VERSION ""

NS_ :

BS_:

BU_: Turbocharger OnBoardDataLogger OffBoardDiagnosticTool2 OffBoardDiagnosticTool1 FileServer ParkingBrakeController SeatControl2 FanDriveController SteeringColumnUnit CommunicationUnitRadio CommunicationUnitSatellite CommunicationUnitCellular PropulsionBatteryCharger ChassisController2 ChassisController1 EngineValveControl AuxiliaryHeater2 AuxiliaryHeater1 ClutchUnit RampControl InformationSystem1 SuspensionSystemController2 OilSensor VehicleDynamicStability ExhaustEmissionController TransmissionDisplay2 TransmissionDisplay1 ClimateControl2 WaterPumpController RearAxleSteeringController LightingOperatorControl SeatController1 IgnitionController2 IgnitionController1 TirePressureController CabController2 CabController1 PneumaticSystemController SuspensionSystemController1 HydraulicPumpController EnduranceBrakingSystem RetarderExhaustEngine2 OnBoardDiagnosticUnit HeadwayController RetarderExhaustEngine1 CabDisplay1 ManagementComputer VirtualTerminal OffVehicleGateway PowerTakeOffFront HitchControl AuxiliaryValveControl BodyController TractorTrailerBridge1 StarterSystem ElectricalSystem VehicleSecurity VehicleNavigation AerodynamicControl ElectricalChargingSystem ClimateControl1 TripRecorder InstrumentCluster SuspensionDriveAxle2 SuspensionDriveAxle1 SuspensionSteerAxle SteeringController FuelSystem CruiseControl RetarderDriveline RetarderEngine BrakesDriveAxle2 BrakesDriveAxle1 BrakesSystemController BrakesSteerAxle AxleDrive2 AxleDrive1 AxleSteering PowerTakeOff ShiftConsoleSecondary ShiftConsolePrimary Transmission2 Transmission1 Engine2 Engine1

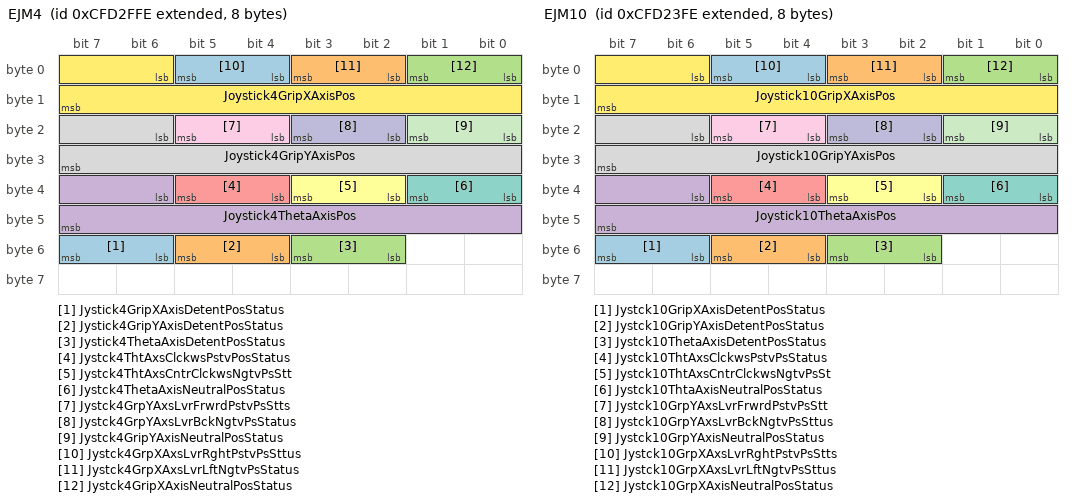
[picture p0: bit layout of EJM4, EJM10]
BO_ 2365403134 EJM4: 8 Vector__XXX
 SG_ Jystick4GripXAxisDetentPosStatus : 54|2@1+ (1,0) [0|3] "" Vector__XXX
 SG_ Jystick4GripYAxisDetentPosStatus : 52|2@1+ (1,0) [0|3] "" Vector__XXX
 SG_ Jystick4ThetaAxisDetentPosStatus : 50|2@1+ (1,0) [0|3] "" Vector__XXX
 SG_ Joystick4ThetaAxisPos : 38|10@1+ (1,0) [0|102] "%" Vector__XXX
 SG_ Jystck4ThtAxsClckwsPstvPosStatus : 36|2@1+ (1,0) [0|3] "" Vector__XXX
 SG_ Jystck4ThtAxsCntrClckwsNgtvPsStt : 34|2@1+ (1,0) [0|3] "" Vector__XXX
 SG_ Jystck4ThetaAxisNeutralPosStatus : 32|2@1+ (1,0) [0|3] "" Vector__XXX
 SG_ Joystick4GripYAxisPos : 22|10@1+ (1,0) [0|102] "%" Vector__XXX
 SG_ Jystck4GrpYAxsLvrFrwrdPstvPsStts : 20|2@1+ (1,0) [0|3] "" Vector__XXX
 SG_ Jystck4GrpYAxsLvrBckNgtvPsStatus : 18|2@1+ (1,0) [0|3] "" Vector__XXX
 SG_ Jystck4GripYAxisNeutralPosStatus : 16|2@1+ (1,0) [0|3] "" Vector__XXX
 SG_ Joystick4GripXAxisPos : 6|10@1+ (1,0) [0|102] "%" Vector__XXX
 SG_ Jystck4GrpXAxsLvrRghtPstvPsSttus : 4|2@1+ (1,0) [0|3] "" Vector__XXX
 SG_ Jystck4GrpXAxsLvrLftNgtvPsStatus : 2|2@1+ (1,0) [0|3] "" Vector__XXX
 SG_ Jystck4GripXAxisNeutralPosStatus : 0|2@1+ (1,0) [0|3] "" Vector__XXX

BO_ 2365400062 EJM10: 8 Vector__XXX
 SG_ Jystck10GripXAxisDetentPosStatus : 54|2@1+ (1,0) [0|3] "" Vector__XXX
 SG_ Jystck10GripYAxisDetentPosStatus : 52|2@1+ (1,0) [0|3] "" Vector__XXX
 SG_ Jystck10ThetaAxisDetentPosStatus : 50|2@1+ (1,0) [0|3] "" Vector__XXX
 SG_ Joystick10ThetaAxisPos : 38|10@1+ (1,0) [0|102] "%" Vector__XXX
 SG_ Jystck10ThtAxsClckwsPstvPsStatus : 36|2@1+ (1,0) [0|3] "" Vector__XXX
 SG_ Jystck10ThtAxsCntrClckwsNgtvPsSt : 34|2@1+ (1,0) [0|3] "" Vector__XXX
 SG_ Jystck10ThtaAxisNeutralPosStatus : 32|2@1+ (1,0) [0|3] "" Vector__XXX
 SG_ Joystick10GripYAxisPos : 22|10@1+ (1,0) [0|102] "%" Vector__XXX
 SG_ Jystck10GrpYAxsLvrFrwrdPstvPsStt : 20|2@1+ (1,0) [0|3] "" Vector__XXX
 SG_ Jystck10GrpYAxsLvrBckNgtvPsSttus : 18|2@1+ (1,0) [0|3] "" Vector__XXX
 SG_ Jystck10GrpYAxisNeutralPosStatus : 16|2@1+ (1,0) [0|3] "" Vector__XXX
 SG_ Joystick10GripXAxisPos : 6|10@1+ (1,0) [0|102] "%" Vector__XXX
 SG_ Jystck10GrpXAxsLvrRghtPstvPsStts : 4|2@1+ (1,0) [0|3] "" Vector__XXX
 SG_ Jystck10GrpXAxsLvrLftNgtvPsSttus : 2|2@1+ (1,0) [0|3] "" Vector__XXX
 SG_ Jystck10GrpXAxisNeutralPosStatus : 0|2@1+ (1,0) [0|3] "" Vector__XXX

BO_ 2566713598 EFS2: 8 Vector__XXX
 SG_ EngFuelFilterIntakeAbsPress : 0|8@1+ (2,0) [0|500] "kPa" Vector__XXX

BO_ 2499604478 EFL_P11: 8 Vector__XXX
 SG_ EngExhstGsRcrcltn1OutletAbsPress : 16|16@1+ (0.1,0) [0|6425.5] "kPa" Vector__XXX
 SG_ EngExhstGsRcrcltn1IntakeAbsPress : 0|16@1+ (0.1,0) [0|6425.5] "kPa" Vector__XXX

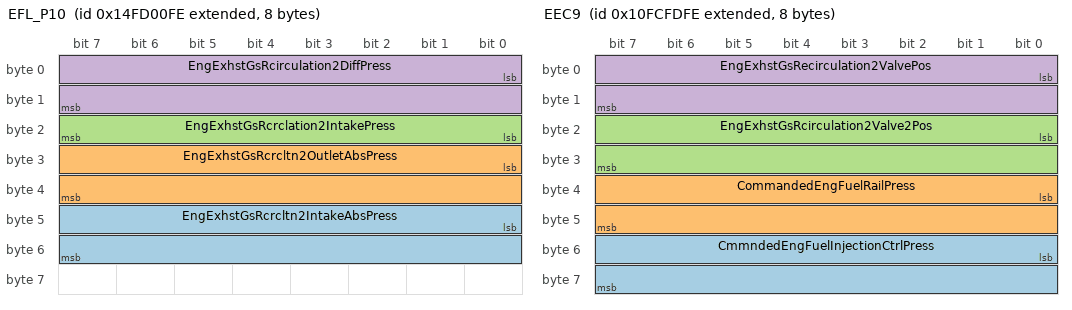
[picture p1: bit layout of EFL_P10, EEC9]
BO_ 2499608830 EFL_P10: 8 Vector__XXX
 SG_ EngExhstGsRcrcltn2IntakeAbsPress : 40|16@1+ (0.1,0) [0|6425.5] "kPa" Vector__XXX
 SG_ EngExhstGsRcrcltn2OutletAbsPress : 24|16@1+ (0.1,0) [0|6425.5] "kPa" Vector__XXX
 SG_ EngExhstGsRcrclation2IntakePress : 16|8@1+ (2,0) [0|500] "kPa" Vector__XXX
 SG_ EngExhstGsRcirculation2DiffPress : 0|16@1+ (0.0078124659559567,-250) [-250|251.99] "kPa" Vector__XXX

BO_ 2432499198 EEC9: 8 Vector__XXX
 SG_ CmmndedEngFuelInjectionCtrlPress : 48|16@1+ (0.0039063107929344,0) [0|251] "MPa" Vector__XXX
 SG_ CommandedEngFuelRailPress : 32|16@1+ (0.0039063107929344,0) [0|251] "MPa" Vector__XXX
 SG_ EngExhstGsRcirculation2Valve2Pos : 16|16@1+ (0.0025,0) [0|160.6375] "%" Vector__XXX
 SG_ EngExhstGsRecirculation2ValvePos : 0|16@1+ (0.0025,0) [0|160.6375] "%" Vector__XXX

BO_ 2633825022 EEC11: 8 Vector__XXX
 SG_ EngExhstGsRcrculation2Valve2Ctrl : 16|16@1+ (0.0025,0) [0|160.6375] "%" Vector__XXX
 SG_ EngExhstGsRcirculation2ValveCtrl : 0|16@1+ (0.0025,0) [0|160.6375] "%" Vector__XXX

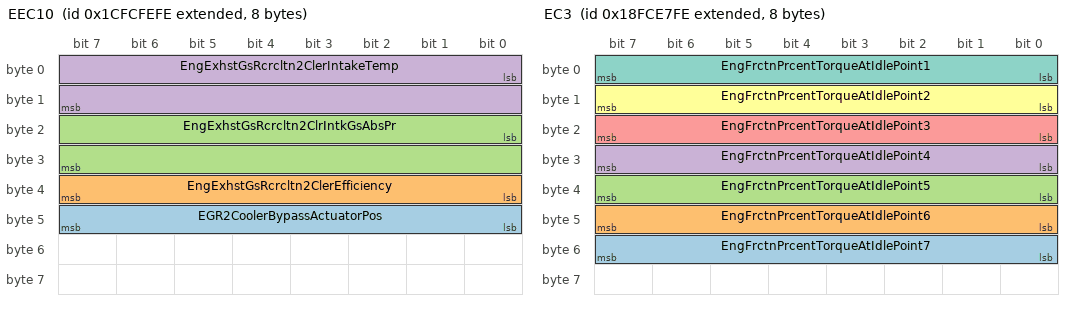
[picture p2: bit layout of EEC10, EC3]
BO_ 2633826046 EEC10: 8 Vector__XXX
 SG_ EGR2CoolerBypassActuatorPos : 40|8@1+ (0.4,0) [0|100] "%" Vector__XXX
 SG_ EngExhstGsRcrcltn2ClerEfficiency : 32|8@1+ (0.4,0) [0|100] "%" Vector__XXX
 SG_ EngExhstGsRcrcltn2ClrIntkGsAbsPr : 16|16@1+ (0.5,0) [0|32127.5] "kPa" Vector__XXX
 SG_ EngExhstGsRcrcltn2ClerIntakeTemp : 0|16@1+ (0.03125,-273) [-273|1734.96875] "deg C" Vector__XXX

BO_ 2566711294 EC3: 8 Vector__XXX
 SG_ EngFrctnPrcentTorqueAtIdlePoint7 : 48|8@1+ (1,-125) [-125|125] "%" Vector__XXX
 SG_ EngFrctnPrcentTorqueAtIdlePoint6 : 40|8@1+ (1,-125) [-125|125] "%" Vector__XXX
 SG_ EngFrctnPrcentTorqueAtIdlePoint5 : 32|8@1+ (1,-125) [-125|125] "%" Vector__XXX
 SG_ EngFrctnPrcentTorqueAtIdlePoint4 : 24|8@1+ (1,-125) [-125|125] "%" Vector__XXX
 SG_ EngFrctnPrcentTorqueAtIdlePoint3 : 16|8@1+ (1,-125) [-125|125] "%" Vector__XXX
 SG_ EngFrctnPrcentTorqueAtIdlePoint2 : 8|8@1+ (1,-125) [-125|125] "%" Vector__XXX
 SG_ EngFrctnPrcentTorqueAtIdlePoint1 : 0|8@1+ (1,-125) [-125|125] "%" Vector__XXX

BO_ 2566749438 DPFC1: 8 Vector__XXX
 SG_ DslPrtcltFltrActvRgnrtnFrcdSttus : 53|3@1+ (1,0) [0|7] "" Vector__XXX
 SG_ ExhaustSystemHighTempLampCmd : 50|3@1+ (1,0) [0|7] "" Vector__XXX
 SG_ DslPrtcltFltrAtmtcActvRgnrtnIntt : 48|2@1+ (1,0) [0|3] "" Vector__XXX
 SG_ DslPrtcltFltrActvRgnrtnInhbtdDTV : 46|2@1+ (1,0) [0|3] "" Vector__XXX
 SG_ DslPrtcltFltrActvRgnrtnInhbtdDTE : 44|2@1+ (1,0) [0|3] "" Vector__XXX
 SG_ DslPrtcltFltrActvRgnrtnInhb_0000 : 42|2@1+ (1,0) [0|3] "" Vector__XXX
 SG_ DslPrtcltFltrActvRgnrtnInhbtdDTT : 40|2@1+ (1,0) [0|3] "" Vector__XXX
 SG_ DslPrtcltFltrActvRgnrtn_DTS_02 : 38|2@1+ (1,0) [0|3] "" Vector__XXX
 SG_ DslPrtcltFltrActvRgnrtn_DTS_01 : 36|2@1+ (1,0) [0|3] "" Vector__XXX
 SG_ DslPrtcltFltrActvRgnrtnInhbtdDTL : 34|2@1+ (1,0) [0|3] "" Vector__XXX
 SG_ DslPrtcltFltrActvRgnrtnInhb_0001 : 32|2@1+ (1,0) [0|3] "" Vector__XXX
 SG_ DslPrtcltFltrActvRgnrtnInhb_0002 : 30|2@1+ (1,0) [0|3] "" Vector__XXX
 SG_ DslPrtcltFltrActvRgnrtnInhbtdDTO : 28|2@1+ (1,0) [0|3] "" Vector__XXX
 SG_ DslPrtcltFltrActvRgnrtnInhbtdDTA : 26|2@1+ (1,0) [0|3] "" Vector__XXX
 SG_ DslPrtcltFltrActvRgnrtnInhbtdDTP : 24|2@1+ (1,0) [0|3] "" Vector__XXX
 SG_ DslPrtcltFltrActvRgnrtnInhbtdDTS : 22|2@1+ (1,0) [0|3] "" Vector__XXX
 SG_ DslPrtcltFltrActvRgnrtnInhbtdDTC : 20|2@1+ (1,0) [0|3] "" Vector__XXX
 SG_ DslPrtcltFltrActvRgnrtnInhbtdDTI : 18|2@1+ (1,0) [0|3] "" Vector__XXX
 SG_ DslPrtcltFltrActvRgnrtnInhbtdStt : 16|2@1+ (1,0) [0|3] "" Vector__XXX
 SG_ DieselParticulateFilterStatus : 12|3@1+ (1,0) [0|7] "" Vector__XXX
 SG_ DslPrtcltFltrActvRgnrationStatus : 10|2@1+ (1,0) [0|3] "" Vector__XXX
 SG_ DslPrtcltFltrPssvRgnrationStatus : 8|2@1+ (1,0) [0|3] "" Vector__XXX
 SG_ DieselParticulateFilterLampCmd : 0|3@1+ (1,0) [0|7] "" Vector__XXX

BO_ 2566715646 DPF2S2: 8 Vector__XXX
 SG_ DslPrtculateFilter2SootSignalMin : 32|16@1+ (0.0025,0) [0|160.6375] "%" Vector__XXX
 SG_ DslPrtculateFilter2SootSignalMax : 16|16@1+ (0.0025,0) [0|160.6375] "%" Vector__XXX
 SG_ DslPrtcltFltr2StSgnlStndrdDvtion : 0|16@1+ (0.0025,0) [0|160.6375] "%" Vector__XXX

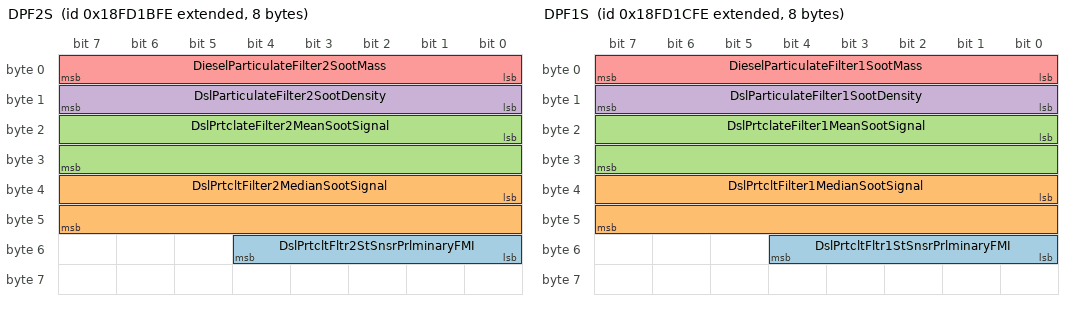
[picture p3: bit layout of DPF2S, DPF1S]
BO_ 2566724606 DPF2S: 8 Vector__XXX
 SG_ DslPrtcltFltr2StSnsrPrlminaryFMI : 48|5@1+ (1,0) [0|31] "" Vector__XXX
 SG_ DslPrtcltFilter2MedianSootSignal : 32|16@1+ (0.0025,0) [0|160.6375] "%" Vector__XXX
 SG_ DslPrtclateFilter2MeanSootSignal : 16|16@1+ (0.0025,0) [0|160.6375] "%" Vector__XXX
 SG_ DslParticulateFilter2SootDensity : 8|8@1+ (0.08,0) [0|20] "g/L" Vector__XXX
 SG_ DieselParticulateFilter2SootMass : 0|8@1+ (4,0) [0|1000] "g" Vector__XXX

BO_ 2566715902 DPF1S2: 8 Vector__XXX
 SG_ DslPrtculateFilter1SootSignalMin : 32|16@1+ (0.0025,0) [0|160.6375] "%" Vector__XXX
 SG_ DslPrtculateFilter1SootSignalMax : 16|16@1+ (0.0025,0) [0|160.6375] "%" Vector__XXX
 SG_ DslPrtcltFltr1StSgnlStndrdDvtion : 0|16@1+ (0.0025,0) [0|160.6375] "%" Vector__XXX

BO_ 2566724862 DPF1S: 8 Vector__XXX
 SG_ DslPrtcltFltr1StSnsrPrlminaryFMI : 48|5@1+ (1,0) [0|31] "" Vector__XXX
 SG_ DslPrtcltFilter1MedianSootSignal : 32|16@1+ (0.0025,0) [0|160.6375] "%" Vector__XXX
 SG_ DslPrtclateFilter1MeanSootSignal : 16|16@1+ (0.0025,0) [0|160.6375] "%" Vector__XXX
 SG_ DslParticulateFilter1SootDensity : 8|8@1+ (0.08,0) [0|20] "g/L" Vector__XXX
 SG_ DieselParticulateFilter1SootMass : 0|8@1+ (4,0) [0|1000] "g" Vector__XXX

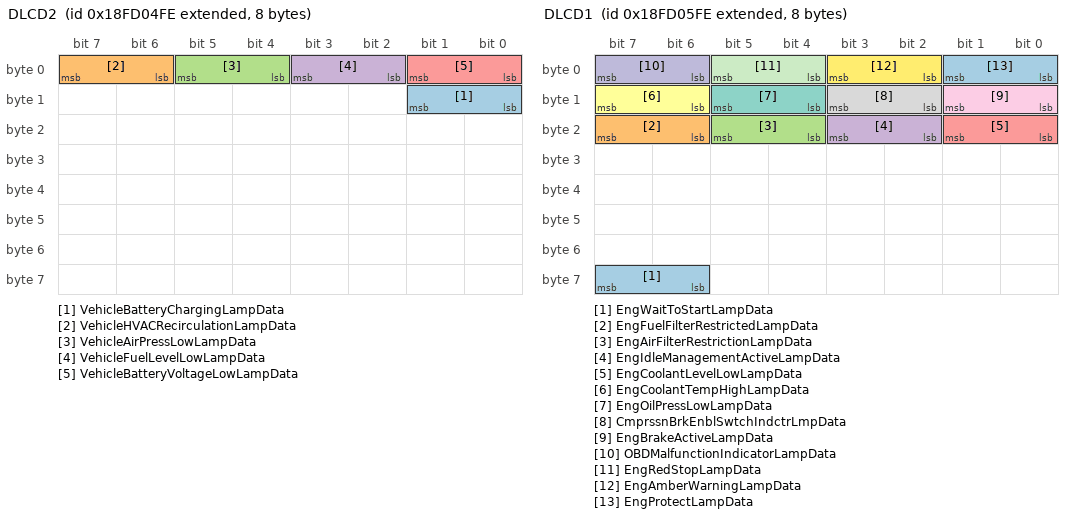
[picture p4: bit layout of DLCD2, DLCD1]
BO_ 2566718718 DLCD2: 8 Vector__XXX
 SG_ VehicleBatteryChargingLampData : 8|2@1+ (1,0) [0|3] "" Vector__XXX
 SG_ VehicleHVACRecirculationLampData : 6|2@1+ (1,0) [0|3] "" Vector__XXX
 SG_ VehicleAirPressLowLampData : 4|2@1+ (1,0) [0|3] "" Vector__XXX
 SG_ VehicleFuelLevelLowLampData : 2|2@1+ (1,0) [0|3] "" Vector__XXX
 SG_ VehicleBatteryVoltageLowLampData : 0|2@1+ (1,0) [0|3] "" Vector__XXX

BO_ 2566718974 DLCD1: 8 Vector__XXX
 SG_ EngWaitToStartLampData : 62|2@1+ (1,0) [0|3] "" Vector__XXX
 SG_ EngFuelFilterRestrictedLampData : 22|2@1+ (1,0) [0|3] "" Vector__XXX
 SG_ EngAirFilterRestrictionLampData : 20|2@1+ (1,0) [0|3] "" Vector__XXX
 SG_ EngIdleManagementActiveLampData : 18|2@1+ (1,0) [0|3] "" Vector__XXX
 SG_ EngCoolantLevelLowLampData : 16|2@1+ (1,0) [0|3] "" Vector__XXX
 SG_ EngCoolantTempHighLampData : 14|2@1+ (1,0) [0|3] "" Vector__XXX
 SG_ EngOilPressLowLampData : 12|2@1+ (1,0) [0|3] "" Vector__XXX
 SG_ CmprssnBrkEnblSwtchIndctrLmpData : 10|2@1+ (1,0) [0|3] "" Vector__XXX
 SG_ EngBrakeActiveLampData : 8|2@1+ (1,0) [0|3] "" Vector__XXX
 SG_ OBDMalfunctionIndicatorLampData : 6|2@1+ (1,0) [0|3] "" Vector__XXX
 SG_ EngRedStopLampData : 4|2@1+ (1,0) [0|3] "" Vector__XXX
 SG_ EngAmberWarningLampData : 2|2@1+ (1,0) [0|3] "" Vector__XXX
 SG_ EngProtectLampData : 0|2@1+ (1,0) [0|3] "" Vector__XXX

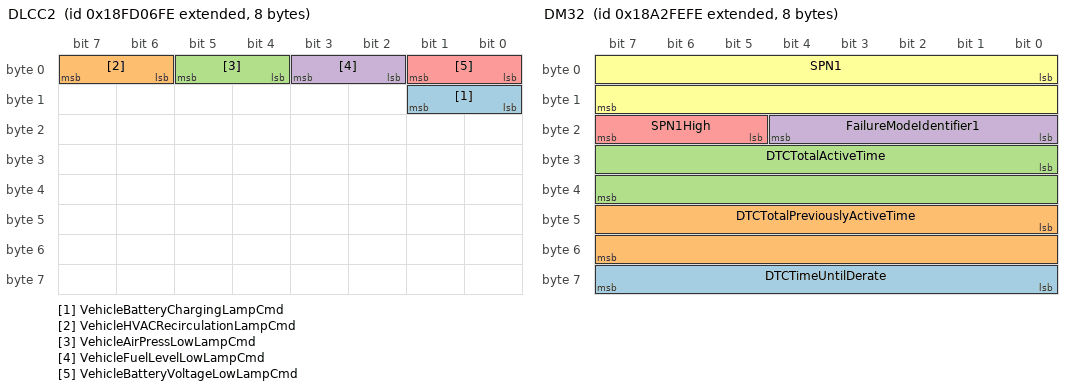
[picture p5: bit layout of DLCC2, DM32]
BO_ 2566719230 DLCC2: 8 Vector__XXX
 SG_ VehicleBatteryChargingLampCmd : 8|2@1+ (1,0) [0|3] "" Vector__XXX
 SG_ VehicleHVACRecirculationLampCmd : 6|2@1+ (1,0) [0|3] "" Vector__XXX
 SG_ VehicleAirPressLowLampCmd : 4|2@1+ (1,0) [0|3] "" Vector__XXX
 SG_ VehicleFuelLevelLowLampCmd : 2|2@1+ (1,0) [0|3] "" Vector__XXX
 SG_ VehicleBatteryVoltageLowLampCmd : 0|2@1+ (1,0) [0|3] "" Vector__XXX

BO_ 2560818942 DM32: 8 Vector__XXX
 SG_ DTCTimeUntilDerate : 56|8@1+ (0.25,0) [0|62.5] "hr" Vector__XXX
 SG_ DTCTotalPreviouslyActiveTime : 40|16@1+ (0.2,0) [0|12851] "hr" Vector__XXX
 SG_ DTCTotalActiveTime : 24|16@1+ (0.2,0) [0|12851] "hr" Vector__XXX
 SG_ FailureModeIdentifier1 : 16|5@1+ (1,0) [0|0] "" Vector__XXX
 SG_ SPN1High : 21|3@1+ (1,0) [0|7] "" Vector__XXX
 SG_ SPN1 : 0|16@1+ (1,0) [0|65536] "" Vector__XXX

BO_ 2561212158 DISP1: 8 Vector__XXX
 SG_ TextDisplayIndex : 16|8@1+ (1,0) [0|250] "" Vector__XXX
 SG_ TextDisplayInstructions : 0|4@1+ (1,0) [0|15] "" Vector__XXX

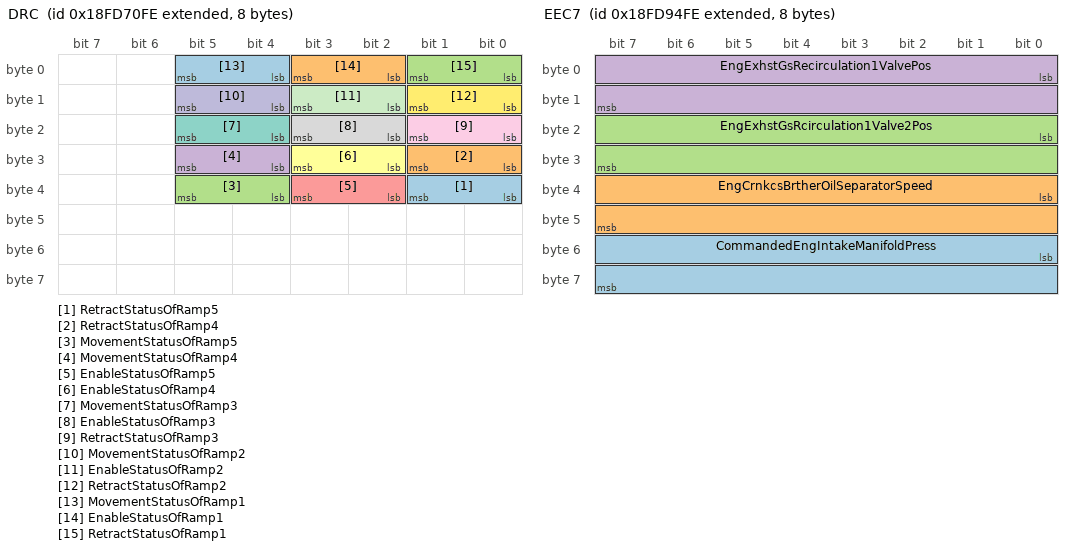
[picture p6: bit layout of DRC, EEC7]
BO_ 2566746366 DRC: 8 Vector__XXX
 SG_ RetractStatusOfRamp5 : 32|2@1+ (1,0) [0|3] "" Vector__XXX
 SG_ RetractStatusOfRamp4 : 24|2@1+ (1,0) [0|3] "" Vector__XXX
 SG_ MovementStatusOfRamp5 : 36|2@1+ (1,0) [0|3] "" Vector__XXX
 SG_ MovementStatusOfRamp4 : 28|2@1+ (1,0) [0|3] "" Vector__XXX
 SG_ EnableStatusOfRamp5 : 34|2@1+ (1,0) [0|3] "" Vector__XXX
 SG_ EnableStatusOfRamp4 : 26|2@1+ (1,0) [0|3] "" Vector__XXX
 SG_ MovementStatusOfRamp3 : 20|2@1+ (1,0) [0|3] "" Vector__XXX
 SG_ EnableStatusOfRamp3 : 18|2@1+ (1,0) [0|3] "" Vector__XXX
 SG_ RetractStatusOfRamp3 : 16|2@1+ (1,0) [0|3] "" Vector__XXX
 SG_ MovementStatusOfRamp2 : 12|2@1+ (1,0) [0|3] "" Vector__XXX
 SG_ EnableStatusOfRamp2 : 10|2@1+ (1,0) [0|3] "" Vector__XXX
 SG_ RetractStatusOfRamp2 : 8|2@1+ (1,0) [0|3] "" Vector__XXX
 SG_ MovementStatusOfRamp1 : 4|2@1+ (1,0) [0|3] "" Vector__XXX
 SG_ EnableStatusOfRamp1 : 2|2@1+ (1,0) [0|3] "" Vector__XXX
 SG_ RetractStatusOfRamp1 : 0|2@1+ (1,0) [0|3] "" Vector__XXX

BO_ 2566750206 EC2: 8 Vector__XXX
 SG_ MaxCrankAttemptsPerStartAttempt : 0|8@1+ (1,0) [0|250] "" Vector__XXX

BO_ 2566755582 EEC7: 8 Vector__XXX
 SG_ CommandedEngIntakeManifoldPress : 48|16@1+ (0.125,0) [0|8031.875] "kPa" Vector__XXX
 SG_ EngCrnkcsBrtherOilSeparatorSpeed : 32|16@1+ (1,0) [0|64255] "rpm" Vector__XXX
 SG_ EngExhstGsRcirculation1Valve2Pos : 16|16@1+ (0.0025,0) [0|160.6375] "%" Vector__XXX
 SG_ EngExhstGsRecirculation1ValvePos : 0|16@1+ (0.0025,0) [0|160.6375] "%" Vector__XXX

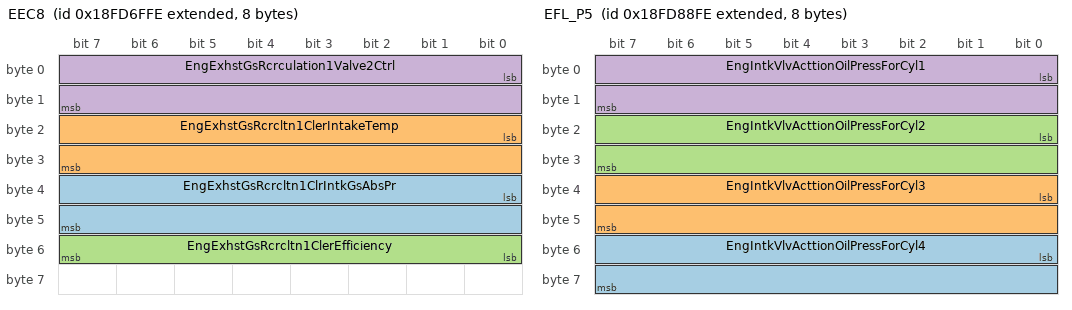
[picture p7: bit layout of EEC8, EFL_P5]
BO_ 2566746110 EEC8: 8 Vector__XXX
 SG_ EngExhstGsRcrcltn1ClrIntkGsAbsPr : 32|16@1+ (0.5,0) [0|32127.5] "kPa" Vector__XXX
 SG_ EngExhstGsRcrcltn1ClerIntakeTemp : 16|16@1+ (0.03125,-273) [-273|1734.96875] "deg C" Vector__XXX
 SG_ EngExhstGsRcrcltn1ClerEfficiency : 48|8@1+ (1,0) [0|100] "%" Vector__XXX
 SG_ EngExhstGsRcrculation1Valve2Ctrl : 0|16@1+ (1,0) [0|160.6375] "%" Vector__XXX

BO_ 2566752510 EFL_P5: 8 Vector__XXX
 SG_ EngIntkVlvActtionOilPressForCyl4 : 48|16@1+ (0.1,0) [0|6425.5] "kPa" Vector__XXX
 SG_ EngIntkVlvActtionOilPressForCyl3 : 32|16@1+ (0.1,0) [0|6425.5] "kPa" Vector__XXX
 SG_ EngIntkVlvActtionOilPressForCyl2 : 16|16@1+ (0.1,0) [0|6425.5] "kPa" Vector__XXX
 SG_ EngIntkVlvActtionOilPressForCyl1 : 0|16@1+ (0.1,0) [0|6425.5] "kPa" Vector__XXX

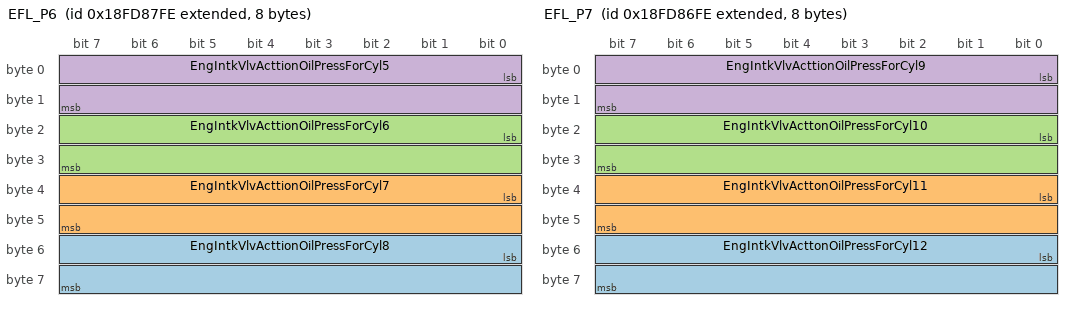
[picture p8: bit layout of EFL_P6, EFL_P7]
BO_ 2566752254 EFL_P6: 8 Vector__XXX
 SG_ EngIntkVlvActtionOilPressForCyl8 : 48|16@1+ (0.1,0) [0|6425.5] "kPa" Vector__XXX
 SG_ EngIntkVlvActtionOilPressForCyl7 : 32|16@1+ (0.1,0) [0|6425.5] "kPa" Vector__XXX
 SG_ EngIntkVlvActtionOilPressForCyl6 : 16|16@1+ (0.1,0) [0|6425.5] "kPa" Vector__XXX
 SG_ EngIntkVlvActtionOilPressForCyl5 : 0|16@1+ (0.1,0) [0|6425.5] "kPa" Vector__XXX

BO_ 2566751998 EFL_P7: 8 Vector__XXX
 SG_ EngIntkVlvActtonOilPressForCyl12 : 48|16@1+ (0.1,0) [0|6425.5] "kPa" Vector__XXX
 SG_ EngIntkVlvActtonOilPressForCyl11 : 32|16@1+ (0.1,0) [0|6425.5] "kPa" Vector__XXX
 SG_ EngIntkVlvActtonOilPressForCyl10 : 16|16@1+ (0.1,0) [0|6425.5] "kPa" Vector__XXX
 SG_ EngIntkVlvActtionOilPressForCyl9 : 0|16@1+ (0.1,0) [0|6425.5] "kPa" Vector__XXX

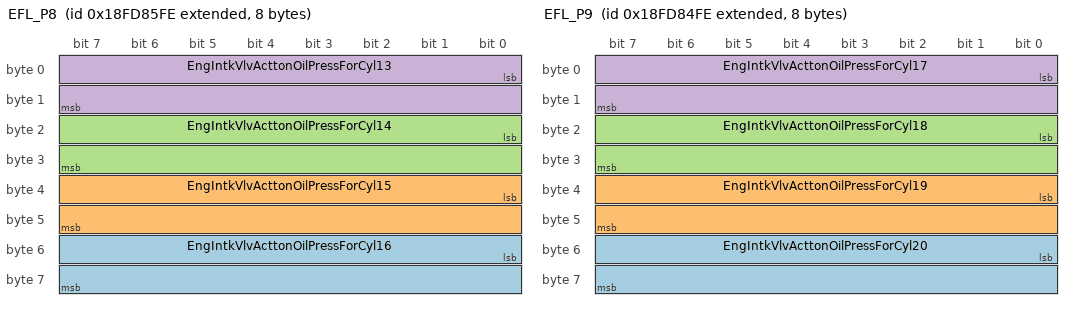
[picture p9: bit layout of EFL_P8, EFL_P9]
BO_ 2566751742 EFL_P8: 8 Vector__XXX
 SG_ EngIntkVlvActtonOilPressForCyl16 : 48|16@1+ (0.1,0) [0|6425.5] "kPa" Vector__XXX
 SG_ EngIntkVlvActtonOilPressForCyl15 : 32|16@1+ (0.1,0) [0|6425.5] "kPa" Vector__XXX
 SG_ EngIntkVlvActtonOilPressForCyl14 : 16|16@1+ (0.1,0) [0|6425.5] "kPa" Vector__XXX
 SG_ EngIntkVlvActtonOilPressForCyl13 : 0|16@1+ (0.1,0) [0|6425.5] "kPa" Vector__XXX

BO_ 2566751486 EFL_P9: 8 Vector__XXX
 SG_ EngIntkVlvActtonOilPressForCyl20 : 48|16@1+ (0.1,0) [0|6425.5] "kPa" Vector__XXX
 SG_ EngIntkVlvActtonOilPressForCyl19 : 32|16@1+ (0.1,0) [0|6425.5] "kPa" Vector__XXX
 SG_ EngIntkVlvActtonOilPressForCyl18 : 16|16@1+ (0.1,0) [0|6425.5] "kPa" Vector__XXX
 SG_ EngIntkVlvActtonOilPressForCyl17 : 0|16@1+ (0.1,0) [0|6425.5] "kPa" Vector__XXX

BO_ 2499641854 EGRBV: 8 Vector__XXX
 SG_ EGR1CoolerBypassActuatorPostion : 0|8@1+ (0.4,0) [0|100] "%" Vector__XXX

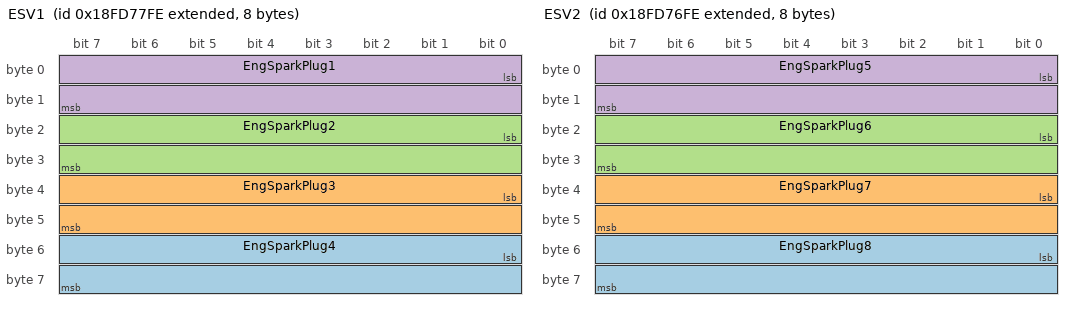
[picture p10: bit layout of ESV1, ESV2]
BO_ 2566748158 ESV1: 8 Vector__XXX
 SG_ EngSparkPlug4 : 48|16@1+ (1,0) [0|64255] "Volts" Vector__XXX
 SG_ EngSparkPlug3 : 32|16@1+ (1,0) [0|64255] "Volts" Vector__XXX
 SG_ EngSparkPlug2 : 16|16@1+ (1,0) [0|64255] "Volts" Vector__XXX
 SG_ EngSparkPlug1 : 0|16@1+ (1,0) [0|64255] "Volts" Vector__XXX

BO_ 2566747902 ESV2: 8 Vector__XXX
 SG_ EngSparkPlug8 : 48|16@1+ (1,0) [0|64255] "Volts" Vector__XXX
 SG_ EngSparkPlug7 : 32|16@1+ (1,0) [0|64255] "Volts" Vector__XXX
 SG_ EngSparkPlug6 : 16|16@1+ (1,0) [0|64255] "Volts" Vector__XXX
 SG_ EngSparkPlug5 : 0|16@1+ (1,0) [0|64255] "Volts" Vector__XXX

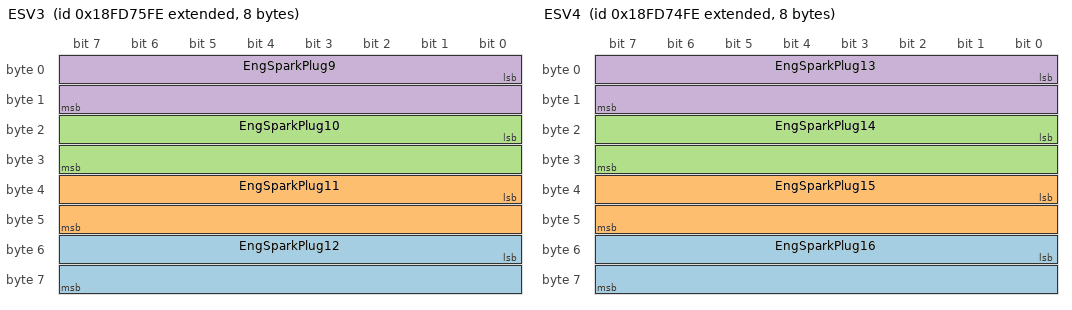
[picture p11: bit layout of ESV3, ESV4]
BO_ 2566747646 ESV3: 8 Vector__XXX
 SG_ EngSparkPlug12 : 48|16@1+ (1,0) [0|64255] "Volts" Vector__XXX
 SG_ EngSparkPlug11 : 32|16@1+ (1,0) [0|64255] "Volts" Vector__XXX
 SG_ EngSparkPlug10 : 16|16@1+ (1,0) [0|64255] "Volts" Vector__XXX
 SG_ EngSparkPlug9 : 0|16@1+ (1,0) [0|64255] "Volts" Vector__XXX

BO_ 2566747390 ESV4: 8 Vector__XXX
 SG_ EngSparkPlug16 : 48|16@1+ (1,0) [0|64255] "Volts" Vector__XXX
 SG_ EngSparkPlug15 : 32|16@1+ (1,0) [0|64255] "Volts" Vector__XXX
 SG_ EngSparkPlug14 : 16|16@1+ (1,0) [0|64255] "Volts" Vector__XXX
 SG_ EngSparkPlug13 : 0|16@1+ (1,0) [0|64255] "Volts" Vector__XXX

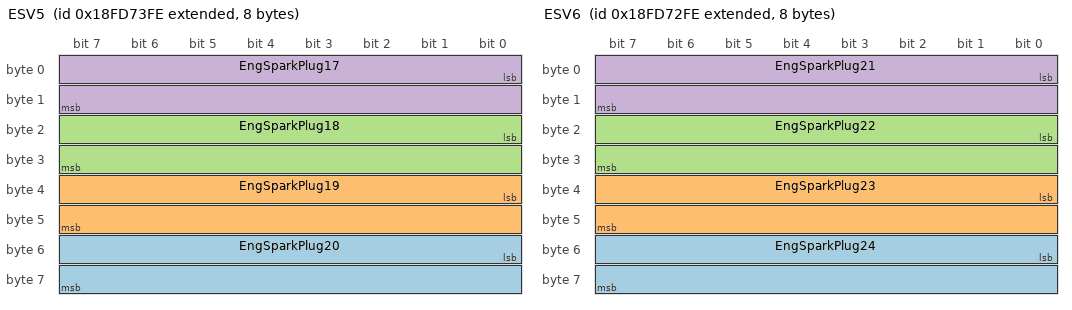
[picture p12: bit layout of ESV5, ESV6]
BO_ 2566747134 ESV5: 8 Vector__XXX
 SG_ EngSparkPlug20 : 48|16@1+ (1,0) [0|64255] "Volts" Vector__XXX
 SG_ EngSparkPlug19 : 32|16@1+ (1,0) [0|64255] "Volts" Vector__XXX
 SG_ EngSparkPlug18 : 16|16@1+ (1,0) [0|64255] "Volts" Vector__XXX
 SG_ EngSparkPlug17 : 0|16@1+ (1,0) [0|64255] "Volts" Vector__XXX

BO_ 2566746878 ESV6: 8 Vector__XXX
 SG_ EngSparkPlug24 : 48|16@1+ (1,0) [0|64255] "Volts" Vector__XXX
 SG_ EngSparkPlug23 : 32|16@1+ (1,0) [0|64255] "Volts" Vector__XXX
 SG_ EngSparkPlug22 : 16|16@1+ (1,0) [0|64255] "Volts" Vector__XXX
 SG_ EngSparkPlug21 : 0|16@1+ (1,0) [0|64255] "Volts" Vector__XXX

BO_ 2561277694 FLIC: 8 Vector__XXX
 SG_ LaneDepartureWarningEnableCmd : 0|2@1+ (1,0) [0|3] "" Vector__XXX

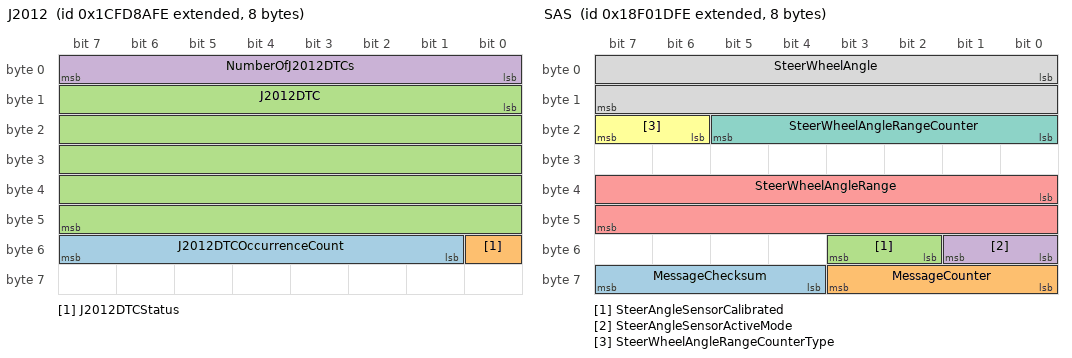
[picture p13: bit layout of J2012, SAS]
BO_ 2633861886 J2012: 8 Vector__XXX
 SG_ J2012DTCOccurrenceCount : 49|7@1+ (1,0) [0|127] "" Vector__XXX
 SG_ J2012DTCStatus : 48|1@1+ (1,0) [0|1] "" Vector__XXX
 SG_ J2012DTC : 8|40@1+ (1,0) [0|255] "per byte" Vector__XXX
 SG_ NumberOfJ2012DTCs : 0|8@1+ (1,0) [0|250] "" Vector__XXX

BO_ 2565873150 SAS: 8 Vector__XXX
 SG_ MessageChecksum : 60|4@1+ (1,0) [0|15] "" Vector__XXX
 SG_ MessageCounter : 56|4@1+ (1,0) [0|15] "" Vector__XXX
 SG_ SteerAngleSensorCalibrated : 50|2@1+ (1,0) [0|3] "" Vector__XXX
 SG_ SteerAngleSensorActiveMode : 48|2@1+ (1,0) [0|3] "" Vector__XXX
 SG_ SteerWheelAngleRange : 32|16@1+ (0.00097654657225119,-31.374) [-31.374|31.374] "rad" Vector__XXX
 SG_ SteerWheelAngleRangeCounterType : 22|2@1+ (1,0) [0|3] "" Vector__XXX
 SG_ SteerWheelAngleRangeCounter : 16|6@1+ (1,-32) [-32|29] "ranges" Vector__XXX
 SG_ SteerWheelAngle : 0|16@1+ (0.00097654657225119,-31.374) [-31.374|31.374] "rad" Vector__XXX

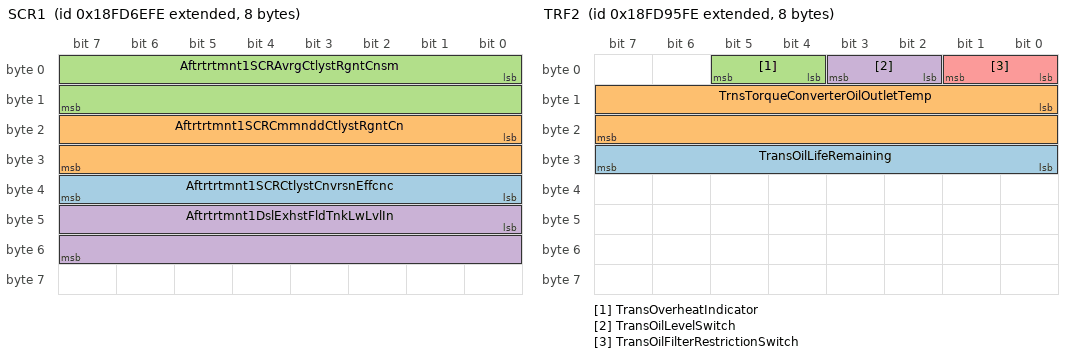
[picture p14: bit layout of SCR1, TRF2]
BO_ 2566745854 SCR1: 8 Vector__XXX
 SG_ Aftrtrtmnt1SCRCtlystCnvrsnEffcnc : 32|8@1+ (0.4,0) [0|100] "%" Vector__XXX
 SG_ Aftrtrtmnt1SCRCmmnddCtlystRgntCn : 16|16@1+ (1,0) [0|3212.75] "L/h" Vector__XXX
 SG_ Aftrtrtmnt1SCRAvrgCtlystRgntCnsm : 0|16@1+ (0.05,0) [0|3212.75] "L/h" Vector__XXX
 SG_ Aftrtrtmnt1DslExhstFldTnkLwLvlIn : 40|16@1+ (1,0) [0|64255] "km" Vector__XXX

BO_ 2566751230 TCI: 8 Vector__XXX
 SG_ TransferCaseStatus : 0|3@1+ (1,0) [0|7] "" Vector__XXX

BO_ 2566755838 TRF2: 8 Vector__XXX
 SG_ TransOilLifeRemaining : 24|8@1+ (0.4,0) [0|100] "%" Vector__XXX
 SG_ TrnsTorqueConverterOilOutletTemp : 8|16@1+ (0.03125,-273) [-273|1734.96875] "deg C" Vector__XXX
 SG_ TransOverheatIndicator : 4|2@1+ (1,0) [0|3] "" Vector__XXX
 SG_ TransOilLevelSwitch : 2|2@1+ (1,0) [0|3] "" Vector__XXX
 SG_ TransOilFilterRestrictionSwitch : 0|2@1+ (1,0) [0|3] "" Vector__XXX

BO_ 2566752766 VDS2: 8 Vector__XXX
 SG_ VehicleRoll : 0|16@1+ (0.0078124659559567,-200) [-200|301.99] "deg" Vector__XXX

BO_ 2633938942 LF: 10 Vector__XXX
 SG_ TotalEngCruiseTime : 48|32@1+ (0.05,0) [0|210554060.75] "hr" Vector__XXX
 SG_ TotalDriveAverageLoadFactor : 40|8@1+ (0.4,0) [0|100] "%" Vector__XXX
 SG_ TripDriveAverageLoadFactor : 32|8@1+ (0.4,0) [0|100] "%" Vector__XXX
 SG_ TripAverageEngSpeed : 16|16@1+ (0.125,0) [0|8031.875] "rpm" Vector__XXX
 SG_ TripMaxEngSpeed : 0|16@1+ (0.125,0) [0|8031.875] "rpm" Vector__XXX

BO_ 2566799614 LD: 8 Vector__XXX
 SG_ ImplementRearWorkLight : 62|2@1+ (1,0) [0|3] "" Vector__XXX
 SG_ ImplementLeftForwardWorkLight : 60|2@1+ (1,0) [0|3] "" Vector__XXX
 SG_ ImplementRightForwardWorkLight : 58|2@1+ (1,0) [0|3] "" Vector__XXX
 SG_ ImplementLeftFacingWorkLight : 54|2@1+ (1,0) [0|3] "" Vector__XXX
 SG_ ImplementRightFacingWorkLight : 52|2@1+ (1,0) [0|3] "" Vector__XXX
 SG_ ImplementOEMOption1Light : 50|2@1+ (1,0) [0|3] "" Vector__XXX
 SG_ ImplementOEMOption2Light : 48|2@1+ (1,0) [0|3] "" Vector__XXX
 SG_ TrctorFrontHighMountedWorkLights : 46|2@1+ (1,0) [0|3] "" Vector__XXX
 SG_ TractorFrontLowMountedWorkLights : 44|2@1+ (1,0) [0|3] "" Vector__XXX
 SG_ TractorSideHighMountedWorkLights : 42|2@1+ (1,0) [0|3] "" Vector__XXX
 SG_ TractorSideLowMountedWorkLights : 40|2@1+ (1,0) [0|3] "" Vector__XXX
 SG_ TractorRearHighMountedWorkLights : 38|2@1+ (1,0) [0|3] "" Vector__XXX
 SG_ TractorRearLowMountedWorkLights : 36|2@1+ (1,0) [0|3] "" Vector__XXX
 SG_ TrctorUndersideMountedWorkLights : 34|2@1+ (1,0) [0|3] "" Vector__XXX
 SG_ RearFogLights : 32|2@1+ (1,0) [0|3] "" Vector__XXX
 SG_ TractorMarkerLight : 30|2@1+ (1,0) [0|3] "" Vector__XXX
 SG_ ImplementMarkerLight : 28|2@1+ (1,0) [0|3] "" Vector__XXX
 SG_ TractorClearanceLight : 26|2@1+ (1,0) [0|3] "" Vector__XXX
 SG_ ImplementClearanceLight : 24|2@1+ (1,0) [0|3] "" Vector__XXX
 SG_ LeftStopLight : 22|2@1+ (1,0) [0|3] "" Vector__XXX
 SG_ RightStopLight : 20|2@1+ (1,0) [0|3] "" Vector__XXX
 SG_ CenterStopLight : 18|2@1+ (1,0) [0|3] "" Vector__XXX
 SG_ BackUpLightAndAlarmHorn : 16|2@1+ (1,0) [0|3] "" Vector__XXX
 SG_ LeftTurnSignalLights : 14|2@1+ (1,0) [0|3] "" Vector__XXX
 SG_ RightTurnSignalLights : 12|2@1+ (1,0) [0|3] "" Vector__XXX
 SG_ RotatingBeaconLight : 10|2@1+ (1,0) [0|3] "" Vector__XXX
 SG_ TractorFrontFogLights : 8|2@1+ (1,0) [0|3] "" Vector__XXX
 SG_ HighBeamHeadLightData : 6|2@1+ (1,0) [0|3] "" Vector__XXX
 SG_ LowBeamHeadLightData : 4|2@1+ (1,0) [0|3] "" Vector__XXX
 SG_ AltBeamHeadLightData : 2|2@1+ (1,0) [0|3] "" Vector__XXX
 SG_ RunningLight : 0|2@1+ (1,0) [0|3] "" Vector__XXX

BO_ 2365473278 LC: 8 Vector__XXX
 SG_ ImplementRearWorkLightCmd : 62|2@1+ (1,0) [0|3] "" Vector__XXX
 SG_ ImplementLeftForwardWorkLightCmd : 60|2@1+ (1,0) [0|3] "" Vector__XXX
 SG_ ImplmentRightForwardWorkLightCmd : 58|2@1+ (1,0) [0|3] "" Vector__XXX
 SG_ LightingDataRqCmd : 56|2@1+ (1,0) [0|3] "" Vector__XXX
 SG_ ImplementLeftFacingWorkLightCmd : 54|2@1+ (1,0) [0|3] "" Vector__XXX
 SG_ ImplementRightFacingWorkLightCmd : 52|2@1+ (1,0) [0|3] "" Vector__XXX
 SG_ ImplementOEMOption1LightCmd : 50|2@1+ (1,0) [0|3] "" Vector__XXX
 SG_ ImplementOEMOption2LightCmd : 48|2@1+ (1,0) [0|3] "" Vector__XXX
 SG_ TrctrFrntHghMountedWorkLightsCmd : 46|2@1+ (1,0) [0|3] "" Vector__XXX
 SG_ TrctrFrntLowMountedWorkLightsCmd : 44|2@1+ (1,0) [0|3] "" Vector__XXX
 SG_ TrctrSdeHighMountedWorkLightsCmd : 42|2@1+ (1,0) [0|3] "" Vector__XXX
 SG_ TrctrSideLowMountedWorkLightsCmd : 40|2@1+ (1,0) [0|3] "" Vector__XXX
 SG_ TrctrRarHighMountedWorkLightsCmd : 38|2@1+ (1,0) [0|3] "" Vector__XXX
 SG_ TrctrRearLowMountedWorkLightsCmd : 36|2@1+ (1,0) [0|3] "" Vector__XXX
 SG_ TrctrUndrsdeMountedWorkLightsCmd : 34|2@1+ (1,0) [0|3] "" Vector__XXX
 SG_ RearFogLightCmd : 32|2@1+ (1,0) [0|3] "" Vector__XXX
 SG_ TractorMarkerLightCmd : 30|2@1+ (1,0) [0|3] "" Vector__XXX
 SG_ ImplementMarkerLightCmd : 28|2@1+ (1,0) [0|3] "" Vector__XXX
 SG_ TractorClearanceLightCmd : 26|2@1+ (1,0) [0|3] "" Vector__XXX
 SG_ ImplementClearanceLightCmd : 24|2@1+ (1,0) [0|3] "" Vector__XXX
 SG_ LeftStopLightCmd : 22|2@1+ (1,0) [0|3] "" Vector__XXX
 SG_ RightStopLightCmd : 20|2@1+ (1,0) [0|3] "" Vector__XXX
 SG_ CenterStopLightCmd : 18|2@1+ (1,0) [0|3] "" Vector__XXX
 SG_ BackUpLightAndAlarmHornCmd : 16|2@1+ (1,0) [0|3] "" Vector__XXX
 SG_ LeftTurnSignalLightsCmd : 14|2@1+ (1,0) [0|3] "" Vector__XXX
 SG_ RightTurnSignalLightsCmd : 12|2@1+ (1,0) [0|3] "" Vector__XXX
 SG_ RotatingBeaconLightCmd : 10|2@1+ (1,0) [0|3] "" Vector__XXX
 SG_ TractorFrontFogLightsCmd : 8|2@1+ (1,0) [0|3] "" Vector__XXX
 SG_ HighBeamHeadLightCmd : 6|2@1+ (1,0) [0|3] "" Vector__XXX
 SG_ LowBeamHeadLightCmd : 4|2@1+ (1,0) [0|3] "" Vector__XXX
 SG_ AltBeamHeadLightCmd : 2|2@1+ (1,0) [0|3] "" Vector__XXX
 SG_ RunningLightCmd : 0|2@1+ (1,0) [0|3] "" Vector__XXX

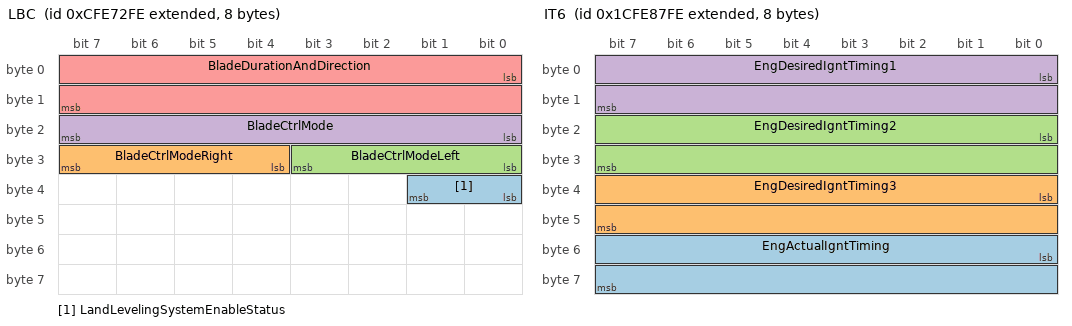
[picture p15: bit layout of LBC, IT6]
BO_ 2365485822 LBC: 8 Vector__XXX
 SG_ LandLevelingSystemEnableStatus : 32|2@1+ (1,0) [0|3] "" Vector__XXX
 SG_ BladeCtrlModeRight : 28|4@1+ (1,0) [0|15] "" Vector__XXX
 SG_ BladeCtrlModeLeft : 24|4@1+ (1,0) [0|15] "" Vector__XXX
 SG_ BladeCtrlMode : 16|8@1+ (1,0) [0|255] "" Vector__XXX
 SG_ BladeDurationAndDirection : 0|16@1+ (1,-3276.8) [-3276.8|3148.7] "sec" Vector__XXX

BO_ 2633926654 IT6: 8 Vector__XXX
 SG_ EngActualIgntTiming : 48|16@1+ (1,-200) [-200|301.99] "deg" Vector__XXX
 SG_ EngDesiredIgntTiming3 : 32|16@1+ (1,-200) [-200|301.99] "deg" Vector__XXX
 SG_ EngDesiredIgntTiming2 : 16|16@1+ (1,-200) [-200|301.99] "deg" Vector__XXX
 SG_ EngDesiredIgntTiming1 : 0|16@1+ (1,-200) [-200|301.99] "deg" Vector__XXX

BO_ 2633926398 IT5: 8 Vector__XXX
 SG_ EngCyl20IgntTiming : 48|16@1+ (1,-200) [-200|301.99] "deg" Vector__XXX
 SG_ EngCyl19IgntTiming : 32|16@1+ (1,-200) [-200|301.99] "deg" Vector__XXX
 SG_ EngCyl18IgntTiming : 16|16@1+ (1,-200) [-200|301.99] "deg" Vector__XXX
 SG_ EngCyl17IgntTiming : 0|16@1+ (1,-200) [-200|301.99] "deg" Vector__XXX

BO_ 2633926142 IT4: 8 Vector__XXX
 SG_ EngCyl16IgntTiming : 48|16@1+ (1,-200) [-200|301.99] "deg" Vector__XXX
 SG_ EngCyl15IgntTiming : 32|16@1+ (1,-200) [-200|301.99] "deg" Vector__XXX
 SG_ EngCyl14IgntTiming : 16|16@1+ (1,-200) [-200|301.99] "deg" Vector__XXX
 SG_ EngCyl13IgntTiming : 0|16@1+ (1,-200) [-200|301.99] "deg" Vector__XXX

BO_ 2633925886 IT3: 8 Vector__XXX
 SG_ EngCyl12IgntTiming : 48|16@1+ (1,-200) [-200|301.99] "deg" Vector__XXX
 SG_ EngCyl11IgntTiming : 32|16@1+ (1,-200) [-200|301.99] "deg" Vector__XXX
 SG_ EngCyl10IgntTiming : 16|16@1+ (1,-200) [-200|301.99] "deg" Vector__XXX
 SG_ EngCyl9IgntTiming : 0|16@1+ (1,-200) [-200|301.99] "deg" Vector__XXX

BO_ 2633925630 IT2: 8 Vector__XXX
 SG_ EngCyl8IgntTiming : 48|16@1+ (1,-200) [-200|301.99] "deg" Vector__XXX
 SG_ EngCyl7IgntTiming : 32|16@1+ (1,-200) [-200|301.99] "deg" Vector__XXX
 SG_ EngCyl6IgntTiming : 16|16@1+ (1,-200) [-200|301.99] "deg" Vector__XXX
 SG_ EngCyl5IgntTiming : 0|16@1+ (1,-200) [-200|301.99] "deg" Vector__XXX

BO_ 2633925374 IT1: 8 Vector__XXX
 SG_ EngCyl4IgntTiming : 48|16@1+ (1,-200) [-200|301.99] "deg" Vector__XXX
 SG_ EngCyl3IgntTiming : 32|16@1+ (1,-200) [-200|301.99] "deg" Vector__XXX
 SG_ EngCyl2IgntTiming : 16|16@1+ (1,-200) [-200|301.99] "deg" Vector__XXX
 SG_ EngCyl1IgntTiming : 0|16@1+ (1,-200) [-200|301.99] "deg" Vector__XXX

BO_ 2633927422 ISO3: 8 Vector__XXX
 SG_ EngCyl20IgntTransSecondOutput : 24|8@1+ (1,-125) [-125|125] "%" Vector__XXX
 SG_ EngCyl19IgntTransSecondOutput : 16|8@1+ (1,-125) [-125|125] "%" Vector__XXX
 SG_ EngCyl18IgntTransSecondOutput : 8|8@1+ (1,-125) [-125|125] "%" Vector__XXX
 SG_ EngCyl17IgntTransSecondOutput : 0|8@1+ (1,-125) [-125|125] "%" Vector__XXX

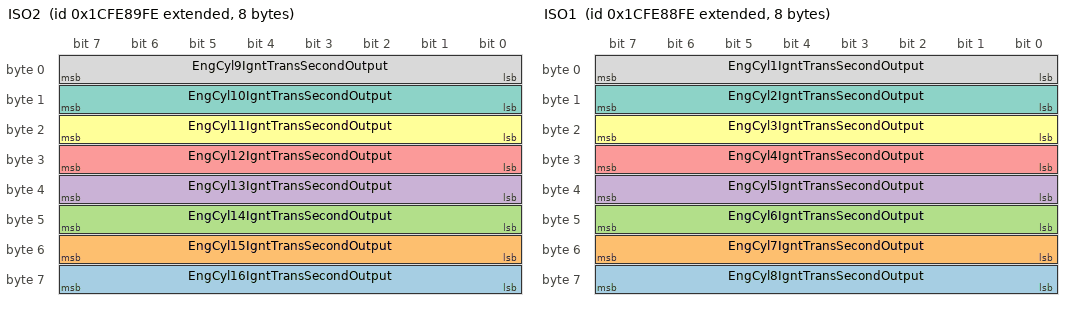
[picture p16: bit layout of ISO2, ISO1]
BO_ 2633927166 ISO2: 8 Vector__XXX
 SG_ EngCyl16IgntTransSecondOutput : 56|8@1+ (1,-125) [-125|125] "%" Vector__XXX
 SG_ EngCyl15IgntTransSecondOutput : 48|8@1+ (1,-125) [-125|125] "%" Vector__XXX
 SG_ EngCyl14IgntTransSecondOutput : 40|8@1+ (1,-125) [-125|125] "%" Vector__XXX
 SG_ EngCyl13IgntTransSecondOutput : 32|8@1+ (1,-125) [-125|125] "%" Vector__XXX
 SG_ EngCyl12IgntTransSecondOutput : 24|8@1+ (1,-125) [-125|125] "%" Vector__XXX
 SG_ EngCyl11IgntTransSecondOutput : 16|8@1+ (1,-125) [-125|125] "%" Vector__XXX
 SG_ EngCyl10IgntTransSecondOutput : 8|8@1+ (1,-125) [-125|125] "%" Vector__XXX
 SG_ EngCyl9IgntTransSecondOutput : 0|8@1+ (1,-125) [-125|125] "%" Vector__XXX

BO_ 2633926910 ISO1: 8 Vector__XXX
 SG_ EngCyl8IgntTransSecondOutput : 56|8@1+ (1,-125) [-125|125] "%" Vector__XXX
 SG_ EngCyl7IgntTransSecondOutput : 48|8@1+ (1,-125) [-125|125] "%" Vector__XXX
 SG_ EngCyl6IgntTransSecondOutput : 40|8@1+ (1,-125) [-125|125] "%" Vector__XXX
 SG_ EngCyl5IgntTransSecondOutput : 32|8@1+ (1,-125) [-125|125] "%" Vector__XXX
 SG_ EngCyl4IgntTransSecondOutput : 24|8@1+ (1,-125) [-125|125] "%" Vector__XXX
 SG_ EngCyl3IgntTransSecondOutput : 16|8@1+ (1,-125) [-125|125] "%" Vector__XXX
 SG_ EngCyl2IgntTransSecondOutput : 8|8@1+ (1,-125) [-125|125] "%" Vector__XXX
 SG_ EngCyl1IgntTransSecondOutput : 0|8@1+ (1,-125) [-125|125] "%" Vector__XXX

BO_ 2566768894 ISCS: 8 Vector__XXX
 SG_ EngOprtrPrmryIntrmdtSpdSlctState : 0|4@1+ (1,0) [0|15] "" Vector__XXX

BO_ 2566769406 ISC: 8 Vector__XXX
 SG_ EngOprtrPrmryIntrmdteSpeedSelect : 0|4@1+ (1,0) [0|15] "" Vector__XXX

BO_ 2566839550 IO: 8 Vector__XXX
 SG_ EngTotalIdleHours : 32|32@1+ (0.05,0) [0|210554060.75] "hr" Vector__XXX
 SG_ EngTotalIdleFuelUsed : 0|32@1+ (0.5,0) [0|2105540607.5] "L" Vector__XXX

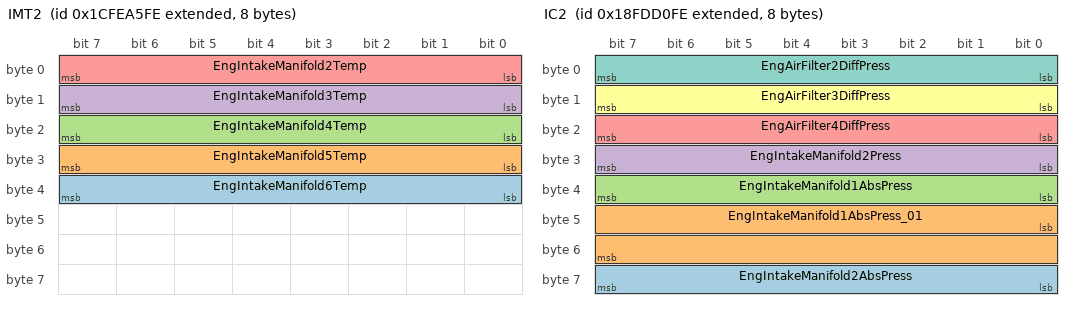
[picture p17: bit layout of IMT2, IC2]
BO_ 2633934334 IMT2: 8 Vector__XXX
 SG_ EngIntakeManifold6Temp : 32|8@1+ (1,-40) [-40|210] "deg C" Vector__XXX
 SG_ EngIntakeManifold5Temp : 24|8@1+ (1,-40) [-40|210] "deg C" Vector__XXX
 SG_ EngIntakeManifold4Temp : 16|8@1+ (1,-40) [-40|210] "deg C" Vector__XXX
 SG_ EngIntakeManifold3Temp : 8|8@1+ (1,-40) [-40|210] "deg C" Vector__XXX
 SG_ EngIntakeManifold2Temp : 0|8@1+ (1,-40) [-40|210] "deg C" Vector__XXX

BO_ 2566825726 IMT1: 8 Vector__XXX
 SG_ EngTurbo4BoostPress : 48|16@1+ (0.125,0) [0|8031.875] "kPa" Vector__XXX
 SG_ EngTurbo3BoostPress : 32|16@1+ (0.125,0) [0|8031.875] "kPa" Vector__XXX
 SG_ EngTurbo2BoostPress : 16|16@1+ (0.125,0) [0|8031.875] "kPa" Vector__XXX
 SG_ EngTurbo1BoostPress : 0|16@1+ (0.125,0) [0|8031.875] "kPa" Vector__XXX

BO_ 2566770942 IC2: 8 Vector__XXX
 SG_ EngIntakeManifold2AbsPress : 56|8@1+ (2,0) [0|500] "kPa" Vector__XXX
 SG_ EngIntakeManifold1AbsPress_01 : 40|16@1+ (0.1,0) [0|6425.5] "kPa" Vector__XXX
 SG_ EngIntakeManifold1AbsPress : 32|8@1+ (2,0) [0|500] "kPa" Vector__XXX
 SG_ EngIntakeManifold2Press : 24|8@1+ (2,0) [0|500] "kPa" Vector__XXX
 SG_ EngAirFilter4DiffPress : 16|8@1+ (0.05,0) [0|12.5] "kPa" Vector__XXX
 SG_ EngAirFilter3DiffPress : 8|8@1+ (0.05,0) [0|12.5] "kPa" Vector__XXX
 SG_ EngAirFilter2DiffPress : 0|8@1+ (0.05,0) [0|12.5] "kPa" Vector__XXX

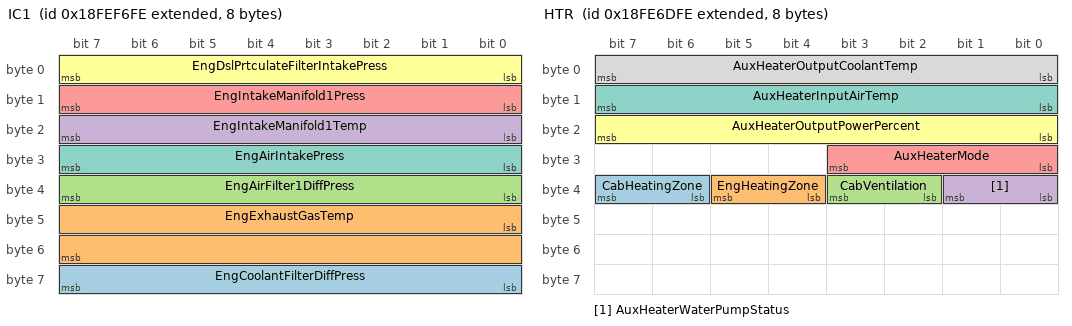
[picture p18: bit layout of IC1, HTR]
BO_ 2566846206 IC1: 8 Vector__XXX
 SG_ EngCoolantFilterDiffPress : 56|8@1+ (0.5,0) [0|125] "kPa" Vector__XXX
 SG_ EngExhaustGasTemp : 40|16@1+ (0.03125,-273) [-273|1734.96875] "deg C" Vector__XXX
 SG_ EngAirFilter1DiffPress : 32|8@1+ (0.05,0) [0|12.5] "kPa" Vector__XXX
 SG_ EngIntakeManifold1Temp : 16|8@1+ (1,-40) [-40|210] "deg C" Vector__XXX
 SG_ EngIntakeManifold1Press : 8|8@1+ (2,0) [0|500] "kPa" Vector__XXX
 SG_ EngDslPrtculateFilterIntakePress : 0|8@1+ (0.5,0) [0|125] "kPa" Vector__XXX
 SG_ EngAirIntakePress : 24|8@1+ (2,0) [0|500] "kPa" Vector__XXX

BO_ 2566811134 HTR: 8 Vector__XXX
 SG_ CabHeatingZone : 38|2@1+ (1,0) [0|3] "" Vector__XXX
 SG_ EngHeatingZone : 36|2@1+ (1,0) [0|3] "" Vector__XXX
 SG_ CabVentilation : 34|2@1+ (1,0) [0|3] "" Vector__XXX
 SG_ AuxHeaterWaterPumpStatus : 32|2@1+ (1,0) [0|3] "" Vector__XXX
 SG_ AuxHeaterMode : 24|4@1+ (1,0) [0|15] "" Vector__XXX
 SG_ AuxHeaterOutputPowerPercent : 16|8@1+ (0.4,0) [0|100] "%" Vector__XXX
 SG_ AuxHeaterInputAirTemp : 8|8@1+ (1,-40) [-40|210] "deg C" Vector__XXX
 SG_ AuxHeaterOutputCoolantTemp : 0|8@1+ (1,-40) [-40|210] "deg C" Vector__XXX

BO_ 2298375934 HRW: 8 Vector__XXX
 SG_ RearAxleRightWheelSpeed : 48|16@1+ (0.0039062485409696,0) [0|250.996] "km/h" Vector__XXX
 SG_ RearAxleLeftWheelSpeed : 32|16@1+ (0.0039062485409696,0) [0|250.996] "km/h" Vector__XXX
 SG_ FrontAxleRightWheelSpeed : 16|16@1+ (0.0039062485409696,0) [0|250.996] "km/h" Vector__XXX
 SG_ FrontAxleLeftWheelSpeed : 0|16@1+ (0.0039062485409696,0) [0|250.996] "km/h" Vector__XXX

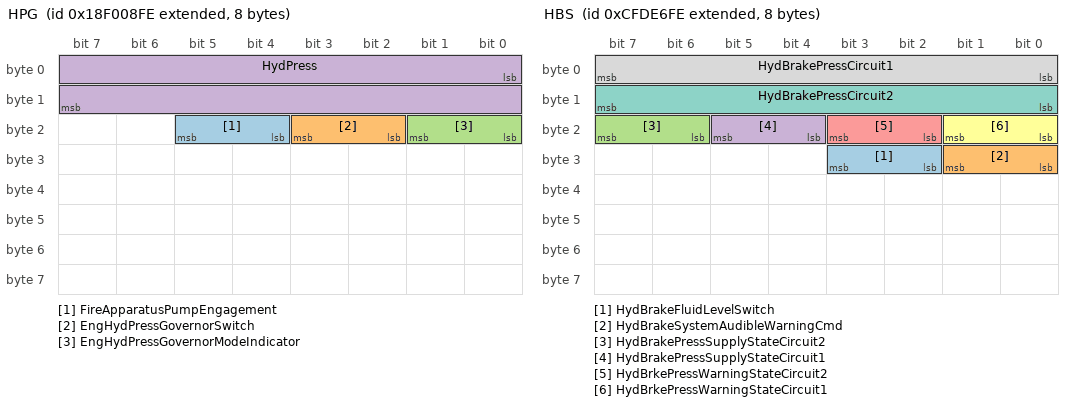
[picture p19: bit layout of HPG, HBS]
BO_ 2565867774 HPG: 8 Vector__XXX
 SG_ FireApparatusPumpEngagement : 20|2@1+ (1,0) [0|3] "" Vector__XXX
 SG_ EngHydPressGovernorSwitch : 18|2@1+ (1,0) [0|3] "" Vector__XXX
 SG_ EngHydPressGovernorModeIndicator : 16|2@1+ (1,0) [0|3] "" Vector__XXX
 SG_ HydPress : 0|16@1+ (2,0) [0|128510] "kPa" Vector__XXX

BO_ 2566841854 HOURS: 8 Vector__XXX
 SG_ EngTotalRevolutions : 32|32@1+ (1000,0) [0|4211081215000] "r" Vector__XXX
 SG_ EngTotalHoursOfOperation : 0|32@1+ (0.05,0) [0|210554060.75] "hr" Vector__XXX

BO_ 2365449982 HBS: 8 Vector__XXX
 SG_ HydBrakeFluidLevelSwitch : 26|2@1+ (1,0) [0|3] "" Vector__XXX
 SG_ HydBrakeSystemAudibleWarningCmd : 24|2@1+ (1,0) [0|3] "" Vector__XXX
 SG_ HydBrakePressSupplyStateCircuit2 : 22|2@1+ (1,0) [0|3] "" Vector__XXX
 SG_ HydBrakePressSupplyStateCircuit1 : 20|2@1+ (1,0) [0|3] "" Vector__XXX
 SG_ HydBrkePressWarningStateCircuit2 : 18|2@1+ (1,0) [0|3] "" Vector__XXX
 SG_ HydBrkePressWarningStateCircuit1 : 16|2@1+ (1,0) [0|3] "" Vector__XXX
 SG_ HydBrakePressCircuit2 : 8|8@1+ (0.1,0) [0|25] "MPa" Vector__XXX
 SG_ HydBrakePressCircuit1 : 0|8@1+ (0.1,0) [0|25] "MPa" Vector__XXX

CM_ BO_ 2365403134 "Extended Joystick Message 4";
CM_ SG_ 2365403134 Jystick4GripXAxisDetentPosStatus "Reports when the current joystick grip position is in the detent position for that axis of travel.";
CM_ SG_ 2365403134 Jystick4GripYAxisDetentPosStatus "Reports when the current joystick grip position is in the detent position for that axis of travel.";
CM_ SG_ 2365403134 Jystick4ThetaAxisDetentPosStatus "Reports when the current joystick position is in the detent position for that axis of travel.";
CM_ SG_ 2365403134 Joystick4ThetaAxisPos "The position of the joystick in the relative motion of travel from the neutral position. Position value of 0 is Neutral and";
CM_ SG_ 2365403134 Jystck4ThtAxsClckwsPstvPosStatus "Reports when the current joystick position is on the positive travel side (forward, right, clockwise, up) relative to the";
CM_ SG_ 2365403134 Jystck4ThtAxsCntrClckwsNgtvPsStt "Reports when the current joystick position is on the negative travel side (back, left, counterclockwise, down) relative to the";
CM_ SG_ 2365403134 Jystck4ThetaAxisNeutralPosStatus "Reports when the current joystick position is in the neutral position for that axis of travel. The neutral position";
CM_ SG_ 2365403134 Joystick4GripYAxisPos "The position of the joystick grip in the relative motion of travel from the neutral position. Position value of 0 is Neutral and";
CM_ SG_ 2365403134 Jystck4GrpYAxsLvrFrwrdPstvPsStts "Reports when the current joystick grip position is on the positive travel side (forward, right, clockwise, up) relative to the";
CM_ SG_ 2365403134 Jystck4GrpYAxsLvrBckNgtvPsStatus "Reports when the current joystick grip position is on the negative travel side (back, left, counterclockwise, down) relative";
CM_ SG_ 2365403134 Jystck4GripYAxisNeutralPosStatus "Reports when the current joystick grip position is in the neutral position for that axis of travel. The neutral position";
CM_ SG_ 2365403134 Joystick4GripXAxisPos "The position of the joystick grip in the relative motion of travel from the neutral position. Position value of 0 is Neutral and";
CM_ SG_ 2365403134 Jystck4GrpXAxsLvrRghtPstvPsSttus "Reports when the current joystick grip position is on the positive travel side (forward, right, clockwise, up) relative to the";
CM_ SG_ 2365403134 Jystck4GrpXAxsLvrLftNgtvPsStatus "Reports when the current joystick grip position is on the negative travel side (back, left, counterclockwise, down) relative";
CM_ SG_ 2365403134 Jystck4GripXAxisNeutralPosStatus "Reports when the current joystick grip position is in the neutral position for that axis of travel. The neutral position";
CM_ BO_ 2365400062 "Used to transfer information about the measured status of three additional axes of a joystick and switches of the joystick";
CM_ SG_ 2365400062 Jystck10GripXAxisDetentPosStatus "Reports when the current joystick grip position is in the detent position for that axis of travel.";
CM_ SG_ 2365400062 Jystck10GripYAxisDetentPosStatus "Reports when the current joystick grip position is in the detent position for that axis of travel.";
CM_ SG_ 2365400062 Jystck10ThetaAxisDetentPosStatus "Reports when the current joystick position is in the detent position for that axis of travel.";
CM_ SG_ 2365400062 Joystick10ThetaAxisPos "The position of the joystick in the relative motion of travel from the neutral position. Position value of 0 is Neutral and";
CM_ SG_ 2365400062 Jystck10ThtAxsClckwsPstvPsStatus "Reports when the current joystick position is on the positive travel side (forward, right, clockwise, up) relative to the";
CM_ SG_ 2365400062 Jystck10ThtAxsCntrClckwsNgtvPsSt "Reports when the current joystick position is on the negative travel side (back, left, counterclockwise, down) relative to the";
CM_ SG_ 2365400062 Jystck10ThtaAxisNeutralPosStatus "Reports when the current joystick position is in the neutral position for that axis of travel. The neutral position";
CM_ SG_ 2365400062 Joystick10GripYAxisPos "The position of the joystick grip in the relative motion of travel from the neutral position. Position value of 0 is Neutral and";
CM_ SG_ 2365400062 Jystck10GrpYAxsLvrFrwrdPstvPsStt "Reports when the current joystick grip position is on the positive travel side (forward, right, clockwise, up) relative to the";
CM_ SG_ 2365400062 Jystck10GrpYAxsLvrBckNgtvPsSttus "Reports when the current joystick grip position is on the negative travel side (back, left, counterclockwise, down) relative";
CM_ SG_ 2365400062 Jystck10GrpYAxisNeutralPosStatus "Reports when the current joystick grip position is in the neutral position for that axis of travel. The neutral position";
CM_ SG_ 2365400062 Joystick10GripXAxisPos "The position of the joystick grip in the relative motion of travel from the neutral position. Position value of 0 is Neutral and";
CM_ SG_ 2365400062 Jystck10GrpXAxsLvrRghtPstvPsStts "Reports when the current joystick grip position is on the positive travel side (forward, right, clockwise, up) relative to the";
CM_ SG_ 2365400062 Jystck10GrpXAxsLvrLftNgtvPsSttus "Reports when the current joystick grip position is on the negative travel side (back, left, counterclockwise, down) relative";
CM_ SG_ 2365400062 Jystck10GrpXAxisNeutralPosStatus "Reports when the current joystick grip position is in the neutral position for that axis of travel. The neutral position";
CM_ BO_ 2566713598 "Contains information on the engine fuel and lube system";
CM_ SG_ 2566713598 EngFuelFilterIntakeAbsPress "Absolute pressure of fuel at the intake of the fuel filter (suction side) located between the fuel tank and the fuel supply";
CM_ BO_ 2499604478 "Engine related parameters.";
CM_ SG_ 2499604478 EngExhstGsRcrcltn1OutletAbsPress "EGR outlet absolute pressure is measured after the EGR 1 valve. See SPN 5019 for 1 byte resolution.";
CM_ SG_ 2499604478 EngExhstGsRcrcltn1IntakeAbsPress "EGR intake absolute pressure measured before the EGR 1 valve.";
CM_ BO_ 2499608830 "Engine Fluid/Pressure 10";
CM_ SG_ 2499608830 EngExhstGsRcrcltn2IntakeAbsPress "EGR intake absolute pressure measured before the EGR 2 valve.";
CM_ SG_ 2499608830 EngExhstGsRcrcltn2OutletAbsPress "Absolute Pressure immediately after the EGR2 valve";
CM_ SG_ 2499608830 EngExhstGsRcrclation2IntakePress "EGR2 intake gauge pressure is measured after EGR2 cooler and before EGR2 valve";
CM_ SG_ 2499608830 EngExhstGsRcirculation2DiffPress "Differential Pressure across the Exhaust Gas Recirculation 2 (EGR2) system.";
CM_ BO_ 2432499198 "Engine related parameters";
CM_ SG_ 2432499198 CmmndedEngFuelInjectionCtrlPress "Provides the commanded set point value for the engine fuel injection control pressure.";
CM_ SG_ 2432499198 CommandedEngFuelRailPress "Provides the commanded set point value for the engine fuel rail pressure";
CM_ SG_ 2432499198 EngExhstGsRcirculation2Valve2Pos "The position of the second exhaust gas recirculation valve of EGR 2 expressed as a percentage of full travel. 0% means";
CM_ SG_ 2432499198 EngExhstGsRecirculation2ValvePos "Position of EGR2 valve expressed as a percentage of full travel. 0% means the valve is closed and no exhaust gas is";
CM_ BO_ 2633825022 "Engine related parameters";
CM_ SG_ 2633825022 EngExhstGsRcrculation2Valve2Ctrl "Desired percentage of maximum Exhaust Gas Recirculation 2 (EGR2) valve 2 opening. 0% means the valve is closed.";
CM_ SG_ 2633825022 EngExhstGsRcirculation2ValveCtrl "Desired percentage of maximum Exhaust Gas Recirculation 2 (EGR2) valve opening. 0% means the valve is closed.";
CM_ BO_ 2633826046 "Electronic Engine Controller 10";
CM_ SG_ 2633826046 EGR2CoolerBypassActuatorPos "EGR2 Cooler Bypass Actuator position, where 0% = Fully Closed (no gas flowing through the bypass), and 100% = Fully";
CM_ SG_ 2633826046 EngExhstGsRcrcltn2ClerEfficiency "Exhaust Gas Recirculation 2 cooler efficiency is an indication of the cooler’s ability to reduce the temperature of the";
CM_ SG_ 2633826046 EngExhstGsRcrcltn2ClrIntkGsAbsPr "Exhaust Gas Recirculation 2 gas absolute pressure is measured at EGR2 cooler intake. See SPN 5253 for EGR2";
CM_ SG_ 2633826046 EngExhstGsRcrcltn2ClerIntakeTemp "Exhaust Gas Recirculation 2 (EGR2) Temperature measured at EGR2 cooler intake. See SPN 5255 for Engine EGR2";
CM_ BO_ 2566711294 "The EC3 message contains a static engine friction torque map consisting of torque points that correspond to the speed";
CM_ SG_ 2566711294 EngFrctnPrcentTorqueAtIdlePoint7 "The static portion of the friction torque at speed point 7 (SPN 533) of the engine torque map in the engine configuration";
CM_ SG_ 2566711294 EngFrctnPrcentTorqueAtIdlePoint6 "For engine configuration map modes 1 and 2, this is the static portion of the friction torque at speed point 6 (SPN 532) of";
CM_ SG_ 2566711294 EngFrctnPrcentTorqueAtIdlePoint5 "The static portion of the friction torque at speed point 5 (SPN 531) of the engine torque map in the engine configuration";
CM_ SG_ 2566711294 EngFrctnPrcentTorqueAtIdlePoint4 "The static portion of the friction torque at speed point 4 (SPN 530) of the engine torque map in the engine configuration";
CM_ SG_ 2566711294 EngFrctnPrcentTorqueAtIdlePoint3 "The static portion of the friction torque at speed point 3 (SPN 529) of the engine torque map in the engine configuration";
CM_ SG_ 2566711294 EngFrctnPrcentTorqueAtIdlePoint2 "The static portion of the friction torque at speed point 2 (SPN 528) of the engine torque map in the engine configuration";
CM_ SG_ 2566711294 EngFrctnPrcentTorqueAtIdlePoint1 "The static portion of the friction torque at speed point 1 (SPN 188) of the engine torque map in the engine configuration";
CM_ BO_ 2566749438 "Diesel Particulate Filter Control 1";
CM_ SG_ 2566749438 DslPrtcltFltrActvRgnrtnFrcdSttus "Indicates the forced execution status of diesel particulate filter regeneration.";
CM_ SG_ 2566749438 ExhaustSystemHighTempLampCmd "Command to control the exhaust system high temperature lamp. This lamp indicates that the exhaust system";
CM_ SG_ 2566749438 DslPrtcltFltrAtmtcActvRgnrtnIntt "Indicates the configuration of diesel particulate filter active regeneration automatic initiation.";
CM_ SG_ 2566749438 DslPrtcltFltrActvRgnrtnInhbtdDTV "Speed";
CM_ SG_ 2566749438 DslPrtcltFltrActvRgnrtnInhbtdDTE "Indicates the state of diesel particulate filter active regeneration inhibition due to the engine not being warmed up.";
CM_ SG_ 2566749438 DslPrtcltFltrActvRgnrtnInhb_0000 "Indicates the state of diesel particulate filter active regeneration inhibition due to a permanent system lockout.";
CM_ SG_ 2566749438 DslPrtcltFltrActvRgnrtnInhbtdDTT "Indicates the state of diesel particulate filter active regeneration inhibition due to a temporary system lockout.";
CM_ SG_ 2566749438 DslPrtcltFltrActvRgnrtn_DTS_02 "Indicates the state of diesel particulate filter active regeneration inhibition due to a system timeout.Indicates the state of diesel particulate filter active regeneration inhibition due to a system fault being active.Indicates the state of diesel particulate filter active regeneration inhibition due to the service brake being active.";
CM_ SG_ 2566749438 DslPrtcltFltrActvRgnrtnInhbtdDTL "Indicates the state of diesel particulate filter active regeneration inhibition due to the exhaust gas temperature being too";
CM_ SG_ 2566749438 DslPrtcltFltrActvRgnrtnInhb_0001 "Indicates the state of diesel particulate filter active regeneration inhibition due to the parking brake being not set.";
CM_ SG_ 2566749438 DslPrtcltFltrActvRgnrtnInhb_0002 "Speed";
CM_ SG_ 2566749438 DslPrtcltFltrActvRgnrtnInhbtdDTO "Indicates the state of diesel particulate filter active regeneration inhibition due to the transmission being out of neutral.";
CM_ SG_ 2566749438 DslPrtcltFltrActvRgnrtnInhbtdDTA "Indicates the state of diesel particulate filter active regeneration inhibition due to the accelerator pedal being off idle.";
CM_ SG_ 2566749438 DslPrtcltFltrActvRgnrtnInhbtdDTP "Indicates the state of diesel particulate filter active regeneration inhibition due to the PTO being active.";
CM_ SG_ 2566749438 DslPrtcltFltrActvRgnrtnInhbtdDTC "Indicates the state of diesel particulate filter active regeneration inhibition due to the clutch being disengaged.";
CM_ SG_ 2566749438 DslPrtcltFltrActvRgnrtnInhbtdDTI "Indicates the state of diesel particulate filter active regeneration inhibition due to the Diesel Particulate Filter Regeneration";
CM_ SG_ 2566749438 DslPrtcltFltrActvRgnrtnInhbtdStt "Indicates the state of diesel particulate filter active regeneration inhibition.";
CM_ SG_ 2566749438 DieselParticulateFilterStatus "Indicates the state of the diesel particulate filter regeneration need and urgency.";
CM_ SG_ 2566749438 DslPrtcltFltrActvRgnrationStatus "Indicates the state of diesel particulate filter active regeneration.";
CM_ SG_ 2566749438 DslPrtcltFltrPssvRgnrationStatus "Indicates the state of diesel particulate filter passive regeneration.";
CM_ SG_ 2566749438 DieselParticulateFilterLampCmd "Command to control the diesel particulate filter lamp.";
CM_ BO_ 2566715646 "Additional diesel particulate filter soot parameters for diesel particulate filter 2.";
CM_ SG_ 2566715646 DslPrtculateFilter2SootSignalMin "Minimum output signal level of the current soot measurement from diesel particulate filter 2 soot sensor. This is a";
CM_ SG_ 2566715646 DslPrtculateFilter2SootSignalMax "Maximum output signal level of the current soot measurement from diesel particulate filter 2 soot sensor. This is a";
CM_ SG_ 2566715646 DslPrtcltFltr2StSgnlStndrdDvtion "Standard deviation of the soot measurement from diesel particulate filter 2 soot sensor.";
CM_ BO_ 2566724606 "Diesel particulate filter soot parameters for diesel particulate filter 2.";
CM_ SG_ 2566724606 DslPrtcltFltr2StSnsrPrlminaryFMI "Used to identify the applicable J1939-73 FMI detected in the soot sensor signal by the manufacturer’s sensor control";
CM_ SG_ 2566724606 DslPrtcltFilter2MedianSootSignal "Median output signal level from diesel particulate filter 2 soot sensor.";
CM_ SG_ 2566724606 DslPrtclateFilter2MeanSootSignal "Mean output signal level from diesel particulate filter 2 soot sensor.";
CM_ SG_ 2566724606 DslParticulateFilter2SootDensity "Soot density in diesel particulate filter 2.";
CM_ SG_ 2566724606 DieselParticulateFilter2SootMass "Soot mass in diesel particulate filter 2.";
CM_ BO_ 2566715902 "Additional diesel particulate filter soot parameters for diesel particulate filter 1.";
CM_ SG_ 2566715902 DslPrtculateFilter1SootSignalMin "Minimum output signal level of the current soot measurement from diesel particulate filter 1 soot sensor. This is a";
CM_ SG_ 2566715902 DslPrtculateFilter1SootSignalMax "Maximum output signal level of the current soot measurement from diesel particulate filter 1 soot sensor. This is a";
CM_ SG_ 2566715902 DslPrtcltFltr1StSgnlStndrdDvtion "Standard deviation of the soot measurement from diesel particulate filter 1 soot sensor.";
CM_ BO_ 2566724862 "Diesel particulate filter soot parameters for diesel particulate filter 1.";
CM_ SG_ 2566724862 DslPrtcltFltr1StSnsrPrlminaryFMI "Used to identify the applicable J1939-73 FMI detected in the soot sensor signal by the manufacturer’s sensor control";
CM_ SG_ 2566724862 DslPrtcltFilter1MedianSootSignal "Median output signal level from diesel particulate filter 1 soot sensor.";
CM_ SG_ 2566724862 DslPrtclateFilter1MeanSootSignal "Mean output signal level from diesel particulate filter 1 soot sensor.";
CM_ SG_ 2566724862 DslParticulateFilter1SootDensity "Soot density in diesel particulate filter 1.";
CM_ SG_ 2566724862 DieselParticulateFilter1SootMass "Soot mass in diesel particulate filter 1.";
CM_ BO_ 2566718718 "This message will be transmitted by the controller that is illuminating the lamps.";
CM_ SG_ 2566718718 VehicleBatteryChargingLampData "This parameter provides measured data from the Vehicle Battery Charging Lamp.";
CM_ SG_ 2566718718 VehicleHVACRecirculationLampData "This parameter provides measured data from the Vehicle HVAC Recirculation Lamp.";
CM_ SG_ 2566718718 VehicleAirPressLowLampData "This parameter provides measured data from the Vehicle Air Pressure Low Lamp.";
CM_ SG_ 2566718718 VehicleFuelLevelLowLampData "This parameter provides measured data from theVehicle Fuel Level Low Lamp.";
CM_ SG_ 2566718718 VehicleBatteryVoltageLowLampData "This parameter provides measured data from the Vehicle Battery Voltage Low Lamp.";
CM_ BO_ 2566718974 "This message will be transmitted by the controller that is illuminating the lamps.";
CM_ SG_ 2566718974 EngWaitToStartLampData "This parameter provides measured data from the Engine Wait To Start Lamp. See SPN 1081 for the command.";
CM_ SG_ 2566718974 EngFuelFilterRestrictedLampData "Command signal directly controlling the Vehicle Fuel Filter Restricted Lamp.";
CM_ SG_ 2566718974 EngAirFilterRestrictionLampData "This parameter provides measured data from the Engine Air Filter Restriction Lamp.";
CM_ SG_ 2566718974 EngIdleManagementActiveLampData "This parameter provides measured data from the Engine Idle Management Active Lamp.";
CM_ SG_ 2566718974 EngCoolantLevelLowLampData "This parameter provides measured data from the Engine Coolant Level Low Lamp.";
CM_ SG_ 2566718974 EngCoolantTempHighLampData "This parameter provides measured data from the Engine Coolant Temperature High Lamp.";
CM_ SG_ 2566718974 EngOilPressLowLampData "This parameter provides measured data from the Engine Oil Pressure Low Lamp.";
CM_ SG_ 2566718974 CmprssnBrkEnblSwtchIndctrLmpData "This parameter provides measured data from the Compression Brake Enable Switch Indicator Lamp.";
CM_ SG_ 2566718974 EngBrakeActiveLampData "This parameter provides measured data from the Engine Brake Active Lamp.";
CM_ SG_ 2566718974 OBDMalfunctionIndicatorLampData "This parameter provides measured data from the OBD Malfunction Indicator Lamp.";
CM_ SG_ 2566718974 EngRedStopLampData "This parameter provides measured data from the Engine Red Stop Lamp.";
CM_ SG_ 2566718974 EngAmberWarningLampData "This parameter provides measured data from the Engine Amber Warning Lamp.";
CM_ SG_ 2566718974 EngProtectLampData "This parameter provides measured data from the Engine Protect Lamp.";
CM_ BO_ 2566719230 "Message that directly controls the driver indicator lamps. See also PGN 64775 for additional lamps and PGN 64772 for";
CM_ SG_ 2566719230 VehicleBatteryChargingLampCmd "Command signal directly controlling the Vehicle Battery Charging Lamp.";
CM_ SG_ 2566719230 VehicleHVACRecirculationLampCmd "Command signal directly controlling the Vehicle HVAC Recirculation Lamp.";
CM_ SG_ 2566719230 VehicleAirPressLowLampCmd "Command signal directly controlling the Vehicle Air Pressure Low Lamp.";
CM_ SG_ 2566719230 VehicleFuelLevelLowLampCmd "Command signal directly controlling the Vehicle Fuel Level Low Lamp.";
CM_ SG_ 2566719230 VehicleBatteryVoltageLowLampCmd "Command signal directly controlling the Vehicle Battery Voltage Low Lamp.";
CM_ BO_ 2560818942 "DM32 provides the DTCs and associated timers";
CM_ SG_ 2560818942 DTCTimeUntilDerate "This timer provides the number of hours the malfunction has until the OBD required derate will occur";
CM_ SG_ 2560818942 DTCTotalPreviouslyActiveTime "This timer provides the number of hours the NOx malfunction has been confirmed and previously active";
CM_ SG_ 2560818942 DTCTotalActiveTime "This timer provides the total number of hours the DTC has been confirmed and active";
CM_ SG_ 2560818942 FailureModeIdentifier1 "The FMI defines the type of failure detected in the subsystem identified by an SPN.";
CM_ SG_ 2560818942 SPN1High "SPN #1 (Conversion Version 4)";
CM_ SG_ 2560818942 SPN1 "SPN #1 (Conversion Version 4)";
CM_ BO_ 2561212158 "This provides ASCII text information, for example to an display instrument. Broadcast rate should be on event and 1-5";
CM_ SG_ 2561212158 TextDisplayIndex "Used for overwriting consecutive bytes of a displayed string when byte 1 \"Text Display Instructions\" state is set for";
CM_ SG_ 2561212158 TextDisplayInstructions "This parameter describes the status for the display how to show the information.";
CM_ BO_ 2566746366 "Door ramp control";
CM_ SG_ 2566746366 RetractStatusOfRamp5 "Retract status of ramp at doorway 5, counting from front to back on the vehicle.";
CM_ SG_ 2566746366 RetractStatusOfRamp4 "Retract status of ramp at doorway 4, counting from front to back on the vehicle.";
CM_ SG_ 2566746366 MovementStatusOfRamp5 "Movement status of ramp at doorway 5, counting from front to back on the vehicle.";
CM_ SG_ 2566746366 MovementStatusOfRamp4 "Movement status of ramp at doorway 4, counting from front to back on the vehicle.";
CM_ SG_ 2566746366 EnableStatusOfRamp5 "Enable status of ramp at doorway 5, counting from front to back on the vehicle.";
CM_ SG_ 2566746366 EnableStatusOfRamp4 "Enable status of ramp at doorway 4, counting from front to back on the vehicle.";
CM_ SG_ 2566746366 MovementStatusOfRamp3 "Movement status of ramp at doorway 3, counting from front to back on the vehicle.";
CM_ SG_ 2566746366 EnableStatusOfRamp3 "Enable status of ramp at doorway 3, counting from front to back on the vehicle.";
CM_ SG_ 2566746366 RetractStatusOfRamp3 "Retract status of ramp at doorway 3, counting from front to back on the vehicle.";
CM_ SG_ 2566746366 MovementStatusOfRamp2 "Movement status of ramp at doorway 2, counting from front to back on the vehicle.";
CM_ SG_ 2566746366 EnableStatusOfRamp2 "Enable status of ramp at doorway 2, counting from front to back on the vehicle.";
CM_ SG_ 2566746366 RetractStatusOfRamp2 "Retract status of ramp at doorway 2, counting from front to back on the vehicle.";
CM_ SG_ 2566746366 MovementStatusOfRamp1 "Movement status of ramp at doorway 1, counting from front to back on the vehicle.";
CM_ SG_ 2566746366 EnableStatusOfRamp1 "Enable status of ramp at doorway 1, counting from front to back on the vehicle.";
CM_ SG_ 2566746366 RetractStatusOfRamp1 "Retract status of ramp at doorway 1, counting from front to back on the vehicle.";
CM_ BO_ 2566750206 "Engine Configuration 2";
CM_ SG_ 2566750206 MaxCrankAttemptsPerStartAttempt "The number of cranking cycles that will be performed before ending the start attempt. This is intended to be used in";
CM_ BO_ 2566755582 "Engine related parameters";
CM_ SG_ 2566755582 CommandedEngIntakeManifoldPress "Provides the commanded set point value for the engine intake manifold pressure.";
CM_ SG_ 2566755582 EngCrnkcsBrtherOilSeparatorSpeed "The speed of a rotating (centrifugal) crankcase oil separator.";
CM_ SG_ 2566755582 EngExhstGsRcirculation1Valve2Pos "The position of the second exhaust gas recirculation valve expressed as a percentage of full travel. Zero percent means";
CM_ SG_ 2566755582 EngExhstGsRecirculation1ValvePos "The position of the exhaust gas recirculation valve expressed as a percentage of full travel. Zero percent means the valve";
CM_ BO_ 2566746110 "Electronic Engine Controller 8";
CM_ SG_ 2566746110 EngExhstGsRcrcltn1ClrIntkGsAbsPr "Exhaust Gas Recirculation gas absolute pressure is measured at the EGR cooler intake. See SPN 3358 for EGR";
CM_ SG_ 2566746110 EngExhstGsRcrcltn1ClerIntakeTemp "Exhaust Gas Recirculation (EGR) Temperature measured at the EGR cooler intake. See SPN 412 for Engine EGR";
CM_ SG_ 2566746110 EngExhstGsRcrcltn1ClerEfficiency "Exhaust Gas Recirculation cooler efficiency is an indication of the cooler’s ability to reduce the temperature of the exhaust";
CM_ SG_ 2566746110 EngExhstGsRcrculation1Valve2Ctrl "Desired percentage of maximum Exhaust Gas Recirculation (EGR) valve opening for valve 2. 0% means valve is closed.";
CM_ BO_ 2566752510 "Engine Fluid Level/Pressure 5";
CM_ SG_ 2566752510 EngIntkVlvActtionOilPressForCyl4 "The gage pressure of the oil in the hydraulic accumulator that powers the engine intake valve for cylinder #4.";
CM_ SG_ 2566752510 EngIntkVlvActtionOilPressForCyl3 "The gage pressure of the oil in the hydraulic accumulator that powers the engine intake valve for cylinder #3.";
CM_ SG_ 2566752510 EngIntkVlvActtionOilPressForCyl2 "The gage pressure of the oil in the hydraulic accumulator that powers the engine intake valve for cylinder #2.";
CM_ SG_ 2566752510 EngIntkVlvActtionOilPressForCyl1 "The gage pressure of the oil in the hydraulic accumulator that powers the engine intake valve for cylinder #1.";
CM_ BO_ 2566752254 "Engine Fluid Level/Pressure 6";
CM_ SG_ 2566752254 EngIntkVlvActtionOilPressForCyl8 "The gage pressure of the oil in the hydraulic accumulator that powers the engine intake valve for cylinder #8.";
CM_ SG_ 2566752254 EngIntkVlvActtionOilPressForCyl7 "The gage pressure of the oil in the hydraulic accumulator that powers the engine intake valve for cylinder #7.";
CM_ SG_ 2566752254 EngIntkVlvActtionOilPressForCyl6 "The gage pressure of the oil in the hydraulic accumulator that powers the engine intake valve for cylinder #6.";
CM_ SG_ 2566752254 EngIntkVlvActtionOilPressForCyl5 "The gage pressure of the oil in the hydraulic accumulator that powers the engine intake valve for cylinder #5.";
CM_ BO_ 2566751998 "Engine Fluid Level/Pressure 7";
CM_ SG_ 2566751998 EngIntkVlvActtonOilPressForCyl12 "The gage pressure of the oil in the hydraulic accumulator that powers the engine intake valve for cylinder #12.";
CM_ SG_ 2566751998 EngIntkVlvActtonOilPressForCyl11 "The gage pressure of the oil in the hydraulic accumulator that powers the engine intake valve for cylinder #11.";
CM_ SG_ 2566751998 EngIntkVlvActtonOilPressForCyl10 "The gage pressure of the oil in the hydraulic accumulator that powers the engine intake valve for cylinder #10.";
CM_ SG_ 2566751998 EngIntkVlvActtionOilPressForCyl9 "The gage pressure of the oil in the hydraulic accumulator that powers the engine intake valve for cylinder #9.";
CM_ BO_ 2566751742 "Engine Fluid Level/Pressure 8";
CM_ SG_ 2566751742 EngIntkVlvActtonOilPressForCyl16 "The gage pressure of the oil in the hydraulic accumulator that powers the engine intake valve for cylinder #16.";
CM_ SG_ 2566751742 EngIntkVlvActtonOilPressForCyl15 "The gage pressure of the oil in the hydraulic accumulator that powers the engine intake valve for cylinder #15.";
CM_ SG_ 2566751742 EngIntkVlvActtonOilPressForCyl14 "The gage pressure of the oil in the hydraulic accumulator that powers the engine intake valve for cylinder #14.";
CM_ SG_ 2566751742 EngIntkVlvActtonOilPressForCyl13 "The gage pressure of the oil in the hydraulic accumulator that powers the engine intake valve for cylinder #13.";
CM_ BO_ 2566751486 "Engine Fluid Level/Pressure 9";
CM_ SG_ 2566751486 EngIntkVlvActtonOilPressForCyl20 "The gage pressure of the oil in the hydraulic accumulator that powers the engine intake valve for cylinder #20.";
CM_ SG_ 2566751486 EngIntkVlvActtonOilPressForCyl19 "The gage pressure of the oil in the hydraulic accumulator that powers the engine intake valve for cylinder #19.";
CM_ SG_ 2566751486 EngIntkVlvActtonOilPressForCyl18 "The gage pressure of the oil in the hydraulic accumulator that powers the engine intake valve for cylinder #18.";
CM_ SG_ 2566751486 EngIntkVlvActtonOilPressForCyl17 "The gage pressure of the oil in the hydraulic accumulator that powers the engine intake valve for cylinder #17.";
CM_ BO_ 2499641854 "Contains information about the EGR Cooler Bypass";
CM_ SG_ 2499641854 EGR1CoolerBypassActuatorPostion "The parameter gives the % open of the EGR Cooler Bypass Actuator, where 0% = Fully Closed (no gas flowing through";
CM_ BO_ 2566748158 "The PGN contains information about spark voltage values for cylinders 1 through 4. This is the secondary voltage of the";
CM_ SG_ 2566748158 EngSparkPlug4 "The measured voltage of the spark event on Cylinder #4";
CM_ SG_ 2566748158 EngSparkPlug3 "The measured voltage of the spark event on Cylinder #3";
CM_ SG_ 2566748158 EngSparkPlug2 "The measured voltage of the spark event on Cylinder #2";
CM_ SG_ 2566748158 EngSparkPlug1 "The measured voltage of the spark event on Cylinder #1";
CM_ BO_ 2566747902 "The PGN contains information about spark voltage values for cylinders 5 through 8. This is the secondary voltage of the";
CM_ SG_ 2566747902 EngSparkPlug8 "The measured voltage of the spark event on Cylinder #8";
CM_ SG_ 2566747902 EngSparkPlug7 "The measured voltage of the spark event on Cylinder #7";
CM_ SG_ 2566747902 EngSparkPlug6 "The measured voltage of the spark event on Cylinder #6";
CM_ SG_ 2566747902 EngSparkPlug5 "The measured voltage of the spark event on Cylinder #5";
CM_ BO_ 2566747646 "The PGN contains information about spark voltage values for cylinders 9 through 12. This is the secondary voltage of the";
CM_ SG_ 2566747646 EngSparkPlug12 "The measured voltage of the spark event on Cylinder #12";
CM_ SG_ 2566747646 EngSparkPlug11 "The measured voltage of the spark event on Cylinder #11";
CM_ SG_ 2566747646 EngSparkPlug10 "The measured voltage of the spark event on Cylinder #10";
CM_ SG_ 2566747646 EngSparkPlug9 "The measured voltage of the spark event on Cylinder #9";
CM_ BO_ 2566747390 "Engine Spark Voltage 4";
CM_ SG_ 2566747390 EngSparkPlug16 "The measured voltage of the spark event on Cylinder #16";
CM_ SG_ 2566747390 EngSparkPlug15 "The measured voltage of the spark event on Cylinder #15";
CM_ SG_ 2566747390 EngSparkPlug14 "The measured voltage of the spark event on Cylinder #14";
CM_ SG_ 2566747390 EngSparkPlug13 "The measured voltage of the spark event on Cylinder #13";
CM_ BO_ 2566747134 "The PGN contains information about spark voltage values for cylinders 17 through 20. This is the secondary voltage of";
CM_ SG_ 2566747134 EngSparkPlug20 "The measured voltage of the spark event on Cylinder #20";
CM_ SG_ 2566747134 EngSparkPlug19 "The measured voltage of the spark event on Cylinder #19";
CM_ SG_ 2566747134 EngSparkPlug18 "The measured voltage of the spark event on Cylinder #18";
CM_ SG_ 2566747134 EngSparkPlug17 "The measured voltage of the spark event on Cylinder #17";
CM_ BO_ 2566746878 "The PGN contains information about spark voltage values for cylinders 21 through 24. This is the secondary voltage of";
CM_ SG_ 2566746878 EngSparkPlug24 "The measured voltage of the spark event on Cylinder #24";
CM_ SG_ 2566746878 EngSparkPlug23 "The measured voltage of the spark event on Cylinder #23";
CM_ SG_ 2566746878 EngSparkPlug22 "The measured voltage of the spark event on Cylinder #22";
CM_ SG_ 2566746878 EngSparkPlug21 "The measured voltage of the spark event on Cylinder #21";
CM_ BO_ 2561277694 "Message containing commands, sent to the forward image controller";
CM_ SG_ 2561277694 LaneDepartureWarningEnableCmd "Command to enable/disable Lane Departure Indication";
CM_ BO_ 2633861886 "Conveys basic SAE J2012 DTC information for on-board or service tool displays.";
CM_ SG_ 2633861886 J2012DTCOccurrenceCount "Number of occurrences of the respective SAE J2012 DTC being conveyed.";
CM_ SG_ 2633861886 J2012DTCStatus "Indicates if the respective SAE J2012 DTC is active or previously active.";
CM_ SG_ 2633861886 J2012DTC "Five character ASCII SAE J2012 DTC, sent most significant byte first.";
CM_ SG_ 2633861886 NumberOfJ2012DTCs "The number J2012 DTCs being conveyed in PGN 64906. If the value of this parameter is zero, the device broadcasting";
CM_ BO_ 2565873150 "Contains information which relates to a steering angle sensor.";
CM_ SG_ 2565873150 MessageChecksum "The message checksum is used to verify the signal path from the demanding device to the steering controller. The";
CM_ SG_ 2565873150 MessageCounter "The message counter is to verify the signal path from the demanding device to the steering controller. The support of this";
CM_ SG_ 2565873150 SteerAngleSensorCalibrated "This signal indicates the calibration status of the steering angle sensor.";
CM_ SG_ 2565873150 SteerAngleSensorActiveMode "This signal indicates the operational mode of the steering angle sensor.";
CM_ SG_ 2565873150 SteerWheelAngleRange "The signal indicates the range of the steering wheel angle the sensor element is capable to measure. The steering wheel";
CM_ SG_ 2565873150 SteerWheelAngleRangeCounterType "The signal indicates whether the steering wheel angle sensor is capable of absolute measuring of the number of steering";
CM_ SG_ 2565873150 SteerWheelAngleRangeCounter "The signal indicates the number of steering wheel angle range overflows if the operating range of steering wheel is";
CM_ SG_ 2565873150 SteerWheelAngle "The main operator`s steering wheel angle (on the steering column, not the actual wheel angle). The vehicle being steered";
CM_ BO_ 2566745854 "Aftertreatment 1 SCR Service Information";
CM_ SG_ 2566745854 Aftrtrtmnt1SCRCtlystCnvrsnEffcnc "The SCR catalyst conversion efficiency percentage. Calculated as 100 times the catalyst intake NOx minus the catalyst";
CM_ SG_ 2566745854 Aftrtrtmnt1SCRCmmnddCtlystRgntCn "This parameter transmits the amount of reagent that the emissions control system has requested to be used, averaged";
CM_ SG_ 2566745854 Aftrtrtmnt1SCRAvrgCtlystRgntCnsm "Measured use of reagent by a Selective Catalytic Reduction system for exhaust emission control, averaged over the";
CM_ SG_ 2566745854 Aftrtrtmnt1DslExhstFldTnkLwLvlIn "The distance traveled while diesel exhaust fluid is low/empty or driver warning/inducement strategy is active. Note:";
CM_ BO_ 2566751230 "Transfer Case Information";
CM_ SG_ 2566751230 TransferCaseStatus "This parameter describes the feedback from the transfer case controller . Used by instrument clusters, tachographs,";
CM_ SG_ 2566755838 TransOilLifeRemaining "Signal which indicates the actual oil life remaining in percent. 100% means the transmission oil is brand new, and 0%";
CM_ SG_ 2566755838 TrnsTorqueConverterOilOutletTemp "Temperature of transmission torque converter outlet oil.";
CM_ SG_ 2566755838 TransOverheatIndicator "Signal from transmission indicating that its fluid temperature is above normal acceptable limits, and as a result,";
CM_ SG_ 2566755838 TransOilLevelSwitch "This switch indicates whether transmission oil level is full or empty.";
CM_ SG_ 2566755838 TransOilFilterRestrictionSwitch "This switch indicates whether the transmission oil filter is clogged.";
CM_ BO_ 2566752766 "Vehicle Direction/Speed 2";
CM_ SG_ 2566752766 VehicleRoll "This parameter indicates the roll in degrees from level. Facing the direction of travel a tip to the left would be indicated by";
CM_ SG_ 2633938942 TotalEngCruiseTime "Total time that the engine has operated in the cruise hold state, excluding time in accelerator override, over the life of the";
CM_ SG_ 2633938942 TotalDriveAverageLoadFactor "Average engine load factor while engine speed is greater than zero, vehicle speed is greater than or equal to 2 km/h, and";
CM_ SG_ 2633938942 TripDriveAverageLoadFactor "Average engine load factor while engine speed is greater than zero, vehicle speed is greater than or equal to 2 km/h, and";
CM_ SG_ 2633938942 TripAverageEngSpeed "Average speed of the engine since the last trip reset.";
CM_ SG_ 2633938942 TripMaxEngSpeed "Maximum engine speed achieved since the last trip reset.";
CM_ BO_ 2566799614 "This lighting message is a response to the request for lighting data in the lighting command message. Each lighting";
CM_ SG_ 2566799614 ImplementRearWorkLight "This parameter provides measured data from the implement rear work lamps.";
CM_ SG_ 2566799614 ImplementLeftForwardWorkLight "This parameter provides measured data from the forward facing work lights toward the left end of the implement.";
CM_ SG_ 2566799614 ImplementRightForwardWorkLight "This parameter provides measured data from the forward facing work lights toward the right end of the implement.";
CM_ SG_ 2566799614 ImplementLeftFacingWorkLight "This parameter provides measured data from the work lights mounted on an implement to illuminate beyond left end of";
CM_ SG_ 2566799614 ImplementRightFacingWorkLight "This parameter provides measured data from the work lights mounted on an implement to illuminate beyond right end of";
CM_ SG_ 2566799614 ImplementOEMOption1Light "This parameter provides measured data from the implement OEM option 1 light.";
CM_ SG_ 2566799614 ImplementOEMOption2Light "This parameter provides measured data from the implement OEM option 2 light.";
CM_ SG_ 2566799614 TrctorFrontHighMountedWorkLights "This parameter provides measured data from the tractor front high mounted work lights.";
CM_ SG_ 2566799614 TractorFrontLowMountedWorkLights "This parameter provides measured data from the tractor front low mounted work lights.";
CM_ SG_ 2566799614 TractorSideHighMountedWorkLights "This parameter provides measured data from the tractor side high mounted work lights.";
CM_ SG_ 2566799614 TractorSideLowMountedWorkLights "This parameter provides measured data from the tractor side low mounted work lights.";
CM_ SG_ 2566799614 TractorRearHighMountedWorkLights "This parameter provides measured data from the tractor rear high mounted work lights.";
CM_ SG_ 2566799614 TractorRearLowMountedWorkLights "This parameter provides measured data from the tractor rear low mounted work lights.";
CM_ SG_ 2566799614 TrctorUndersideMountedWorkLights "This parameter provides measured data from the tractor underside mounted work lights.";
CM_ SG_ 2566799614 RearFogLights "This parameter provides measured data from the tractor and/or implement rear fog lights.";
CM_ SG_ 2566799614 TractorMarkerLight "This parameter provides measured data from the tractor and attached implement marker lights, including front position";
CM_ SG_ 2566799614 ImplementMarkerLight "This parameter provides measured data from an attached implement marker lights, including front position lights, rear tail";
CM_ SG_ 2566799614 TractorClearanceLight "This parameter provides measured data from the tractor high mounted clearance and center ID lights.";
CM_ SG_ 2566799614 ImplementClearanceLight "This parameter provides measured data from an attached implement high mounted clearance lights.";
CM_ SG_ 2566799614 LeftStopLight "This parameter provides measured data from the tractor and attached implement left stop lights.";
CM_ SG_ 2566799614 RightStopLight "This parameter provides measured data from the tractor and attached implement right stop lights.";
CM_ SG_ 2566799614 CenterStopLight "This parameter provides measured data from the tractor and attached implement center stop lights.";
CM_ SG_ 2566799614 BackUpLightAndAlarmHorn "This parameter provides measured data from the back up lights and/ or associated alarm.";
CM_ SG_ 2566799614 LeftTurnSignalLights "This parameter provides measured data from the tractor and attached implement left turn signal lights.";
CM_ SG_ 2566799614 RightTurnSignalLights "This parameter provides measured data from the tractor and attached implement right turn signal lights.";
CM_ SG_ 2566799614 RotatingBeaconLight "This parameter provides measured data from the beacon light on tractor or attached implements.";
CM_ SG_ 2566799614 TractorFrontFogLights "This parameter provides measured data from the tractor front fog lights.";
CM_ SG_ 2566799614 HighBeamHeadLightData "This parameter provides measured data from the tractor high beam head light lamps.";
CM_ SG_ 2566799614 LowBeamHeadLightData "This parameter provides measured data from the tractor low beam head light lamps.";
CM_ SG_ 2566799614 AltBeamHeadLightData "This parameter provides measured data from the tractor alternate beam head light lamps.";
CM_ SG_ 2566799614 RunningLight "This parameter provides measured data from the vehicle’s running lights.";
CM_ BO_ 2365473278 "The lighting command message has been defined as a global message from the tractor to all lighting controllers on the";
CM_ SG_ 2365473278 ImplementRearWorkLightCmd "Command to activate or de-activate implement rear work lights. (This is also the same as Reversing Lights for truck";
CM_ SG_ 2365473278 ImplementLeftForwardWorkLightCmd "Command to activate or de-activate the forward facing work lights toward the left end of the implement.";
CM_ SG_ 2365473278 ImplmentRightForwardWorkLightCmd "Command to activate or de-activate the forward facing work lights toward the right end of the implement.";
CM_ SG_ 2365473278 LightingDataRqCmd "Command to provide a response of the light state";
CM_ SG_ 2365473278 ImplementLeftFacingWorkLightCmd "Command to activate or de-activate work lights mounted on an implement to illuminate beyond left end of the implement.";
CM_ SG_ 2365473278 ImplementRightFacingWorkLightCmd "Command to activate or de-activate work lights mounted on an implement to illuminate beyond right end of the implement.";
CM_ SG_ 2365473278 ImplementOEMOption1LightCmd "Command to activate or de-activate an implement OEM option 1 light. This is provided to meet special needs on";
CM_ SG_ 2365473278 ImplementOEMOption2LightCmd "Command to activate or de-activate an implement OEM option 2 light. This is provided to meet special needs on";
CM_ SG_ 2365473278 TrctrFrntHghMountedWorkLightsCmd "Command to activate or de-activate the tractor front high mounted work lights.";
CM_ SG_ 2365473278 TrctrFrntLowMountedWorkLightsCmd "Command to activate or de-activate the tractor front low mounted work lights.";
CM_ SG_ 2365473278 TrctrSdeHighMountedWorkLightsCmd "Command to activate or de-activate the tractor side high mounted work lights.";
CM_ SG_ 2365473278 TrctrSideLowMountedWorkLightsCmd "Command to activate or de-activate the tractor side low mounted work lights.";
CM_ SG_ 2365473278 TrctrRarHighMountedWorkLightsCmd "Command to activate or de-activate the tractor rear high mounted work lights.";
CM_ SG_ 2365473278 TrctrRearLowMountedWorkLightsCmd "Command to activate or de-activate the tractor rear low mounted work lights.";
CM_ SG_ 2365473278 TrctrUndrsdeMountedWorkLightsCmd "Command to activate or de-activate the tractor underside mounted work lights.";
CM_ SG_ 2365473278 RearFogLightCmd "Command to activate or de-activate tractor or implement rear fog lights.";
CM_ SG_ 2365473278 TractorMarkerLightCmd "Command to activate or de-activate tractor and implement front position lights, rear red tail lights, side amber running";
CM_ SG_ 2365473278 ImplementMarkerLightCmd "Command to activate or de-activate implement front position lights, rear red tail lights, side amber running lights, license";
CM_ SG_ 2365473278 TractorClearanceLightCmd "Command to activate or de-activate the tractor high mounted clearance and center ID lights";
CM_ SG_ 2365473278 ImplementClearanceLightCmd "Command to activate or de-activate the implement high mounted clearance and lights.";
CM_ SG_ 2365473278 LeftStopLightCmd "Command to activate or de-activate the tractor and implement left stop lights";
CM_ SG_ 2365473278 RightStopLightCmd "Command to activate or de-activate the tractor and implement right stop light";
CM_ SG_ 2365473278 CenterStopLightCmd "Command to activate or de-activate the tractor and implement center stop light";
CM_ SG_ 2365473278 BackUpLightAndAlarmHornCmd "Command to activate or de-activate the back up lights and/ or associated alarm if required";
CM_ SG_ 2365473278 LeftTurnSignalLightsCmd "Command to activate or de-activate left turn signal lights on the tractor and all connected implements";
CM_ SG_ 2365473278 RightTurnSignalLightsCmd "Command to activate or de-activate right turn signal lights on the tractor and all connected implements";
CM_ SG_ 2365473278 RotatingBeaconLightCmd "Command to activate or de-activate slow moving vehicle indicator lights on tractor and/or implements. Activation of the";
CM_ SG_ 2365473278 TractorFrontFogLightsCmd "Command to activate or de-activate tractor front fog lights.";
CM_ SG_ 2365473278 HighBeamHeadLightCmd "Command to activate or de-activate the tractor high beam head light lamps.";
CM_ SG_ 2365473278 LowBeamHeadLightCmd "Command to activate or de-activate the tractor low beam head light lamps.";
CM_ SG_ 2365473278 AltBeamHeadLightCmd "Command to activate or de-activate the tractor alternate head lights (only low beam is available on alternate head lights).";
CM_ SG_ 2365473278 RunningLightCmd "Command to activate or de-activate the tractor or powered vehicle running lights. Usually only used for on road vehicles.";
CM_ SG_ 2365485822 LandLevelingSystemEnableStatus "Communicate the enable/disable status of the Land Leveling System.";
CM_ SG_ 2365485822 BladeCtrlModeRight "Indicate if the land leveling system's automatic control is active or inactive for the elevation sensor on the right side of the";
CM_ SG_ 2365485822 BladeCtrlModeLeft "Indicate if the land leveling system's automatic control is active or inactive for the elevation sensor on the left side of the";
CM_ SG_ 2365485822 BladeCtrlMode "Allows the user to select the type of blade control for the land leveling system.";
CM_ SG_ 2365485822 BladeDurationAndDirection "Used to indicate the duration and direction that the land leveling system blade moves.";
CM_ BO_ 2633926654 "Ignition Timing 6";
CM_ SG_ 2633926654 EngActualIgntTiming "The actual ignition timing at the current engine conditions. This parameter may or may not be equal to one of the desired";
CM_ SG_ 2633926654 EngDesiredIgntTiming3 "A programmable timing value specific to the engine’s application. Factors affecting this value include both fuel type and";
CM_ SG_ 2633926654 EngDesiredIgntTiming2 "A programmable timing value specific to the engine’s application. Factors affecting this value include both fuel type and";
CM_ SG_ 2633926654 EngDesiredIgntTiming1 "A programmable timing value specific to the engine’s application. Factors affecting this value include both fuel type and";
CM_ BO_ 2633926398 "Ignition Timing 5";
CM_ SG_ 2633926398 EngCyl20IgntTiming "The ignition timing of the cylinder.";
CM_ SG_ 2633926398 EngCyl19IgntTiming "The ignition timing of the cylinder.";
CM_ SG_ 2633926398 EngCyl18IgntTiming "The ignition timing of the cylinder.";
CM_ SG_ 2633926398 EngCyl17IgntTiming "The ignition timing of the cylinder.";
CM_ BO_ 2633926142 "Ignition Timing 4";
CM_ SG_ 2633926142 EngCyl16IgntTiming "The ignition timing of the cylinder.";
CM_ SG_ 2633926142 EngCyl15IgntTiming "The ignition timing of the cylinder.";
CM_ SG_ 2633926142 EngCyl14IgntTiming "The ignition timing of the cylinder.";
CM_ SG_ 2633926142 EngCyl13IgntTiming "The ignition timing of the cylinder.";
CM_ BO_ 2633925886 "Ignition Timing 3";
CM_ SG_ 2633925886 EngCyl12IgntTiming "The ignition timing of the cylinder.";
CM_ SG_ 2633925886 EngCyl11IgntTiming "The ignition timing of the cylinder.";
CM_ SG_ 2633925886 EngCyl10IgntTiming "The ignition timing of the cylinder.";
CM_ SG_ 2633925886 EngCyl9IgntTiming "The ignition timing of the cylinder.";
CM_ BO_ 2633925630 "Ignition Timing 2";
CM_ SG_ 2633925630 EngCyl8IgntTiming "The ignition timing of the cylinder.";
CM_ SG_ 2633925630 EngCyl7IgntTiming "The ignition timing of the cylinder.";
CM_ SG_ 2633925630 EngCyl6IgntTiming "The ignition timing of the cylinder.";
CM_ SG_ 2633925630 EngCyl5IgntTiming "The ignition timing of the cylinder.";
CM_ SG_ 2633925374 EngCyl4IgntTiming "The ignition timing of the cylinder.";
CM_ SG_ 2633925374 EngCyl3IgntTiming "The ignition timing of the cylinder.";
CM_ SG_ 2633925374 EngCyl2IgntTiming "The ignition timing of the cylinder.";
CM_ SG_ 2633925374 EngCyl1IgntTiming "The ignition timing of the cylinder.";
CM_ SG_ 2633927422 EngCyl20IgntTransSecondOutput "This parameter indicates the relative intensity of the secondary output voltage of the ignition transformer.";
CM_ SG_ 2633927422 EngCyl19IgntTransSecondOutput "This parameter indicates the relative intensity of the secondary output voltage of the ignition transformer.";
CM_ SG_ 2633927422 EngCyl18IgntTransSecondOutput "This parameter indicates the relative intensity of the secondary output voltage of the ignition transformer.";
CM_ SG_ 2633927422 EngCyl17IgntTransSecondOutput "This parameter indicates the relative intensity of the secondary output voltage of the ignition transformer.";
CM_ SG_ 2633927166 EngCyl16IgntTransSecondOutput "This parameter indicates the relative intensity of the secondary output voltage of the ignition transformer.";
CM_ SG_ 2633927166 EngCyl15IgntTransSecondOutput "This parameter indicates the relative intensity of the secondary output voltage of the ignition transformer.";
CM_ SG_ 2633927166 EngCyl14IgntTransSecondOutput "This parameter indicates the relative intensity of the secondary output voltage of the ignition transformer.";
CM_ SG_ 2633927166 EngCyl13IgntTransSecondOutput "This parameter indicates the relative intensity of the secondary output voltage of the ignition transformer.";
CM_ SG_ 2633927166 EngCyl12IgntTransSecondOutput "This parameter indicates the relative intensity of the secondary output voltage of the ignition transformer.";
CM_ SG_ 2633927166 EngCyl11IgntTransSecondOutput "This parameter indicates the relative intensity of the secondary output voltage of the ignition transformer.";
CM_ SG_ 2633927166 EngCyl10IgntTransSecondOutput "This parameter indicates the relative intensity of the secondary output voltage of the ignition transformer.";
CM_ SG_ 2633927166 EngCyl9IgntTransSecondOutput "This parameter indicates the relative intensity of the secondary output voltage of the ignition transformer.";
CM_ BO_ 2633926910 "Ignition Transformer Secondary Output 1";
CM_ SG_ 2633926910 EngCyl8IgntTransSecondOutput "This parameter indicates the relative intensity of the secondary output voltage of the ignition transformer.";
CM_ SG_ 2633926910 EngCyl7IgntTransSecondOutput "This parameter indicates the relative intensity of the secondary output voltage of the ignition transformer.";
CM_ SG_ 2633926910 EngCyl6IgntTransSecondOutput "This parameter indicates the relative intensity of the secondary output voltage of the ignition transformer.";
CM_ SG_ 2633926910 EngCyl5IgntTransSecondOutput "This parameter indicates the relative intensity of the secondary output voltage of the ignition transformer.";
CM_ SG_ 2633926910 EngCyl4IgntTransSecondOutput "This parameter indicates the relative intensity of the secondary output voltage of the ignition transformer.";
CM_ SG_ 2633926910 EngCyl3IgntTransSecondOutput "This parameter indicates the relative intensity of the secondary output voltage of the ignition transformer.";
CM_ SG_ 2633926910 EngCyl2IgntTransSecondOutput "This parameter indicates the relative intensity of the secondary output voltage of the ignition transformer.";
CM_ SG_ 2633926910 EngCyl1IgntTransSecondOutput "This parameter indicates the relative intensity of the secondary output voltage of the ignition transformer.";
CM_ BO_ 2566768894 "Operator Primary Intermediate Speed Control state";
CM_ SG_ 2566768894 EngOprtrPrmryIntrmdtSpdSlctState "13 preprogrammed intermediate speed control settings are available for the controlling ECM to select. If no speed setting";
CM_ BO_ 2566769406 "The Intermediate Speed Control is widely used in the Industrial application to control the engine to an intermediate speed";
CM_ SG_ 2566769406 EngOprtrPrmryIntrmdteSpeedSelect "Allows the operator to select one of 13 preprogrammed Intermediate Speed Control settings. If no speed setting is";
CM_ BO_ 2566839550 "Idle Operation";
CM_ SG_ 2566839550 EngTotalIdleHours "Accumulated time of operation of the engine while under idle conditions.";
CM_ SG_ 2566839550 EngTotalIdleFuelUsed "Accumulated amount of fuel used during vehicle operation while under idle conditions.";
CM_ BO_ 2633934334 "Intake Manifold Information 2";
CM_ SG_ 2633934334 EngIntakeManifold6Temp "Temperature of pre-combustion air found in intake manifold number 6 of engine air supply system.";
CM_ SG_ 2633934334 EngIntakeManifold5Temp "Temperature of pre-combustion air found in intake manifold number 5 of engine air supply system.";
CM_ SG_ 2633934334 EngIntakeManifold4Temp "Temperature of pre-combustion air found in intake manifold of engine air supply system.";
CM_ SG_ 2633934334 EngIntakeManifold3Temp "Temperature of pre-combustion air found in intake manifold of engine air supply system.";
CM_ SG_ 2633934334 EngIntakeManifold2Temp "Temperature of pre-combustion air found in intake manifold of engine air supply system.";
CM_ BO_ 2566825726 "Intake Manifold Information 1";
CM_ SG_ 2566825726 EngTurbo4BoostPress "Gage pressure of air measured downstream of the compressor discharge side of the turbocharger. See also SPN 102";
CM_ SG_ 2566825726 EngTurbo3BoostPress "Gage pressure of air measured downstream of the compressor discharge side of the turbocharger. See also SPN 102";
CM_ SG_ 2566825726 EngTurbo2BoostPress "Gage pressure of air measured downstream of the compressor discharge side of the turbocharger. See also SPN 102";
CM_ SG_ 2566825726 EngTurbo1BoostPress "Gage pressure of air measured downstream of the compressor discharge side of the turbocharger. See also SPN 102";
CM_ BO_ 2566770942 "Intake/Exhaust Conditions 2 is a second PGN conveying this type of engine information. Also see PGN 65270.";
CM_ SG_ 2566770942 EngIntakeManifold2AbsPress "The absolute pressure measurement of the air intake manifold for bank 2 or the second air intake manifold. If there are";
CM_ SG_ 2566770942 EngIntakeManifold1AbsPress_01 "The absolute pressure measurement of the air intake manifold. If there are multiple air pressure sensors in the intakeThe absolute pressure measurement of the air intake manifold. If there are multiple air pressure sensors in the intake";
CM_ SG_ 2566770942 EngIntakeManifold2Press "The gage pressure measurement of the air intake manifold for bank #2 or the second air intake manifold. If there are";
CM_ SG_ 2566770942 EngAirFilter4DiffPress "Change in engine air system pressure, measured across the fourth air filter, due to the filter and any accumulation of solid";
CM_ SG_ 2566770942 EngAirFilter3DiffPress "Change in engine air system pressure, measured across the third air filter, due to the filter and any accumulation of solid";
CM_ SG_ 2566770942 EngAirFilter2DiffPress "Change in engine air system pressure, measured across the second air filter, due to the filter and any accumulation of";
CM_ SG_ 2566846206 EngCoolantFilterDiffPress "Change in coolant pressure, measured across the filter, due to the filter and any accumulation of solid or semisolid matter";
CM_ SG_ 2566846206 EngExhaustGasTemp "Temperature of combustion byproducts leaving the engine. See SPNs 2433 and 2434 for engines with more than one";
CM_ SG_ 2566846206 EngAirFilter1DiffPress "Change in engine air system pressure, measured across the filter, due to the filter and any accumulation of solid foreign";
CM_ SG_ 2566846206 EngIntakeManifold1Temp "Temperature of pre-combustion air found in intake manifold of engine air supply system.";
CM_ SG_ 2566846206 EngIntakeManifold1Press "The gage pressure measurement of the air intake manifold. If there are multiple air pressure sensors in the intake stream,";
CM_ SG_ 2566846206 EngDslPrtculateFilterIntakePress "Exhaust back pressure as a result of particle accumulation on filter media placed in the exhaust stream. See SPN 3609";
CM_ SG_ 2566846206 EngAirIntakePress "Absolute air pressure at input port to intake manifold or air box.";
CM_ SG_ 2566811134 CabHeatingZone "Parameter indicating whether the cab zone is being heated.";
CM_ SG_ 2566811134 EngHeatingZone "Parameter indicating whether the engine zone is being heated.";
CM_ SG_ 2566811134 CabVentilation "Indicates whether the cab is being ventilated or not.";
CM_ SG_ 2566811134 AuxHeaterWaterPumpStatus "Parameter indicating whether the auxiliary heater water pump is running";
CM_ SG_ 2566811134 AuxHeaterMode "State of the auxiliary heater";
CM_ SG_ 2566811134 AuxHeaterOutputPowerPercent "Current auxiliary heater output power, relative to the auxiliary heater maximum output power.";
CM_ SG_ 2566811134 AuxHeaterInputAirTemp "Temperature of the input air in an auxiliary heater system.";
CM_ SG_ 2566811134 AuxHeaterOutputCoolantTemp "Temperature of the auxiliary heater output coolant (I.e. water in a water heater system.)";
CM_ SG_ 2298375934 RearAxleRightWheelSpeed "High resolution measurement of the speed of the right wheel on the rear axle.";
CM_ SG_ 2298375934 RearAxleLeftWheelSpeed "High resolution measurement of the speed of the left wheel on the rear axle.";
CM_ SG_ 2298375934 FrontAxleRightWheelSpeed "High resolution measurement of the speed of the right wheel on the front axle.";
CM_ SG_ 2298375934 FrontAxleLeftWheelSpeed "High resolution measurement of the speed of the left wheel on the front axle.";
CM_ BO_ 2565867774 "Information to be used for a hydraulic pressure governing control system";
CM_ SG_ 2565867774 FireApparatusPumpEngagement "The measured status of the pump used to provide water in fire fighting apparatus for distribution of water through water";
CM_ SG_ 2565867774 EngHydPressGovernorSwitch "Switch that sets the mode of hydraulic governor";
CM_ SG_ 2565867774 EngHydPressGovernorModeIndicator "Mode for governor operation is hydraulic pressure control.";
CM_ SG_ 2565867774 HydPress "Hydraulic pressure measured at the output of the hydraulic pump.";
CM_ SG_ 2566841854 EngTotalRevolutions "Accumulated number of revolutions of engine crankshaft during its operation.";
CM_ SG_ 2566841854 EngTotalHoursOfOperation "Accumulated time of operation of engine.";
CM_ BO_ 2365449982 "Used for information on a hydraulic brake system";
CM_ SG_ 2365449982 HydBrakeFluidLevelSwitch "Signal which indicates whether the hydraulic fluid level in the reservoir(s) is sufficient.";
CM_ SG_ 2365449982 HydBrakeSystemAudibleWarningCmd "Signal which commands an audible warning by the hydraulic braking system.";
CM_ SG_ 2365449982 HydBrakePressSupplyStateCircuit2 "Signal which indicates whether the hydraulic brake pressure supply of circuit 2 is reliable; that is, able to support";
CM_ SG_ 2365449982 HydBrakePressSupplyStateCircuit1 "Signal which indicates whether the hydraulic brake pressure supply of circuit 1 is reliable; that is, able to support";
CM_ SG_ 2365449982 HydBrkePressWarningStateCircuit2 "Signal which indicates whether the hydraulic brake pressure of circuit 2 is below the warning level";
CM_ SG_ 2365449982 HydBrkePressWarningStateCircuit1 "Signal which indicates whether the hydraulic brake pressure of circuit 1 is below the warning level";
CM_ SG_ 2365449982 HydBrakePressCircuit2 "Gage hydraulic pressure in circuit 2 of the hydraulic brake system";
CM_ SG_ 2365449982 HydBrakePressCircuit1 "Gage hydraulic pressure in circuit 1 of the hydraulic brake system";
BA_DEF_ SG_  "SigType" ENUM  "Default","Range","RangeSigned","ASCII","Discrete","Control","ReferencePGN","DTC","StringDelimiter","StringLength","StringLengthControl";
BA_DEF_ SG_  "GenSigStartValue" INT 0 10000;
BA_DEF_ SG_  "GenSigSendType" ENUM  "Cyclic","OnWrite","OnWriteWithRepetition","OnChange","OnChangeWithRepetition","IfActive","IfActiveWithRepetition","NoSigSendType";
BA_DEF_ SG_  "GenSigILSupport" ENUM  "No","Yes";
BA_DEF_ SG_  "GenSigEVName" STRING ;
BA_DEF_ SG_  "SPN" INT 0 524287;
BA_DEF_ SG_  "SAEDocument" STRING ;
BA_DEF_ BO_  "GenMsgStartDelayTime" INT 0 100000;
BA_DEF_ BO_  "GenMsgILSupport" ENUM  "No","Yes";
BA_DEF_ BO_  "GenMsgRequestable" INT 0 1;
BA_DEF_ BO_  "GenMsgSendType" ENUM  "cyclic","NotUsed","NotUsed","NotUsed","NotUsed","NotUsed","NotUsed","IfActive","noMsgSendType";
BA_DEF_ BO_  "VFrameFormat" ENUM  "StandardCAN","ExtendedCAN","reserved","J1939PG";
BA_DEF_ BO_  "SingleFrame" INT 0 1;
BA_DEF_ BO_  "GenMsgCycleTime" INT 0 3600000;
BA_DEF_ BO_  "SAE_Document" STRING ;
BA_DEF_ SG_  "SystemSignalLongSymbol" STRING ;
BA_DEF_DEF_  "SigType" "Default";
BA_DEF_DEF_  "GenSigStartValue" 0;
BA_DEF_DEF_  "GenSigSendType" "NoSigSendType";
BA_DEF_DEF_  "GenSigILSupport" "Yes";
BA_DEF_DEF_  "GenSigEVName" "Env@Nodename_@Signame";
BA_DEF_DEF_  "SPN" 0;
BA_DEF_DEF_  "SAEDocument" "";
BA_DEF_DEF_  "GenMsgStartDelayTime" 0;
BA_DEF_DEF_  "GenMsgILSupport" "Yes";
BA_DEF_DEF_  "GenMsgRequestable" 1;
BA_DEF_DEF_  "GenMsgSendType" "noMsgSendType";
BA_DEF_DEF_  "VFrameFormat" "J1939PG";
BA_DEF_DEF_  "SingleFrame" 1;
BA_DEF_DEF_  "GenMsgCycleTime" 0;
BA_DEF_DEF_  "SAE_Document" "";
BA_DEF_DEF_  "SystemSignalLongSymbol" "";
BA_ "SAE_Document" BO_ 2365403134 "J1939-71";
BA_ "SAE_Document" BO_ 2365400062 "J1939-71";
BA_ "GenMsgSendType" BO_ 2566713598 0;
BA_ "GenMsgCycleTime" BO_ 2566713598 500;
BA_ "SAE_Document" BO_ 2566713598 "J1939-71";
BA_ "GenMsgSendType" BO_ 2499604478 0;
BA_ "GenMsgCycleTime" BO_ 2499604478 500;
BA_ "SAE_Document" BO_ 2499604478 "J1939-71";
BA_ "GenMsgSendType" BO_ 2499608830 0;
BA_ "GenMsgCycleTime" BO_ 2499608830 500;
BA_ "SAE_Document" BO_ 2499608830 "J1939-71";
BA_ "GenMsgSendType" BO_ 2432499198 0;
BA_ "GenMsgCycleTime" BO_ 2432499198 100;
BA_ "SAE_Document" BO_ 2432499198 "J1939-71";
BA_ "SAE_Document" BO_ 2633825022 "J1939-71";
BA_ "SAE_Document" BO_ 2633826046 "J1939-71";
BA_ "GenMsgSendType" BO_ 2566711294 0;
BA_ "GenMsgCycleTime" BO_ 2566711294 5000;
BA_ "SAE_Document" BO_ 2566711294 "J1939-71";
BA_ "SAE_Document" BO_ 2566749438 "J1939-71";
BA_ "GenMsgSendType" BO_ 2566715646 0;
BA_ "GenMsgCycleTime" BO_ 2566715646 1000;
BA_ "SAE_Document" BO_ 2566715646 "J1939-71";
BA_ "GenMsgSendType" BO_ 2566724606 0;
BA_ "GenMsgCycleTime" BO_ 2566724606 1000;
BA_ "SAE_Document" BO_ 2566724606 "J1939-71";
BA_ "GenMsgSendType" BO_ 2566715902 0;
BA_ "GenMsgCycleTime" BO_ 2566715902 1000;
BA_ "SAE_Document" BO_ 2566715902 "J1939-71";
BA_ "GenMsgSendType" BO_ 2566724862 0;
BA_ "GenMsgCycleTime" BO_ 2566724862 1000;
BA_ "SAE_Document" BO_ 2566724862 "J1939-71";
BA_ "GenMsgSendType" BO_ 2566718718 0;
BA_ "GenMsgCycleTime" BO_ 2566718718 1000;
BA_ "SAE_Document" BO_ 2566718718 "J1939-71";
BA_ "GenMsgSendType" BO_ 2566718974 0;
BA_ "GenMsgCycleTime" BO_ 2566718974 1000;
BA_ "SAE_Document" BO_ 2566718974 "J1939-71";
BA_ "GenMsgSendType" BO_ 2566719230 0;
BA_ "GenMsgCycleTime" BO_ 2566719230 1000;
BA_ "SAE_Document" BO_ 2566719230 "J1939-71";
BA_ "SAE_Document" BO_ 2560818942 "J1939_73";
BA_ "SAE_Document" BO_ 2561212158 "J1939-71";
BA_ "GenMsgCycleTime" BO_ 2566746366 1000;
BA_ "SAE_Document" BO_ 2566746366 "J1939-71";
BA_ "SAE_Document" BO_ 2566750206 "J1939-71";
BA_ "GenMsgSendType" BO_ 2566755582 0;
BA_ "GenMsgCycleTime" BO_ 2566755582 100;
BA_ "SAE_Document" BO_ 2566755582 "J1939-71";
BA_ "SAE_Document" BO_ 2566746110 "J1939-71";
BA_ "GenMsgSendType" BO_ 2566752510 0;
BA_ "GenMsgCycleTime" BO_ 2566752510 500;
BA_ "SAE_Document" BO_ 2566752510 "J1939-71";
BA_ "GenMsgSendType" BO_ 2566752254 0;
BA_ "GenMsgCycleTime" BO_ 2566752254 500;
BA_ "SAE_Document" BO_ 2566752254 "J1939-71";
BA_ "GenMsgSendType" BO_ 2566751998 0;
BA_ "GenMsgCycleTime" BO_ 2566751998 500;
BA_ "SAE_Document" BO_ 2566751998 "J1939-71";
BA_ "GenMsgSendType" BO_ 2566751742 0;
BA_ "GenMsgCycleTime" BO_ 2566751742 500;
BA_ "SAE_Document" BO_ 2566751742 "J1939-71";
BA_ "GenMsgSendType" BO_ 2566751486 0;
BA_ "GenMsgCycleTime" BO_ 2566751486 500;
BA_ "SAE_Document" BO_ 2566751486 "J1939-71";
BA_ "GenMsgSendType" BO_ 2499641854 0;
BA_ "GenMsgCycleTime" BO_ 2499641854 500;
BA_ "SAE_Document" BO_ 2499641854 "J1939-71";
BA_ "SAE_Document" BO_ 2566748158 "J1939-71";
BA_ "SAE_Document" BO_ 2566747902 "J1939-71";
BA_ "SAE_Document" BO_ 2566747646 "J1939-71";
BA_ "SAE_Document" BO_ 2566747390 "J1939-71";
BA_ "SAE_Document" BO_ 2566747134 "J1939-71";
BA_ "SAE_Document" BO_ 2566746878 "J1939-71";
BA_ "SAE_Document" BO_ 2561277694 "J1939-71";
BA_ "SAE_Document" BO_ 2633861886 "J1939-71";
BA_ "GenMsgSendType" BO_ 2565873150 0;
BA_ "GenMsgCycleTime" BO_ 2565873150 10;
BA_ "SAE_Document" BO_ 2565873150 "J1939-71";
BA_ "SAE_Document" BO_ 2566745854 "J1939-71";
BA_ "GenMsgSendType" BO_ 2566751230 0;
BA_ "GenMsgCycleTime" BO_ 2566751230 1000;
BA_ "SAE_Document" BO_ 2566751230 "J1939-71";
BA_ "GenMsgSendType" BO_ 2566755838 0;
BA_ "GenMsgCycleTime" BO_ 2566755838 1000;
BA_ "SAE_Document" BO_ 2566755838 "J1939-71";
BA_ "SAE_Document" BO_ 2566752766 "J1939-71";
BA_ "SAE_Document" BO_ 2633938942 "J1939-71";
BA_ "SAE_Document" BO_ 2566799614 "J1939-71";
BA_ "GenMsgSendType" BO_ 2365473278 0;
BA_ "GenMsgCycleTime" BO_ 2365473278 1000;
BA_ "SAE_Document" BO_ 2365473278 "J1939-71";
BA_ "GenMsgSendType" BO_ 2365485822 0;
BA_ "GenMsgCycleTime" BO_ 2365485822 50;
BA_ "SAE_Document" BO_ 2365485822 "J1939-71";
BA_ "SAE_Document" BO_ 2633926654 "J1939-71";
BA_ "SAE_Document" BO_ 2633926398 "J1939-71";
BA_ "SAE_Document" BO_ 2633926142 "J1939-71";
BA_ "SAE_Document" BO_ 2633925886 "J1939-71";
BA_ "SAE_Document" BO_ 2633925630 "J1939-71";
BA_ "SAE_Document" BO_ 2633925374 "J1939-71";
BA_ "SAE_Document" BO_ 2633927422 "J1939-71";
BA_ "SAE_Document" BO_ 2633927166 "J1939-71";
BA_ "SAE_Document" BO_ 2633926910 "J1939-71";
BA_ "GenMsgSendType" BO_ 2566768894 0;
BA_ "GenMsgCycleTime" BO_ 2566768894 1000;
BA_ "SAE_Document" BO_ 2566768894 "J1939-71";
BA_ "GenMsgSendType" BO_ 2566769406 0;
BA_ "GenMsgCycleTime" BO_ 2566769406 1000;
BA_ "SAE_Document" BO_ 2566769406 "J1939-71";
BA_ "SAE_Document" BO_ 2566839550 "J1939-71";
BA_ "GenMsgSendType" BO_ 2633934334 0;
BA_ "GenMsgCycleTime" BO_ 2633934334 1000;
BA_ "SAE_Document" BO_ 2633934334 "J1939-71";
BA_ "GenMsgSendType" BO_ 2566825726 0;
BA_ "GenMsgCycleTime" BO_ 2566825726 500;
BA_ "SAE_Document" BO_ 2566825726 "J1939-71";
BA_ "GenMsgSendType" BO_ 2566770942 0;
BA_ "GenMsgCycleTime" BO_ 2566770942 5000;
BA_ "SAE_Document" BO_ 2566770942 "J1939-71";
BA_ "GenMsgSendType" BO_ 2566846206 0;
BA_ "GenMsgCycleTime" BO_ 2566846206 5000;
BA_ "SAE_Document" BO_ 2566846206 "J1939-71";
BA_ "GenMsgSendType" BO_ 2566811134 0;
BA_ "GenMsgCycleTime" BO_ 2566811134 1000;
BA_ "SAE_Document" BO_ 2566811134 "J1939-71";
BA_ "GenMsgSendType" BO_ 2298375934 0;
BA_ "GenMsgCycleTime" BO_ 2298375934 20;
BA_ "SAE_Document" BO_ 2298375934 "J1939-71";
BA_ "GenMsgSendType" BO_ 2565867774 0;
BA_ "GenMsgCycleTime" BO_ 2565867774 50;
BA_ "SAE_Document" BO_ 2565867774 "J1939-71";
BA_ "SAE_Document" BO_ 2566841854 "J1939-71";
BA_ "GenMsgSendType" BO_ 2365449982 0;
BA_ "GenMsgCycleTime" BO_ 2365449982 100;
BA_ "SAE_Document" BO_ 2365449982 "J1939-71";
BA_ "SigType" SG_ 2365403134 Jystick4GripXAxisDetentPosStatus 4;
BA_ "SPN" SG_ 2365403134 Jystick4GripXAxisDetentPosStatus 4527;
BA_ "SAEDocument" SG_ 2365403134 Jystick4GripXAxisDetentPosStatus "J1939-71";
BA_ "SigType" SG_ 2365403134 Jystick4GripYAxisDetentPosStatus 4;
BA_ "SPN" SG_ 2365403134 Jystick4GripYAxisDetentPosStatus 4526;
BA_ "SAEDocument" SG_ 2365403134 Jystick4GripYAxisDetentPosStatus "J1939-71";
BA_ "SigType" SG_ 2365403134 Jystick4ThetaAxisDetentPosStatus 4;
BA_ "SPN" SG_ 2365403134 Jystick4ThetaAxisDetentPosStatus 4525;
BA_ "SAEDocument" SG_ 2365403134 Jystick4ThetaAxisDetentPosStatus "J1939-71";
BA_ "SPN" SG_ 2365403134 Joystick4ThetaAxisPos 4524;
BA_ "SAEDocument" SG_ 2365403134 Joystick4ThetaAxisPos "J1939-71";
BA_ "SigType" SG_ 2365403134 Jystck4ThtAxsClckwsPstvPosStatus 4;
BA_ "SPN" SG_ 2365403134 Jystck4ThtAxsClckwsPstvPosStatus 4523;
BA_ "SAEDocument" SG_ 2365403134 Jystck4ThtAxsClckwsPstvPosStatus "J1939-71";
BA_ "SigType" SG_ 2365403134 Jystck4ThtAxsCntrClckwsNgtvPsStt 4;
BA_ "SPN" SG_ 2365403134 Jystck4ThtAxsCntrClckwsNgtvPsStt 4522;
BA_ "SAEDocument" SG_ 2365403134 Jystck4ThtAxsCntrClckwsNgtvPsStt "J1939-71";
BA_ "SigType" SG_ 2365403134 Jystck4ThetaAxisNeutralPosStatus 4;
BA_ "SPN" SG_ 2365403134 Jystck4ThetaAxisNeutralPosStatus 4521;
BA_ "SAEDocument" SG_ 2365403134 Jystck4ThetaAxisNeutralPosStatus "J1939-71";
BA_ "SPN" SG_ 2365403134 Joystick4GripYAxisPos 4520;
BA_ "SAEDocument" SG_ 2365403134 Joystick4GripYAxisPos "J1939-71";
BA_ "SigType" SG_ 2365403134 Jystck4GrpYAxsLvrFrwrdPstvPsStts 4;
BA_ "SPN" SG_ 2365403134 Jystck4GrpYAxsLvrFrwrdPstvPsStts 4519;
BA_ "SAEDocument" SG_ 2365403134 Jystck4GrpYAxsLvrFrwrdPstvPsStts "J1939-71";
BA_ "SigType" SG_ 2365403134 Jystck4GrpYAxsLvrBckNgtvPsStatus 4;
BA_ "SPN" SG_ 2365403134 Jystck4GrpYAxsLvrBckNgtvPsStatus 4518;
BA_ "SAEDocument" SG_ 2365403134 Jystck4GrpYAxsLvrBckNgtvPsStatus "J1939-71";
BA_ "SigType" SG_ 2365403134 Jystck4GripYAxisNeutralPosStatus 4;
BA_ "SPN" SG_ 2365403134 Jystck4GripYAxisNeutralPosStatus 4517;
BA_ "SAEDocument" SG_ 2365403134 Jystck4GripYAxisNeutralPosStatus "J1939-71";
BA_ "SPN" SG_ 2365403134 Joystick4GripXAxisPos 4516;
BA_ "SAEDocument" SG_ 2365403134 Joystick4GripXAxisPos "J1939-71";
BA_ "SigType" SG_ 2365403134 Jystck4GrpXAxsLvrRghtPstvPsSttus 4;
BA_ "SPN" SG_ 2365403134 Jystck4GrpXAxsLvrRghtPstvPsSttus 4515;
BA_ "SAEDocument" SG_ 2365403134 Jystck4GrpXAxsLvrRghtPstvPsSttus "J1939-71";
BA_ "SigType" SG_ 2365403134 Jystck4GrpXAxsLvrLftNgtvPsStatus 4;
BA_ "SPN" SG_ 2365403134 Jystck4GrpXAxsLvrLftNgtvPsStatus 4514;
BA_ "SAEDocument" SG_ 2365403134 Jystck4GrpXAxsLvrLftNgtvPsStatus "J1939-71";
BA_ "SigType" SG_ 2365403134 Jystck4GripXAxisNeutralPosStatus 4;
BA_ "SPN" SG_ 2365403134 Jystck4GripXAxisNeutralPosStatus 4513;
BA_ "SAEDocument" SG_ 2365403134 Jystck4GripXAxisNeutralPosStatus "J1939-71";
BA_ "SigType" SG_ 2365400062 Jystck10GripXAxisDetentPosStatus 4;
BA_ "SPN" SG_ 2365400062 Jystck10GripXAxisDetentPosStatus 4749;
BA_ "SAEDocument" SG_ 2365400062 Jystck10GripXAxisDetentPosStatus "J1939-71";
BA_ "SigType" SG_ 2365400062 Jystck10GripYAxisDetentPosStatus 4;
BA_ "SPN" SG_ 2365400062 Jystck10GripYAxisDetentPosStatus 4748;
BA_ "SAEDocument" SG_ 2365400062 Jystck10GripYAxisDetentPosStatus "J1939-71";
BA_ "SigType" SG_ 2365400062 Jystck10ThetaAxisDetentPosStatus 4;
BA_ "SPN" SG_ 2365400062 Jystck10ThetaAxisDetentPosStatus 4747;
BA_ "SAEDocument" SG_ 2365400062 Jystck10ThetaAxisDetentPosStatus "J1939-71";
BA_ "SPN" SG_ 2365400062 Joystick10ThetaAxisPos 4746;
BA_ "SAEDocument" SG_ 2365400062 Joystick10ThetaAxisPos "J1939-71";
BA_ "SigType" SG_ 2365400062 Jystck10ThtAxsClckwsPstvPsStatus 4;
BA_ "SPN" SG_ 2365400062 Jystck10ThtAxsClckwsPstvPsStatus 4745;
BA_ "SAEDocument" SG_ 2365400062 Jystck10ThtAxsClckwsPstvPsStatus "J1939-71";
BA_ "SigType" SG_ 2365400062 Jystck10ThtAxsCntrClckwsNgtvPsSt 4;
BA_ "SPN" SG_ 2365400062 Jystck10ThtAxsCntrClckwsNgtvPsSt 4744;
BA_ "SAEDocument" SG_ 2365400062 Jystck10ThtAxsCntrClckwsNgtvPsSt "J1939-71";
BA_ "SigType" SG_ 2365400062 Jystck10ThtaAxisNeutralPosStatus 4;
BA_ "SPN" SG_ 2365400062 Jystck10ThtaAxisNeutralPosStatus 4743;
BA_ "SAEDocument" SG_ 2365400062 Jystck10ThtaAxisNeutralPosStatus "J1939-71";
BA_ "SPN" SG_ 2365400062 Joystick10GripYAxisPos 4742;
BA_ "SAEDocument" SG_ 2365400062 Joystick10GripYAxisPos "J1939-71";
BA_ "SigType" SG_ 2365400062 Jystck10GrpYAxsLvrFrwrdPstvPsStt 4;
BA_ "SPN" SG_ 2365400062 Jystck10GrpYAxsLvrFrwrdPstvPsStt 4741;
BA_ "SAEDocument" SG_ 2365400062 Jystck10GrpYAxsLvrFrwrdPstvPsStt "J1939-71";
BA_ "SigType" SG_ 2365400062 Jystck10GrpYAxsLvrBckNgtvPsSttus 4;
BA_ "SPN" SG_ 2365400062 Jystck10GrpYAxsLvrBckNgtvPsSttus 4740;
BA_ "SAEDocument" SG_ 2365400062 Jystck10GrpYAxsLvrBckNgtvPsSttus "J1939-71";
BA_ "SigType" SG_ 2365400062 Jystck10GrpYAxisNeutralPosStatus 4;
BA_ "SPN" SG_ 2365400062 Jystck10GrpYAxisNeutralPosStatus 4739;
BA_ "SAEDocument" SG_ 2365400062 Jystck10GrpYAxisNeutralPosStatus "J1939-71";
BA_ "SPN" SG_ 2365400062 Joystick10GripXAxisPos 4738;
BA_ "SAEDocument" SG_ 2365400062 Joystick10GripXAxisPos "J1939-71";
BA_ "SigType" SG_ 2365400062 Jystck10GrpXAxsLvrRghtPstvPsStts 4;
BA_ "SPN" SG_ 2365400062 Jystck10GrpXAxsLvrRghtPstvPsStts 4737;
BA_ "SAEDocument" SG_ 2365400062 Jystck10GrpXAxsLvrRghtPstvPsStts "J1939-71";
BA_ "SigType" SG_ 2365400062 Jystck10GrpXAxsLvrLftNgtvPsSttus 4;
BA_ "SPN" SG_ 2365400062 Jystck10GrpXAxsLvrLftNgtvPsSttus 4736;
BA_ "SAEDocument" SG_ 2365400062 Jystck10GrpXAxsLvrLftNgtvPsSttus "J1939-71";
BA_ "SigType" SG_ 2365400062 Jystck10GrpXAxisNeutralPosStatus 4;
BA_ "SPN" SG_ 2365400062 Jystck10GrpXAxisNeutralPosStatus 4735;
BA_ "SAEDocument" SG_ 2365400062 Jystck10GrpXAxisNeutralPosStatus "J1939-71";
BA_ "SigType" SG_ 2566713598 EngFuelFilterIntakeAbsPress 1;
BA_ "SPN" SG_ 2566713598 EngFuelFilterIntakeAbsPress 5417;
BA_ "SAEDocument" SG_ 2566713598 EngFuelFilterIntakeAbsPress "J1939-71";
BA_ "SigType" SG_ 2499604478 EngExhstGsRcrcltn1OutletAbsPress 1;
BA_ "SPN" SG_ 2499604478 EngExhstGsRcrcltn1OutletAbsPress 5431;
BA_ "SAEDocument" SG_ 2499604478 EngExhstGsRcrcltn1OutletAbsPress "J1939-71";
BA_ "SigType" SG_ 2499604478 EngExhstGsRcrcltn1IntakeAbsPress 1;
BA_ "SPN" SG_ 2499604478 EngExhstGsRcrcltn1IntakeAbsPress 5430;
BA_ "SAEDocument" SG_ 2499604478 EngExhstGsRcrcltn1IntakeAbsPress "J1939-71";
BA_ "SigType" SG_ 2499608830 EngExhstGsRcrcltn2IntakeAbsPress 1;
BA_ "SPN" SG_ 2499608830 EngExhstGsRcrcltn2IntakeAbsPress 5429;
BA_ "SAEDocument" SG_ 2499608830 EngExhstGsRcrcltn2IntakeAbsPress "J1939-71";
BA_ "SigType" SG_ 2499608830 EngExhstGsRcrcltn2OutletAbsPress 1;
BA_ "SPN" SG_ 2499608830 EngExhstGsRcrcltn2OutletAbsPress 5254;
BA_ "SAEDocument" SG_ 2499608830 EngExhstGsRcrcltn2OutletAbsPress "J1939-71";
BA_ "SigType" SG_ 2499608830 EngExhstGsRcrclation2IntakePress 1;
BA_ "SPN" SG_ 2499608830 EngExhstGsRcrclation2IntakePress 5253;
BA_ "SAEDocument" SG_ 2499608830 EngExhstGsRcrclation2IntakePress "J1939-71";
BA_ "SigType" SG_ 2499608830 EngExhstGsRcirculation2DiffPress 1;
BA_ "SPN" SG_ 2499608830 EngExhstGsRcirculation2DiffPress 5252;
BA_ "SAEDocument" SG_ 2499608830 EngExhstGsRcirculation2DiffPress "J1939-71";
BA_ "SigType" SG_ 2432499198 CmmndedEngFuelInjectionCtrlPress 1;
BA_ "SPN" SG_ 2432499198 CmmndedEngFuelInjectionCtrlPress 5314;
BA_ "SAEDocument" SG_ 2432499198 CmmndedEngFuelInjectionCtrlPress "J1939-71";
BA_ "SigType" SG_ 2432499198 CommandedEngFuelRailPress 1;
BA_ "SPN" SG_ 2432499198 CommandedEngFuelRailPress 5313;
BA_ "SAEDocument" SG_ 2432499198 CommandedEngFuelRailPress "J1939-71";
BA_ "SigType" SG_ 2432499198 EngExhstGsRcirculation2Valve2Pos 1;
BA_ "SPN" SG_ 2432499198 EngExhstGsRcirculation2Valve2Pos 5263;
BA_ "SAEDocument" SG_ 2432499198 EngExhstGsRcirculation2Valve2Pos "J1939-71";
BA_ "SigType" SG_ 2432499198 EngExhstGsRecirculation2ValvePos 1;
BA_ "SPN" SG_ 2432499198 EngExhstGsRecirculation2ValvePos 5262;
BA_ "SAEDocument" SG_ 2432499198 EngExhstGsRecirculation2ValvePos "J1939-71";
BA_ "SigType" SG_ 2633825022 EngExhstGsRcrculation2Valve2Ctrl 1;
BA_ "SPN" SG_ 2633825022 EngExhstGsRcrculation2Valve2Ctrl 5265;
BA_ "SAEDocument" SG_ 2633825022 EngExhstGsRcrculation2Valve2Ctrl "J1939-71";
BA_ "SigType" SG_ 2633825022 EngExhstGsRcirculation2ValveCtrl 1;
BA_ "SPN" SG_ 2633825022 EngExhstGsRcirculation2ValveCtrl 5264;
BA_ "SAEDocument" SG_ 2633825022 EngExhstGsRcirculation2ValveCtrl "J1939-71";
BA_ "SigType" SG_ 2633826046 EGR2CoolerBypassActuatorPos 1;
BA_ "SPN" SG_ 2633826046 EGR2CoolerBypassActuatorPos 5261;
BA_ "SAEDocument" SG_ 2633826046 EGR2CoolerBypassActuatorPos "J1939-71";
BA_ "SigType" SG_ 2633826046 EngExhstGsRcrcltn2ClerEfficiency 1;
BA_ "SPN" SG_ 2633826046 EngExhstGsRcrcltn2ClerEfficiency 5260;
BA_ "SAEDocument" SG_ 2633826046 EngExhstGsRcrcltn2ClerEfficiency "J1939-71";
BA_ "SigType" SG_ 2633826046 EngExhstGsRcrcltn2ClrIntkGsAbsPr 1;
BA_ "SPN" SG_ 2633826046 EngExhstGsRcrcltn2ClrIntkGsAbsPr 5259;
BA_ "SAEDocument" SG_ 2633826046 EngExhstGsRcrcltn2ClrIntkGsAbsPr "J1939-71";
BA_ "SigType" SG_ 2633826046 EngExhstGsRcrcltn2ClerIntakeTemp 1;
BA_ "SPN" SG_ 2633826046 EngExhstGsRcrcltn2ClerIntakeTemp 5258;
BA_ "SAEDocument" SG_ 2633826046 EngExhstGsRcrcltn2ClerIntakeTemp "J1939-71";
BA_ "SigType" SG_ 2566711294 EngFrctnPrcentTorqueAtIdlePoint7 1;
BA_ "SPN" SG_ 2566711294 EngFrctnPrcentTorqueAtIdlePoint7 5477;
BA_ "SAEDocument" SG_ 2566711294 EngFrctnPrcentTorqueAtIdlePoint7 "J1939-71";
BA_ "SigType" SG_ 2566711294 EngFrctnPrcentTorqueAtIdlePoint6 1;
BA_ "SPN" SG_ 2566711294 EngFrctnPrcentTorqueAtIdlePoint6 5476;
BA_ "SAEDocument" SG_ 2566711294 EngFrctnPrcentTorqueAtIdlePoint6 "J1939-71";
BA_ "SigType" SG_ 2566711294 EngFrctnPrcentTorqueAtIdlePoint5 1;
BA_ "SPN" SG_ 2566711294 EngFrctnPrcentTorqueAtIdlePoint5 5475;
BA_ "SAEDocument" SG_ 2566711294 EngFrctnPrcentTorqueAtIdlePoint5 "J1939-71";
BA_ "SigType" SG_ 2566711294 EngFrctnPrcentTorqueAtIdlePoint4 1;
BA_ "SPN" SG_ 2566711294 EngFrctnPrcentTorqueAtIdlePoint4 5474;
BA_ "SAEDocument" SG_ 2566711294 EngFrctnPrcentTorqueAtIdlePoint4 "J1939-71";
BA_ "SigType" SG_ 2566711294 EngFrctnPrcentTorqueAtIdlePoint3 1;
BA_ "SPN" SG_ 2566711294 EngFrctnPrcentTorqueAtIdlePoint3 5473;
BA_ "SAEDocument" SG_ 2566711294 EngFrctnPrcentTorqueAtIdlePoint3 "J1939-71";
BA_ "SigType" SG_ 2566711294 EngFrctnPrcentTorqueAtIdlePoint2 1;
BA_ "SPN" SG_ 2566711294 EngFrctnPrcentTorqueAtIdlePoint2 5472;
BA_ "SAEDocument" SG_ 2566711294 EngFrctnPrcentTorqueAtIdlePoint2 "J1939-71";
BA_ "SigType" SG_ 2566711294 EngFrctnPrcentTorqueAtIdlePoint1 1;
BA_ "SPN" SG_ 2566711294 EngFrctnPrcentTorqueAtIdlePoint1 5471;
BA_ "SAEDocument" SG_ 2566711294 EngFrctnPrcentTorqueAtIdlePoint1 "J1939-71";
BA_ "SPN" SG_ 2566749438 DslPrtcltFltrActvRgnrtnFrcdSttus 4175;
BA_ "SAEDocument" SG_ 2566749438 DslPrtcltFltrActvRgnrtnFrcdSttus "J1939-71";
BA_ "SPN" SG_ 2566749438 ExhaustSystemHighTempLampCmd 3698;
BA_ "SAEDocument" SG_ 2566749438 ExhaustSystemHighTempLampCmd "J1939-71";
BA_ "SigType" SG_ 2566749438 DslPrtcltFltrAtmtcActvRgnrtnIntt 5;
BA_ "SPN" SG_ 2566749438 DslPrtcltFltrAtmtcActvRgnrtnIntt 3718;
BA_ "SAEDocument" SG_ 2566749438 DslPrtcltFltrAtmtcActvRgnrtnIntt "J1939-71";
BA_ "SigType" SG_ 2566749438 DslPrtcltFltrActvRgnrtnInhbtdDTV 4;
BA_ "SPN" SG_ 2566749438 DslPrtcltFltrActvRgnrtnInhbtdDTV 3717;
BA_ "SAEDocument" SG_ 2566749438 DslPrtcltFltrActvRgnrtnInhbtdDTV "J1939-71";
BA_ "SystemSignalLongSymbol" SG_ 2566749438 DslPrtcltFltrActvRgnrtnInhbtdDTV "DslPrtcltFltrActvRgnrtnInhbtdDTVhclSpdBlwAllwd";
BA_ "SigType" SG_ 2566749438 DslPrtcltFltrActvRgnrtnInhbtdDTE 4;
BA_ "SPN" SG_ 2566749438 DslPrtcltFltrActvRgnrtnInhbtdDTE 3716;
BA_ "SAEDocument" SG_ 2566749438 DslPrtcltFltrActvRgnrtnInhbtdDTE "J1939-71";
BA_ "SystemSignalLongSymbol" SG_ 2566749438 DslPrtcltFltrActvRgnrtnInhbtdDTE "DslPrtcltFltrActvRgnrtnInhbtdDTEngNtWrmdUp";
BA_ "SigType" SG_ 2566749438 DslPrtcltFltrActvRgnrtnInhb_0000 4;
BA_ "SPN" SG_ 2566749438 DslPrtcltFltrActvRgnrtnInhb_0000 3715;
BA_ "SAEDocument" SG_ 2566749438 DslPrtcltFltrActvRgnrtnInhb_0000 "J1939-71";
BA_ "SystemSignalLongSymbol" SG_ 2566749438 DslPrtcltFltrActvRgnrtnInhb_0000 "DslPrtcltFltrActvRgnrtnInhbtdDTPrmnntSystmLckt";
BA_ "SigType" SG_ 2566749438 DslPrtcltFltrActvRgnrtnInhbtdDTT 5;
BA_ "SPN" SG_ 2566749438 DslPrtcltFltrActvRgnrtnInhbtdDTT 3714;
BA_ "SAEDocument" SG_ 2566749438 DslPrtcltFltrActvRgnrtnInhbtdDTT "J1939-71";
BA_ "SigType" SG_ 2566749438 DslPrtcltFltrActvRgnrtn_DTS_02 5;
BA_ "SPN" SG_ 2566749438 DslPrtcltFltrActvRgnrtn_DTS_02 3705;
BA_ "SAEDocument" SG_ 2566749438 DslPrtcltFltrActvRgnrtn_DTS_02 "J1939-71";
BA_ "SigType" SG_ 2566749438 DslPrtcltFltrActvRgnrtnInhbtdDTL 4;
BA_ "SPN" SG_ 2566749438 DslPrtcltFltrActvRgnrtnInhbtdDTL 3711;
BA_ "SAEDocument" SG_ 2566749438 DslPrtcltFltrActvRgnrtnInhbtdDTL "J1939-71";
BA_ "SigType" SG_ 2566749438 DslPrtcltFltrActvRgnrtnInhb_0001 4;
BA_ "SPN" SG_ 2566749438 DslPrtcltFltrActvRgnrtnInhb_0001 3710;
BA_ "SAEDocument" SG_ 2566749438 DslPrtcltFltrActvRgnrtnInhb_0001 "J1939-71";
BA_ "SystemSignalLongSymbol" SG_ 2566749438 DslPrtcltFltrActvRgnrtnInhb_0001 "DslPrtcltFltrActvRgnrtnInhbtdDTPrkngBrkNtSt";
BA_ "SigType" SG_ 2566749438 DslPrtcltFltrActvRgnrtnInhb_0002 4;
BA_ "SPN" SG_ 2566749438 DslPrtcltFltrActvRgnrtnInhb_0002 3709;
BA_ "SAEDocument" SG_ 2566749438 DslPrtcltFltrActvRgnrtnInhb_0002 "J1939-71";
BA_ "SystemSignalLongSymbol" SG_ 2566749438 DslPrtcltFltrActvRgnrtnInhb_0002 "DslPrtcltFltrActvRgnrtnInhbtdDTVhclSpdAbvAllwd";
BA_ "SigType" SG_ 2566749438 DslPrtcltFltrActvRgnrtnInhbtdDTO 4;
BA_ "SPN" SG_ 2566749438 DslPrtcltFltrActvRgnrtnInhbtdDTO 3708;
BA_ "SAEDocument" SG_ 2566749438 DslPrtcltFltrActvRgnrtnInhbtdDTO "J1939-71";
BA_ "SystemSignalLongSymbol" SG_ 2566749438 DslPrtcltFltrActvRgnrtnInhbtdDTO "DslPrtcltFltrActvRgnrtnInhbtdDTOtOfNtrl";
BA_ "SigType" SG_ 2566749438 DslPrtcltFltrActvRgnrtnInhbtdDTA 5;
BA_ "SPN" SG_ 2566749438 DslPrtcltFltrActvRgnrtnInhbtdDTA 3707;
BA_ "SAEDocument" SG_ 2566749438 DslPrtcltFltrActvRgnrtnInhbtdDTA "J1939-71";
BA_ "SigType" SG_ 2566749438 DslPrtcltFltrActvRgnrtnInhbtdDTP 5;
BA_ "SPN" SG_ 2566749438 DslPrtcltFltrActvRgnrtnInhbtdDTP 3706;
BA_ "SAEDocument" SG_ 2566749438 DslPrtcltFltrActvRgnrtnInhbtdDTP "J1939-71";
BA_ "SigType" SG_ 2566749438 DslPrtcltFltrActvRgnrtnInhbtdDTC 5;
BA_ "SPN" SG_ 2566749438 DslPrtcltFltrActvRgnrtnInhbtdDTC 3704;
BA_ "SAEDocument" SG_ 2566749438 DslPrtcltFltrActvRgnrtnInhbtdDTC "J1939-71";
BA_ "SigType" SG_ 2566749438 DslPrtcltFltrActvRgnrtnInhbtdDTI 5;
BA_ "SPN" SG_ 2566749438 DslPrtcltFltrActvRgnrtnInhbtdDTI 3703;
BA_ "SAEDocument" SG_ 2566749438 DslPrtcltFltrActvRgnrtnInhbtdDTI "J1939-71";
BA_ "SigType" SG_ 2566749438 DslPrtcltFltrActvRgnrtnInhbtdStt 5;
BA_ "SPN" SG_ 2566749438 DslPrtcltFltrActvRgnrtnInhbtdStt 3702;
BA_ "SAEDocument" SG_ 2566749438 DslPrtcltFltrActvRgnrtnInhbtdStt "J1939-71";
BA_ "SPN" SG_ 2566749438 DieselParticulateFilterStatus 3701;
BA_ "SAEDocument" SG_ 2566749438 DieselParticulateFilterStatus "J1939-71";
BA_ "SigType" SG_ 2566749438 DslPrtcltFltrActvRgnrationStatus 5;
BA_ "SPN" SG_ 2566749438 DslPrtcltFltrActvRgnrationStatus 3700;
BA_ "SAEDocument" SG_ 2566749438 DslPrtcltFltrActvRgnrationStatus "J1939-71";
BA_ "SigType" SG_ 2566749438 DslPrtcltFltrPssvRgnrationStatus 5;
BA_ "SPN" SG_ 2566749438 DslPrtcltFltrPssvRgnrationStatus 3699;
BA_ "SAEDocument" SG_ 2566749438 DslPrtcltFltrPssvRgnrationStatus "J1939-71";
BA_ "SPN" SG_ 2566749438 DieselParticulateFilterLampCmd 3697;
BA_ "SAEDocument" SG_ 2566749438 DieselParticulateFilterLampCmd "J1939-71";
BA_ "SigType" SG_ 2566715646 DslPrtculateFilter2SootSignalMin 1;
BA_ "SPN" SG_ 2566715646 DslPrtculateFilter2SootSignalMin 5271;
BA_ "SAEDocument" SG_ 2566715646 DslPrtculateFilter2SootSignalMin "J1939-71";
BA_ "SigType" SG_ 2566715646 DslPrtculateFilter2SootSignalMax 1;
BA_ "SPN" SG_ 2566715646 DslPrtculateFilter2SootSignalMax 5270;
BA_ "SAEDocument" SG_ 2566715646 DslPrtculateFilter2SootSignalMax "J1939-71";
BA_ "SigType" SG_ 2566715646 DslPrtcltFltr2StSgnlStndrdDvtion 1;
BA_ "SPN" SG_ 2566715646 DslPrtcltFltr2StSgnlStndrdDvtion 5269;
BA_ "SAEDocument" SG_ 2566715646 DslPrtcltFltr2StSgnlStndrdDvtion "J1939-71";
BA_ "SPN" SG_ 2566724606 DslPrtcltFltr2StSnsrPrlminaryFMI 4790;
BA_ "SAEDocument" SG_ 2566724606 DslPrtcltFltr2StSnsrPrlminaryFMI "J1939-71";
BA_ "SigType" SG_ 2566724606 DslPrtcltFilter2MedianSootSignal 1;
BA_ "SPN" SG_ 2566724606 DslPrtcltFilter2MedianSootSignal 4789;
BA_ "SAEDocument" SG_ 2566724606 DslPrtcltFilter2MedianSootSignal "J1939-71";
BA_ "SigType" SG_ 2566724606 DslPrtclateFilter2MeanSootSignal 1;
BA_ "SPN" SG_ 2566724606 DslPrtclateFilter2MeanSootSignal 4788;
BA_ "SAEDocument" SG_ 2566724606 DslPrtclateFilter2MeanSootSignal "J1939-71";
BA_ "SigType" SG_ 2566724606 DslParticulateFilter2SootDensity 1;
BA_ "SPN" SG_ 2566724606 DslParticulateFilter2SootDensity 4787;
BA_ "SAEDocument" SG_ 2566724606 DslParticulateFilter2SootDensity "J1939-71";
BA_ "SigType" SG_ 2566724606 DieselParticulateFilter2SootMass 1;
BA_ "SPN" SG_ 2566724606 DieselParticulateFilter2SootMass 4786;
BA_ "SAEDocument" SG_ 2566724606 DieselParticulateFilter2SootMass "J1939-71";
BA_ "SigType" SG_ 2566715902 DslPrtculateFilter1SootSignalMin 1;
BA_ "SPN" SG_ 2566715902 DslPrtculateFilter1SootSignalMin 5268;
BA_ "SAEDocument" SG_ 2566715902 DslPrtculateFilter1SootSignalMin "J1939-71";
BA_ "SigType" SG_ 2566715902 DslPrtculateFilter1SootSignalMax 1;
BA_ "SPN" SG_ 2566715902 DslPrtculateFilter1SootSignalMax 5267;
BA_ "SAEDocument" SG_ 2566715902 DslPrtculateFilter1SootSignalMax "J1939-71";
BA_ "SigType" SG_ 2566715902 DslPrtcltFltr1StSgnlStndrdDvtion 1;
BA_ "SPN" SG_ 2566715902 DslPrtcltFltr1StSgnlStndrdDvtion 5266;
BA_ "SAEDocument" SG_ 2566715902 DslPrtcltFltr1StSgnlStndrdDvtion "J1939-71";
BA_ "SPN" SG_ 2566724862 DslPrtcltFltr1StSnsrPrlminaryFMI 4785;
BA_ "SAEDocument" SG_ 2566724862 DslPrtcltFltr1StSnsrPrlminaryFMI "J1939-71";
BA_ "SigType" SG_ 2566724862 DslPrtcltFilter1MedianSootSignal 1;
BA_ "SPN" SG_ 2566724862 DslPrtcltFilter1MedianSootSignal 4784;
BA_ "SAEDocument" SG_ 2566724862 DslPrtcltFilter1MedianSootSignal "J1939-71";
BA_ "SigType" SG_ 2566724862 DslPrtclateFilter1MeanSootSignal 1;
BA_ "SPN" SG_ 2566724862 DslPrtclateFilter1MeanSootSignal 4783;
BA_ "SAEDocument" SG_ 2566724862 DslPrtclateFilter1MeanSootSignal "J1939-71";
BA_ "SigType" SG_ 2566724862 DslParticulateFilter1SootDensity 1;
BA_ "SPN" SG_ 2566724862 DslParticulateFilter1SootDensity 4782;
BA_ "SAEDocument" SG_ 2566724862 DslParticulateFilter1SootDensity "J1939-71";
BA_ "SigType" SG_ 2566724862 DieselParticulateFilter1SootMass 1;
BA_ "SPN" SG_ 2566724862 DieselParticulateFilter1SootMass 4781;
BA_ "SAEDocument" SG_ 2566724862 DieselParticulateFilter1SootMass "J1939-71";
BA_ "SigType" SG_ 2566718718 VehicleBatteryChargingLampData 4;
BA_ "SPN" SG_ 2566718718 VehicleBatteryChargingLampData 5108;
BA_ "SAEDocument" SG_ 2566718718 VehicleBatteryChargingLampData "J1939-71";
BA_ "SigType" SG_ 2566718718 VehicleHVACRecirculationLampData 4;
BA_ "SPN" SG_ 2566718718 VehicleHVACRecirculationLampData 5107;
BA_ "SAEDocument" SG_ 2566718718 VehicleHVACRecirculationLampData "J1939-71";
BA_ "SigType" SG_ 2566718718 VehicleAirPressLowLampData 4;
BA_ "SPN" SG_ 2566718718 VehicleAirPressLowLampData 5106;
BA_ "SAEDocument" SG_ 2566718718 VehicleAirPressLowLampData "J1939-71";
BA_ "SigType" SG_ 2566718718 VehicleFuelLevelLowLampData 4;
BA_ "SPN" SG_ 2566718718 VehicleFuelLevelLowLampData 5105;
BA_ "SAEDocument" SG_ 2566718718 VehicleFuelLevelLowLampData "J1939-71";
BA_ "SigType" SG_ 2566718718 VehicleBatteryVoltageLowLampData 4;
BA_ "SPN" SG_ 2566718718 VehicleBatteryVoltageLowLampData 5104;
BA_ "SAEDocument" SG_ 2566718718 VehicleBatteryVoltageLowLampData "J1939-71";
BA_ "SigType" SG_ 2566718974 EngWaitToStartLampData 4;
BA_ "SPN" SG_ 2566718974 EngWaitToStartLampData 5416;
BA_ "SAEDocument" SG_ 2566718974 EngWaitToStartLampData "J1939-71";
BA_ "SigType" SG_ 2566718974 EngFuelFilterRestrictedLampData 5;
BA_ "SPN" SG_ 2566718974 EngFuelFilterRestrictedLampData 5470;
BA_ "SAEDocument" SG_ 2566718974 EngFuelFilterRestrictedLampData "J1939-71";
BA_ "SigType" SG_ 2566718974 EngAirFilterRestrictionLampData 4;
BA_ "SPN" SG_ 2566718974 EngAirFilterRestrictionLampData 5103;
BA_ "SAEDocument" SG_ 2566718974 EngAirFilterRestrictionLampData "J1939-71";
BA_ "SigType" SG_ 2566718974 EngIdleManagementActiveLampData 4;
BA_ "SPN" SG_ 2566718974 EngIdleManagementActiveLampData 5102;
BA_ "SAEDocument" SG_ 2566718974 EngIdleManagementActiveLampData "J1939-71";
BA_ "SigType" SG_ 2566718974 EngCoolantLevelLowLampData 4;
BA_ "SPN" SG_ 2566718974 EngCoolantLevelLowLampData 5101;
BA_ "SAEDocument" SG_ 2566718974 EngCoolantLevelLowLampData "J1939-71";
BA_ "SigType" SG_ 2566718974 EngCoolantTempHighLampData 4;
BA_ "SPN" SG_ 2566718974 EngCoolantTempHighLampData 5100;
BA_ "SAEDocument" SG_ 2566718974 EngCoolantTempHighLampData "J1939-71";
BA_ "SigType" SG_ 2566718974 EngOilPressLowLampData 4;
BA_ "SPN" SG_ 2566718974 EngOilPressLowLampData 5099;
BA_ "SAEDocument" SG_ 2566718974 EngOilPressLowLampData "J1939-71";
BA_ "SigType" SG_ 2566718974 CmprssnBrkEnblSwtchIndctrLmpData 4;
BA_ "SPN" SG_ 2566718974 CmprssnBrkEnblSwtchIndctrLmpData 5098;
BA_ "SAEDocument" SG_ 2566718974 CmprssnBrkEnblSwtchIndctrLmpData "J1939-71";
BA_ "SigType" SG_ 2566718974 EngBrakeActiveLampData 4;
BA_ "SPN" SG_ 2566718974 EngBrakeActiveLampData 5097;
BA_ "SAEDocument" SG_ 2566718974 EngBrakeActiveLampData "J1939-71";
BA_ "SigType" SG_ 2566718974 OBDMalfunctionIndicatorLampData 4;
BA_ "SPN" SG_ 2566718974 OBDMalfunctionIndicatorLampData 5096;
BA_ "SAEDocument" SG_ 2566718974 OBDMalfunctionIndicatorLampData "J1939-71";
BA_ "SigType" SG_ 2566718974 EngRedStopLampData 4;
BA_ "SPN" SG_ 2566718974 EngRedStopLampData 5095;
BA_ "SAEDocument" SG_ 2566718974 EngRedStopLampData "J1939-71";
BA_ "SigType" SG_ 2566718974 EngAmberWarningLampData 4;
BA_ "SPN" SG_ 2566718974 EngAmberWarningLampData 5094;
BA_ "SAEDocument" SG_ 2566718974 EngAmberWarningLampData "J1939-71";
BA_ "SigType" SG_ 2566718974 EngProtectLampData 4;
BA_ "SPN" SG_ 2566718974 EngProtectLampData 5093;
BA_ "SAEDocument" SG_ 2566718974 EngProtectLampData "J1939-71";
BA_ "SigType" SG_ 2566719230 VehicleBatteryChargingLampCmd 5;
BA_ "SPN" SG_ 2566719230 VehicleBatteryChargingLampCmd 5091;
BA_ "SAEDocument" SG_ 2566719230 VehicleBatteryChargingLampCmd "J1939-71";
BA_ "SigType" SG_ 2566719230 VehicleHVACRecirculationLampCmd 5;
BA_ "SPN" SG_ 2566719230 VehicleHVACRecirculationLampCmd 5090;
BA_ "SAEDocument" SG_ 2566719230 VehicleHVACRecirculationLampCmd "J1939-71";
BA_ "SigType" SG_ 2566719230 VehicleAirPressLowLampCmd 5;
BA_ "SPN" SG_ 2566719230 VehicleAirPressLowLampCmd 5089;
BA_ "SAEDocument" SG_ 2566719230 VehicleAirPressLowLampCmd "J1939-71";
BA_ "SigType" SG_ 2566719230 VehicleFuelLevelLowLampCmd 5;
BA_ "SPN" SG_ 2566719230 VehicleFuelLevelLowLampCmd 5088;
BA_ "SAEDocument" SG_ 2566719230 VehicleFuelLevelLowLampCmd "J1939-71";
BA_ "SigType" SG_ 2566719230 VehicleBatteryVoltageLowLampCmd 5;
BA_ "SPN" SG_ 2566719230 VehicleBatteryVoltageLowLampCmd 5087;
BA_ "SAEDocument" SG_ 2566719230 VehicleBatteryVoltageLowLampCmd "J1939-71";
BA_ "SigType" SG_ 2560818942 DTCTimeUntilDerate 1;
BA_ "SPN" SG_ 2560818942 DTCTimeUntilDerate 4123;
BA_ "SAEDocument" SG_ 2560818942 DTCTimeUntilDerate "J1939_73";
BA_ "SigType" SG_ 2560818942 DTCTotalPreviouslyActiveTime 1;
BA_ "SPN" SG_ 2560818942 DTCTotalPreviouslyActiveTime 4122;
BA_ "SAEDocument" SG_ 2560818942 DTCTotalPreviouslyActiveTime "J1939_73";
BA_ "SigType" SG_ 2560818942 DTCTotalActiveTime 1;
BA_ "SPN" SG_ 2560818942 DTCTotalActiveTime 4121;
BA_ "SAEDocument" SG_ 2560818942 DTCTotalActiveTime "J1939_73";
BA_ "SPN" SG_ 2560818942 FailureModeIdentifier1 1215;
BA_ "SAEDocument" SG_ 2560818942 FailureModeIdentifier1 "J1939-73";
BA_ "SAEDocument" SG_ 2560818942 SPN1High "J1939-73";
BA_ "SPN" SG_ 2560818942 SPN1 1214;
BA_ "SAEDocument" SG_ 2560818942 SPN1 "J1939-73";
BA_ "SPN" SG_ 2561212158 TextDisplayIndex 3614;
BA_ "SAEDocument" SG_ 2561212158 TextDisplayIndex "J1939-71";
BA_ "SPN" SG_ 2561212158 TextDisplayInstructions 3613;
BA_ "SAEDocument" SG_ 2561212158 TextDisplayInstructions "J1939-71";
BA_ "SigType" SG_ 2566746366 RetractStatusOfRamp5 5;
BA_ "SPN" SG_ 2566746366 RetractStatusOfRamp5 4457;
BA_ "SAEDocument" SG_ 2566746366 RetractStatusOfRamp5 "J1939-71";
BA_ "SigType" SG_ 2566746366 RetractStatusOfRamp4 5;
BA_ "SPN" SG_ 2566746366 RetractStatusOfRamp4 4454;
BA_ "SAEDocument" SG_ 2566746366 RetractStatusOfRamp4 "J1939-71";
BA_ "SigType" SG_ 2566746366 MovementStatusOfRamp5 5;
BA_ "SPN" SG_ 2566746366 MovementStatusOfRamp5 4459;
BA_ "SAEDocument" SG_ 2566746366 MovementStatusOfRamp5 "J1939-71";
BA_ "SigType" SG_ 2566746366 MovementStatusOfRamp4 5;
BA_ "SPN" SG_ 2566746366 MovementStatusOfRamp4 4456;
BA_ "SAEDocument" SG_ 2566746366 MovementStatusOfRamp4 "J1939-71";
BA_ "SigType" SG_ 2566746366 EnableStatusOfRamp5 5;
BA_ "SPN" SG_ 2566746366 EnableStatusOfRamp5 4458;
BA_ "SAEDocument" SG_ 2566746366 EnableStatusOfRamp5 "J1939-71";
BA_ "SigType" SG_ 2566746366 EnableStatusOfRamp4 5;
BA_ "SPN" SG_ 2566746366 EnableStatusOfRamp4 4455;
BA_ "SAEDocument" SG_ 2566746366 EnableStatusOfRamp4 "J1939-71";
BA_ "SigType" SG_ 2566746366 MovementStatusOfRamp3 5;
BA_ "SPN" SG_ 2566746366 MovementStatusOfRamp3 3818;
BA_ "SAEDocument" SG_ 2566746366 MovementStatusOfRamp3 "J1939-71";
BA_ "SigType" SG_ 2566746366 EnableStatusOfRamp3 5;
BA_ "SPN" SG_ 2566746366 EnableStatusOfRamp3 3817;
BA_ "SAEDocument" SG_ 2566746366 EnableStatusOfRamp3 "J1939-71";
BA_ "SigType" SG_ 2566746366 RetractStatusOfRamp3 5;
BA_ "SPN" SG_ 2566746366 RetractStatusOfRamp3 3816;
BA_ "SAEDocument" SG_ 2566746366 RetractStatusOfRamp3 "J1939-71";
BA_ "SigType" SG_ 2566746366 MovementStatusOfRamp2 5;
BA_ "SPN" SG_ 2566746366 MovementStatusOfRamp2 3815;
BA_ "SAEDocument" SG_ 2566746366 MovementStatusOfRamp2 "J1939-71";
BA_ "SigType" SG_ 2566746366 EnableStatusOfRamp2 5;
BA_ "SPN" SG_ 2566746366 EnableStatusOfRamp2 3814;
BA_ "SAEDocument" SG_ 2566746366 EnableStatusOfRamp2 "J1939-71";
BA_ "SigType" SG_ 2566746366 RetractStatusOfRamp2 5;
BA_ "SPN" SG_ 2566746366 RetractStatusOfRamp2 3813;
BA_ "SAEDocument" SG_ 2566746366 RetractStatusOfRamp2 "J1939-71";
BA_ "SigType" SG_ 2566746366 MovementStatusOfRamp1 5;
BA_ "SPN" SG_ 2566746366 MovementStatusOfRamp1 3812;
BA_ "SAEDocument" SG_ 2566746366 MovementStatusOfRamp1 "J1939-71";
BA_ "SigType" SG_ 2566746366 EnableStatusOfRamp1 5;
BA_ "SPN" SG_ 2566746366 EnableStatusOfRamp1 3811;
BA_ "SAEDocument" SG_ 2566746366 EnableStatusOfRamp1 "J1939-71";
BA_ "SigType" SG_ 2566746366 RetractStatusOfRamp1 5;
BA_ "SPN" SG_ 2566746366 RetractStatusOfRamp1 3810;
BA_ "SAEDocument" SG_ 2566746366 RetractStatusOfRamp1 "J1939-71";
BA_ "SPN" SG_ 2566750206 MaxCrankAttemptsPerStartAttempt 3670;
BA_ "SAEDocument" SG_ 2566750206 MaxCrankAttemptsPerStartAttempt "J1939-71";
BA_ "SigType" SG_ 2566755582 CommandedEngIntakeManifoldPress 1;
BA_ "SPN" SG_ 2566755582 CommandedEngIntakeManifoldPress 5312;
BA_ "SAEDocument" SG_ 2566755582 CommandedEngIntakeManifoldPress "J1939-71";
BA_ "SigType" SG_ 2566755582 EngCrnkcsBrtherOilSeparatorSpeed 1;
BA_ "SPN" SG_ 2566755582 EngCrnkcsBrtherOilSeparatorSpeed 5444;
BA_ "SAEDocument" SG_ 2566755582 EngCrnkcsBrtherOilSeparatorSpeed "J1939-71";
BA_ "SigType" SG_ 2566755582 EngExhstGsRcirculation1Valve2Pos 1;
BA_ "SPN" SG_ 2566755582 EngExhstGsRcirculation1Valve2Pos 3822;
BA_ "SAEDocument" SG_ 2566755582 EngExhstGsRcirculation1Valve2Pos "J1939-71";
BA_ "SigType" SG_ 2566755582 EngExhstGsRecirculation1ValvePos 1;
BA_ "SPN" SG_ 2566755582 EngExhstGsRecirculation1ValvePos 27;
BA_ "SAEDocument" SG_ 2566755582 EngExhstGsRecirculation1ValvePos "J1939-71";
BA_ "SigType" SG_ 2566746110 EngExhstGsRcrcltn1ClrIntkGsAbsPr 1;
BA_ "SPN" SG_ 2566746110 EngExhstGsRcrcltn1ClrIntkGsAbsPr 4751;
BA_ "SAEDocument" SG_ 2566746110 EngExhstGsRcrcltn1ClrIntkGsAbsPr "J1939-71";
BA_ "SigType" SG_ 2566746110 EngExhstGsRcrcltn1ClerIntakeTemp 1;
BA_ "SPN" SG_ 2566746110 EngExhstGsRcrcltn1ClerIntakeTemp 4750;
BA_ "SAEDocument" SG_ 2566746110 EngExhstGsRcrcltn1ClerIntakeTemp "J1939-71";
BA_ "SPN" SG_ 2566746110 EngExhstGsRcrcltn1ClerEfficiency 4752;
BA_ "SAEDocument" SG_ 2566746110 EngExhstGsRcrcltn1ClerEfficiency "J1939-71";
BA_ "SPN" SG_ 2566746110 EngExhstGsRcrculation1Valve2Ctrl 3821;
BA_ "SAEDocument" SG_ 2566746110 EngExhstGsRcrculation1Valve2Ctrl "J1939-71";
BA_ "SigType" SG_ 2566752510 EngIntkVlvActtionOilPressForCyl4 1;
BA_ "SPN" SG_ 2566752510 EngIntkVlvActtionOilPressForCyl4 3627;
BA_ "SAEDocument" SG_ 2566752510 EngIntkVlvActtionOilPressForCyl4 "J1939-71";
BA_ "SigType" SG_ 2566752510 EngIntkVlvActtionOilPressForCyl3 1;
BA_ "SPN" SG_ 2566752510 EngIntkVlvActtionOilPressForCyl3 3626;
BA_ "SAEDocument" SG_ 2566752510 EngIntkVlvActtionOilPressForCyl3 "J1939-71";
BA_ "SigType" SG_ 2566752510 EngIntkVlvActtionOilPressForCyl2 1;
BA_ "SPN" SG_ 2566752510 EngIntkVlvActtionOilPressForCyl2 3625;
BA_ "SAEDocument" SG_ 2566752510 EngIntkVlvActtionOilPressForCyl2 "J1939-71";
BA_ "SigType" SG_ 2566752510 EngIntkVlvActtionOilPressForCyl1 1;
BA_ "SPN" SG_ 2566752510 EngIntkVlvActtionOilPressForCyl1 3624;
BA_ "SAEDocument" SG_ 2566752510 EngIntkVlvActtionOilPressForCyl1 "J1939-71";
BA_ "SigType" SG_ 2566752254 EngIntkVlvActtionOilPressForCyl8 1;
BA_ "SPN" SG_ 2566752254 EngIntkVlvActtionOilPressForCyl8 3631;
BA_ "SAEDocument" SG_ 2566752254 EngIntkVlvActtionOilPressForCyl8 "J1939-71";
BA_ "SigType" SG_ 2566752254 EngIntkVlvActtionOilPressForCyl7 1;
BA_ "SPN" SG_ 2566752254 EngIntkVlvActtionOilPressForCyl7 3630;
BA_ "SAEDocument" SG_ 2566752254 EngIntkVlvActtionOilPressForCyl7 "J1939-71";
BA_ "SigType" SG_ 2566752254 EngIntkVlvActtionOilPressForCyl6 1;
BA_ "SPN" SG_ 2566752254 EngIntkVlvActtionOilPressForCyl6 3629;
BA_ "SAEDocument" SG_ 2566752254 EngIntkVlvActtionOilPressForCyl6 "J1939-71";
BA_ "SigType" SG_ 2566752254 EngIntkVlvActtionOilPressForCyl5 1;
BA_ "SPN" SG_ 2566752254 EngIntkVlvActtionOilPressForCyl5 3628;
BA_ "SAEDocument" SG_ 2566752254 EngIntkVlvActtionOilPressForCyl5 "J1939-71";
BA_ "SigType" SG_ 2566751998 EngIntkVlvActtonOilPressForCyl12 1;
BA_ "SPN" SG_ 2566751998 EngIntkVlvActtonOilPressForCyl12 3635;
BA_ "SAEDocument" SG_ 2566751998 EngIntkVlvActtonOilPressForCyl12 "J1939-71";
BA_ "SigType" SG_ 2566751998 EngIntkVlvActtonOilPressForCyl11 1;
BA_ "SPN" SG_ 2566751998 EngIntkVlvActtonOilPressForCyl11 3634;
BA_ "SAEDocument" SG_ 2566751998 EngIntkVlvActtonOilPressForCyl11 "J1939-71";
BA_ "SigType" SG_ 2566751998 EngIntkVlvActtonOilPressForCyl10 1;
BA_ "SPN" SG_ 2566751998 EngIntkVlvActtonOilPressForCyl10 3633;
BA_ "SAEDocument" SG_ 2566751998 EngIntkVlvActtonOilPressForCyl10 "J1939-71";
BA_ "SigType" SG_ 2566751998 EngIntkVlvActtionOilPressForCyl9 1;
BA_ "SPN" SG_ 2566751998 EngIntkVlvActtionOilPressForCyl9 3632;
BA_ "SAEDocument" SG_ 2566751998 EngIntkVlvActtionOilPressForCyl9 "J1939-71";
BA_ "SigType" SG_ 2566751742 EngIntkVlvActtonOilPressForCyl16 1;
BA_ "SPN" SG_ 2566751742 EngIntkVlvActtonOilPressForCyl16 3639;
BA_ "SAEDocument" SG_ 2566751742 EngIntkVlvActtonOilPressForCyl16 "J1939-71";
BA_ "SigType" SG_ 2566751742 EngIntkVlvActtonOilPressForCyl15 1;
BA_ "SPN" SG_ 2566751742 EngIntkVlvActtonOilPressForCyl15 3638;
BA_ "SAEDocument" SG_ 2566751742 EngIntkVlvActtonOilPressForCyl15 "J1939-71";
BA_ "SigType" SG_ 2566751742 EngIntkVlvActtonOilPressForCyl14 1;
BA_ "SPN" SG_ 2566751742 EngIntkVlvActtonOilPressForCyl14 3637;
BA_ "SAEDocument" SG_ 2566751742 EngIntkVlvActtonOilPressForCyl14 "J1939-71";
BA_ "SigType" SG_ 2566751742 EngIntkVlvActtonOilPressForCyl13 1;
BA_ "SPN" SG_ 2566751742 EngIntkVlvActtonOilPressForCyl13 3636;
BA_ "SAEDocument" SG_ 2566751742 EngIntkVlvActtonOilPressForCyl13 "J1939-71";
BA_ "SigType" SG_ 2566751486 EngIntkVlvActtonOilPressForCyl20 1;
BA_ "SPN" SG_ 2566751486 EngIntkVlvActtonOilPressForCyl20 3643;
BA_ "SAEDocument" SG_ 2566751486 EngIntkVlvActtonOilPressForCyl20 "J1939-71";
BA_ "SigType" SG_ 2566751486 EngIntkVlvActtonOilPressForCyl19 1;
BA_ "SPN" SG_ 2566751486 EngIntkVlvActtonOilPressForCyl19 3642;
BA_ "SAEDocument" SG_ 2566751486 EngIntkVlvActtonOilPressForCyl19 "J1939-71";
BA_ "SigType" SG_ 2566751486 EngIntkVlvActtonOilPressForCyl18 1;
BA_ "SPN" SG_ 2566751486 EngIntkVlvActtonOilPressForCyl18 3641;
BA_ "SAEDocument" SG_ 2566751486 EngIntkVlvActtonOilPressForCyl18 "J1939-71";
BA_ "SigType" SG_ 2566751486 EngIntkVlvActtonOilPressForCyl17 1;
BA_ "SPN" SG_ 2566751486 EngIntkVlvActtonOilPressForCyl17 3640;
BA_ "SAEDocument" SG_ 2566751486 EngIntkVlvActtonOilPressForCyl17 "J1939-71";
BA_ "SigType" SG_ 2499641854 EGR1CoolerBypassActuatorPostion 1;
BA_ "SPN" SG_ 2499641854 EGR1CoolerBypassActuatorPostion 3672;
BA_ "SAEDocument" SG_ 2499641854 EGR1CoolerBypassActuatorPostion "J1939-71";
BA_ "SigType" SG_ 2566748158 EngSparkPlug4 1;
BA_ "SPN" SG_ 2566748158 EngSparkPlug4 1297;
BA_ "SAEDocument" SG_ 2566748158 EngSparkPlug4 "J1939-71";
BA_ "SigType" SG_ 2566748158 EngSparkPlug3 1;
BA_ "SPN" SG_ 2566748158 EngSparkPlug3 1296;
BA_ "SAEDocument" SG_ 2566748158 EngSparkPlug3 "J1939-71";
BA_ "SigType" SG_ 2566748158 EngSparkPlug2 1;
BA_ "SPN" SG_ 2566748158 EngSparkPlug2 1295;
BA_ "SAEDocument" SG_ 2566748158 EngSparkPlug2 "J1939-71";
BA_ "SigType" SG_ 2566748158 EngSparkPlug1 1;
BA_ "SPN" SG_ 2566748158 EngSparkPlug1 1294;
BA_ "SAEDocument" SG_ 2566748158 EngSparkPlug1 "J1939-71";
BA_ "SigType" SG_ 2566747902 EngSparkPlug8 1;
BA_ "SPN" SG_ 2566747902 EngSparkPlug8 1301;
BA_ "SAEDocument" SG_ 2566747902 EngSparkPlug8 "J1939-71";
BA_ "SigType" SG_ 2566747902 EngSparkPlug7 1;
BA_ "SPN" SG_ 2566747902 EngSparkPlug7 1300;
BA_ "SAEDocument" SG_ 2566747902 EngSparkPlug7 "J1939-71";
BA_ "SigType" SG_ 2566747902 EngSparkPlug6 1;
BA_ "SPN" SG_ 2566747902 EngSparkPlug6 1299;
BA_ "SAEDocument" SG_ 2566747902 EngSparkPlug6 "J1939-71";
BA_ "SigType" SG_ 2566747902 EngSparkPlug5 1;
BA_ "SPN" SG_ 2566747902 EngSparkPlug5 1298;
BA_ "SAEDocument" SG_ 2566747902 EngSparkPlug5 "J1939-71";
BA_ "SigType" SG_ 2566747646 EngSparkPlug12 1;
BA_ "SPN" SG_ 2566747646 EngSparkPlug12 1305;
BA_ "SAEDocument" SG_ 2566747646 EngSparkPlug12 "J1939-71";
BA_ "SigType" SG_ 2566747646 EngSparkPlug11 1;
BA_ "SPN" SG_ 2566747646 EngSparkPlug11 1304;
BA_ "SAEDocument" SG_ 2566747646 EngSparkPlug11 "J1939-71";
BA_ "SigType" SG_ 2566747646 EngSparkPlug10 1;
BA_ "SPN" SG_ 2566747646 EngSparkPlug10 1303;
BA_ "SAEDocument" SG_ 2566747646 EngSparkPlug10 "J1939-71";
BA_ "SigType" SG_ 2566747646 EngSparkPlug9 1;
BA_ "SPN" SG_ 2566747646 EngSparkPlug9 1302;
BA_ "SAEDocument" SG_ 2566747646 EngSparkPlug9 "J1939-71";
BA_ "SigType" SG_ 2566747390 EngSparkPlug16 1;
BA_ "SPN" SG_ 2566747390 EngSparkPlug16 1309;
BA_ "SAEDocument" SG_ 2566747390 EngSparkPlug16 "J1939-71";
BA_ "SigType" SG_ 2566747390 EngSparkPlug15 1;
BA_ "SPN" SG_ 2566747390 EngSparkPlug15 1308;
BA_ "SAEDocument" SG_ 2566747390 EngSparkPlug15 "J1939-71";
BA_ "SigType" SG_ 2566747390 EngSparkPlug14 1;
BA_ "SPN" SG_ 2566747390 EngSparkPlug14 1307;
BA_ "SAEDocument" SG_ 2566747390 EngSparkPlug14 "J1939-71";
BA_ "SigType" SG_ 2566747390 EngSparkPlug13 1;
BA_ "SPN" SG_ 2566747390 EngSparkPlug13 1306;
BA_ "SAEDocument" SG_ 2566747390 EngSparkPlug13 "J1939-71";
BA_ "SigType" SG_ 2566747134 EngSparkPlug20 1;
BA_ "SPN" SG_ 2566747134 EngSparkPlug20 1313;
BA_ "SAEDocument" SG_ 2566747134 EngSparkPlug20 "J1939-71";
BA_ "SigType" SG_ 2566747134 EngSparkPlug19 1;
BA_ "SPN" SG_ 2566747134 EngSparkPlug19 1312;
BA_ "SAEDocument" SG_ 2566747134 EngSparkPlug19 "J1939-71";
BA_ "SigType" SG_ 2566747134 EngSparkPlug18 1;
BA_ "SPN" SG_ 2566747134 EngSparkPlug18 1311;
BA_ "SAEDocument" SG_ 2566747134 EngSparkPlug18 "J1939-71";
BA_ "SigType" SG_ 2566747134 EngSparkPlug17 1;
BA_ "SPN" SG_ 2566747134 EngSparkPlug17 1310;
BA_ "SAEDocument" SG_ 2566747134 EngSparkPlug17 "J1939-71";
BA_ "SigType" SG_ 2566746878 EngSparkPlug24 1;
BA_ "SPN" SG_ 2566746878 EngSparkPlug24 1317;
BA_ "SAEDocument" SG_ 2566746878 EngSparkPlug24 "J1939-71";
BA_ "SigType" SG_ 2566746878 EngSparkPlug23 1;
BA_ "SPN" SG_ 2566746878 EngSparkPlug23 1316;
BA_ "SAEDocument" SG_ 2566746878 EngSparkPlug23 "J1939-71";
BA_ "SigType" SG_ 2566746878 EngSparkPlug22 1;
BA_ "SPN" SG_ 2566746878 EngSparkPlug22 1315;
BA_ "SAEDocument" SG_ 2566746878 EngSparkPlug22 "J1939-71";
BA_ "SigType" SG_ 2566746878 EngSparkPlug21 1;
BA_ "SPN" SG_ 2566746878 EngSparkPlug21 1314;
BA_ "SAEDocument" SG_ 2566746878 EngSparkPlug21 "J1939-71";
BA_ "SigType" SG_ 2561277694 LaneDepartureWarningEnableCmd 5;
BA_ "SPN" SG_ 2561277694 LaneDepartureWarningEnableCmd 3564;
BA_ "SAEDocument" SG_ 2561277694 LaneDepartureWarningEnableCmd "J1939-71";
BA_ "SPN" SG_ 2633861886 J2012DTCOccurrenceCount 3622;
BA_ "SAEDocument" SG_ 2633861886 J2012DTCOccurrenceCount "J1939-71";
BA_ "SPN" SG_ 2633861886 J2012DTCStatus 3621;
BA_ "SAEDocument" SG_ 2633861886 J2012DTCStatus "J1939-71";
BA_ "SPN" SG_ 2633861886 J2012DTC 3620;
BA_ "SAEDocument" SG_ 2633861886 J2012DTC "J1939-71";
BA_ "SigType" SG_ 2633861886 NumberOfJ2012DTCs 1;
BA_ "SPN" SG_ 2633861886 NumberOfJ2012DTCs 3619;
BA_ "SAEDocument" SG_ 2633861886 NumberOfJ2012DTCs "J1939-71";
BA_ "SPN" SG_ 2565873150 MessageChecksum 3690;
BA_ "SAEDocument" SG_ 2565873150 MessageChecksum "J1939-71";
BA_ "SPN" SG_ 2565873150 MessageCounter 3689;
BA_ "SAEDocument" SG_ 2565873150 MessageCounter "J1939-71";
BA_ "SigType" SG_ 2565873150 SteerAngleSensorCalibrated 5;
BA_ "SPN" SG_ 2565873150 SteerAngleSensorCalibrated 3688;
BA_ "SAEDocument" SG_ 2565873150 SteerAngleSensorCalibrated "J1939-71";
BA_ "SigType" SG_ 2565873150 SteerAngleSensorActiveMode 5;
BA_ "SPN" SG_ 2565873150 SteerAngleSensorActiveMode 3687;
BA_ "SAEDocument" SG_ 2565873150 SteerAngleSensorActiveMode "J1939-71";
BA_ "SigType" SG_ 2565873150 SteerWheelAngleRange 1;
BA_ "SPN" SG_ 2565873150 SteerWheelAngleRange 3686;
BA_ "SAEDocument" SG_ 2565873150 SteerWheelAngleRange "J1939-71";
BA_ "SigType" SG_ 2565873150 SteerWheelAngleRangeCounterType 5;
BA_ "SPN" SG_ 2565873150 SteerWheelAngleRangeCounterType 3685;
BA_ "SAEDocument" SG_ 2565873150 SteerWheelAngleRangeCounterType "J1939-71";
BA_ "SPN" SG_ 2565873150 SteerWheelAngleRangeCounter 3684;
BA_ "SAEDocument" SG_ 2565873150 SteerWheelAngleRangeCounter "J1939-71";
BA_ "SigType" SG_ 2565873150 SteerWheelAngle 1;
BA_ "SPN" SG_ 2565873150 SteerWheelAngle 3683;
BA_ "SAEDocument" SG_ 2565873150 SteerWheelAngle "J1939-71";
BA_ "SigType" SG_ 2566745854 Aftrtrtmnt1SCRCtlystCnvrsnEffcnc 1;
BA_ "SPN" SG_ 2566745854 Aftrtrtmnt1SCRCtlystCnvrsnEffcnc 4364;
BA_ "SAEDocument" SG_ 2566745854 Aftrtrtmnt1SCRCtlystCnvrsnEffcnc "J1939-71";
BA_ "SPN" SG_ 2566745854 Aftrtrtmnt1SCRCmmnddCtlystRgntCn 3828;
BA_ "SAEDocument" SG_ 2566745854 Aftrtrtmnt1SCRCmmnddCtlystRgntCn "J1939-71";
BA_ "SigType" SG_ 2566745854 Aftrtrtmnt1SCRAvrgCtlystRgntCnsm 1;
BA_ "SPN" SG_ 2566745854 Aftrtrtmnt1SCRAvrgCtlystRgntCnsm 3826;
BA_ "SAEDocument" SG_ 2566745854 Aftrtrtmnt1SCRAvrgCtlystRgntCnsm "J1939-71";
BA_ "SigType" SG_ 2566745854 Aftrtrtmnt1DslExhstFldTnkLwLvlIn 1;
BA_ "SPN" SG_ 2566745854 Aftrtrtmnt1DslExhstFldTnkLwLvlIn 5463;
BA_ "SAEDocument" SG_ 2566745854 Aftrtrtmnt1DslExhstFldTnkLwLvlIn "J1939-71";
BA_ "SPN" SG_ 2566751230 TransferCaseStatus 3645;
BA_ "SAEDocument" SG_ 2566751230 TransferCaseStatus "J1939-71";
BA_ "SigType" SG_ 2566755838 TransOilLifeRemaining 1;
BA_ "SPN" SG_ 2566755838 TransOilLifeRemaining 4177;
BA_ "SAEDocument" SG_ 2566755838 TransOilLifeRemaining "J1939-71";
BA_ "SigType" SG_ 2566755838 TrnsTorqueConverterOilOutletTemp 1;
BA_ "SPN" SG_ 2566755838 TrnsTorqueConverterOilOutletTemp 3823;
BA_ "SAEDocument" SG_ 2566755838 TrnsTorqueConverterOilOutletTemp "J1939-71";
BA_ "SigType" SG_ 2566755838 TransOverheatIndicator 5;
BA_ "SPN" SG_ 2566755838 TransOverheatIndicator 5345;
BA_ "SAEDocument" SG_ 2566755838 TransOverheatIndicator "J1939-71";
BA_ "SigType" SG_ 2566755838 TransOilLevelSwitch 5;
BA_ "SPN" SG_ 2566755838 TransOilLevelSwitch 3533;
BA_ "SAEDocument" SG_ 2566755838 TransOilLevelSwitch "J1939-71";
BA_ "SigType" SG_ 2566755838 TransOilFilterRestrictionSwitch 5;
BA_ "SPN" SG_ 2566755838 TransOilFilterRestrictionSwitch 3359;
BA_ "SAEDocument" SG_ 2566755838 TransOilFilterRestrictionSwitch "J1939-71";
BA_ "SigType" SG_ 2566752766 VehicleRoll 1;
BA_ "SPN" SG_ 2566752766 VehicleRoll 3623;
BA_ "SAEDocument" SG_ 2566752766 VehicleRoll "J1939-71";
BA_ "SigType" SG_ 2633938942 TotalEngCruiseTime 1;
BA_ "SPN" SG_ 2633938942 TotalEngCruiseTime 1017;
BA_ "SAEDocument" SG_ 2633938942 TotalEngCruiseTime "J1939-71";
BA_ "SigType" SG_ 2633938942 TotalDriveAverageLoadFactor 1;
BA_ "SPN" SG_ 2633938942 TotalDriveAverageLoadFactor 1016;
BA_ "SAEDocument" SG_ 2633938942 TotalDriveAverageLoadFactor "J1939-71";
BA_ "SigType" SG_ 2633938942 TripDriveAverageLoadFactor 1;
BA_ "SPN" SG_ 2633938942 TripDriveAverageLoadFactor 1015;
BA_ "SAEDocument" SG_ 2633938942 TripDriveAverageLoadFactor "J1939-71";
BA_ "SigType" SG_ 2633938942 TripAverageEngSpeed 1;
BA_ "SPN" SG_ 2633938942 TripAverageEngSpeed 1014;
BA_ "SAEDocument" SG_ 2633938942 TripAverageEngSpeed "J1939-71";
BA_ "SigType" SG_ 2633938942 TripMaxEngSpeed 1;
BA_ "SPN" SG_ 2633938942 TripMaxEngSpeed 1013;
BA_ "SAEDocument" SG_ 2633938942 TripMaxEngSpeed "J1939-71";
BA_ "SigType" SG_ 2566799614 ImplementRearWorkLight 4;
BA_ "SPN" SG_ 2566799614 ImplementRearWorkLight 2394;
BA_ "SAEDocument" SG_ 2566799614 ImplementRearWorkLight "J1939-71";
BA_ "SigType" SG_ 2566799614 ImplementLeftForwardWorkLight 4;
BA_ "SPN" SG_ 2566799614 ImplementLeftForwardWorkLight 2400;
BA_ "SAEDocument" SG_ 2566799614 ImplementLeftForwardWorkLight "J1939-71";
BA_ "SigType" SG_ 2566799614 ImplementRightForwardWorkLight 4;
BA_ "SPN" SG_ 2566799614 ImplementRightForwardWorkLight 2402;
BA_ "SAEDocument" SG_ 2566799614 ImplementRightForwardWorkLight "J1939-71";
BA_ "SigType" SG_ 2566799614 ImplementLeftFacingWorkLight 4;
BA_ "SPN" SG_ 2566799614 ImplementLeftFacingWorkLight 2598;
BA_ "SAEDocument" SG_ 2566799614 ImplementLeftFacingWorkLight "J1939-71";
BA_ "SigType" SG_ 2566799614 ImplementRightFacingWorkLight 4;
BA_ "SPN" SG_ 2566799614 ImplementRightFacingWorkLight 2407;
BA_ "SAEDocument" SG_ 2566799614 ImplementRightFacingWorkLight "J1939-71";
BA_ "SigType" SG_ 2566799614 ImplementOEMOption1Light 4;
BA_ "SPN" SG_ 2566799614 ImplementOEMOption1Light 2396;
BA_ "SAEDocument" SG_ 2566799614 ImplementOEMOption1Light "J1939-71";
BA_ "SigType" SG_ 2566799614 ImplementOEMOption2Light 4;
BA_ "SPN" SG_ 2566799614 ImplementOEMOption2Light 2398;
BA_ "SAEDocument" SG_ 2566799614 ImplementOEMOption2Light "J1939-71";
BA_ "SigType" SG_ 2566799614 TrctorFrontHighMountedWorkLights 4;
BA_ "SPN" SG_ 2566799614 TrctorFrontHighMountedWorkLights 2356;
BA_ "SAEDocument" SG_ 2566799614 TrctorFrontHighMountedWorkLights "J1939-71";
BA_ "SigType" SG_ 2566799614 TractorFrontLowMountedWorkLights 4;
BA_ "SPN" SG_ 2566799614 TractorFrontLowMountedWorkLights 2354;
BA_ "SAEDocument" SG_ 2566799614 TractorFrontLowMountedWorkLights "J1939-71";
BA_ "SigType" SG_ 2566799614 TractorSideHighMountedWorkLights 4;
BA_ "SPN" SG_ 2566799614 TractorSideHighMountedWorkLights 2366;
BA_ "SAEDocument" SG_ 2566799614 TractorSideHighMountedWorkLights "J1939-71";
BA_ "SigType" SG_ 2566799614 TractorSideLowMountedWorkLights 4;
BA_ "SPN" SG_ 2566799614 TractorSideLowMountedWorkLights 2364;
BA_ "SAEDocument" SG_ 2566799614 TractorSideLowMountedWorkLights "J1939-71";
BA_ "SigType" SG_ 2566799614 TractorRearHighMountedWorkLights 4;
BA_ "SPN" SG_ 2566799614 TractorRearHighMountedWorkLights 2362;
BA_ "SAEDocument" SG_ 2566799614 TractorRearHighMountedWorkLights "J1939-71";
BA_ "SigType" SG_ 2566799614 TractorRearLowMountedWorkLights 4;
BA_ "SPN" SG_ 2566799614 TractorRearLowMountedWorkLights 2360;
BA_ "SAEDocument" SG_ 2566799614 TractorRearLowMountedWorkLights "J1939-71";
BA_ "SigType" SG_ 2566799614 TrctorUndersideMountedWorkLights 4;
BA_ "SPN" SG_ 2566799614 TrctorUndersideMountedWorkLights 2358;
BA_ "SAEDocument" SG_ 2566799614 TrctorUndersideMountedWorkLights "J1939-71";
BA_ "SigType" SG_ 2566799614 RearFogLights 4;
BA_ "SPN" SG_ 2566799614 RearFogLights 2390;
BA_ "SAEDocument" SG_ 2566799614 RearFogLights "J1939-71";
BA_ "SigType" SG_ 2566799614 TractorMarkerLight 4;
BA_ "SPN" SG_ 2566799614 TractorMarkerLight 2378;
BA_ "SAEDocument" SG_ 2566799614 TractorMarkerLight "J1939-71";
BA_ "SigType" SG_ 2566799614 ImplementMarkerLight 4;
BA_ "SPN" SG_ 2566799614 ImplementMarkerLight 2380;
BA_ "SAEDocument" SG_ 2566799614 ImplementMarkerLight "J1939-71";
BA_ "SigType" SG_ 2566799614 TractorClearanceLight 4;
BA_ "SPN" SG_ 2566799614 TractorClearanceLight 2382;
BA_ "SAEDocument" SG_ 2566799614 TractorClearanceLight "J1939-71";
BA_ "SigType" SG_ 2566799614 ImplementClearanceLight 4;
BA_ "SPN" SG_ 2566799614 ImplementClearanceLight 2384;
BA_ "SAEDocument" SG_ 2566799614 ImplementClearanceLight "J1939-71";
BA_ "SigType" SG_ 2566799614 LeftStopLight 4;
BA_ "SPN" SG_ 2566799614 LeftStopLight 2372;
BA_ "SAEDocument" SG_ 2566799614 LeftStopLight "J1939-71";
BA_ "SigType" SG_ 2566799614 RightStopLight 4;
BA_ "SPN" SG_ 2566799614 RightStopLight 2374;
BA_ "SAEDocument" SG_ 2566799614 RightStopLight "J1939-71";
BA_ "SigType" SG_ 2566799614 CenterStopLight 4;
BA_ "SPN" SG_ 2566799614 CenterStopLight 2376;
BA_ "SAEDocument" SG_ 2566799614 CenterStopLight "J1939-71";
BA_ "SigType" SG_ 2566799614 BackUpLightAndAlarmHorn 4;
BA_ "SPN" SG_ 2566799614 BackUpLightAndAlarmHorn 2392;
BA_ "SAEDocument" SG_ 2566799614 BackUpLightAndAlarmHorn "J1939-71";
BA_ "SigType" SG_ 2566799614 LeftTurnSignalLights 4;
BA_ "SPN" SG_ 2566799614 LeftTurnSignalLights 2368;
BA_ "SAEDocument" SG_ 2566799614 LeftTurnSignalLights "J1939-71";
BA_ "SigType" SG_ 2566799614 RightTurnSignalLights 4;
BA_ "SPN" SG_ 2566799614 RightTurnSignalLights 2370;
BA_ "SAEDocument" SG_ 2566799614 RightTurnSignalLights "J1939-71";
BA_ "SigType" SG_ 2566799614 RotatingBeaconLight 4;
BA_ "SPN" SG_ 2566799614 RotatingBeaconLight 2386;
BA_ "SAEDocument" SG_ 2566799614 RotatingBeaconLight "J1939-71";
BA_ "SigType" SG_ 2566799614 TractorFrontFogLights 4;
BA_ "SPN" SG_ 2566799614 TractorFrontFogLights 2388;
BA_ "SAEDocument" SG_ 2566799614 TractorFrontFogLights "J1939-71";
BA_ "SigType" SG_ 2566799614 HighBeamHeadLightData 4;
BA_ "SPN" SG_ 2566799614 HighBeamHeadLightData 2348;
BA_ "SAEDocument" SG_ 2566799614 HighBeamHeadLightData "J1939-71";
BA_ "SigType" SG_ 2566799614 LowBeamHeadLightData 4;
BA_ "SPN" SG_ 2566799614 LowBeamHeadLightData 2350;
BA_ "SAEDocument" SG_ 2566799614 LowBeamHeadLightData "J1939-71";
BA_ "SigType" SG_ 2566799614 AltBeamHeadLightData 4;
BA_ "SPN" SG_ 2566799614 AltBeamHeadLightData 2352;
BA_ "SAEDocument" SG_ 2566799614 AltBeamHeadLightData "J1939-71";
BA_ "SigType" SG_ 2566799614 RunningLight 4;
BA_ "SPN" SG_ 2566799614 RunningLight 2404;
BA_ "SAEDocument" SG_ 2566799614 RunningLight "J1939-71";
BA_ "SigType" SG_ 2365473278 ImplementRearWorkLightCmd 5;
BA_ "SPN" SG_ 2365473278 ImplementRearWorkLightCmd 2405;
BA_ "SAEDocument" SG_ 2365473278 ImplementRearWorkLightCmd "J1939-71";
BA_ "SigType" SG_ 2365473278 ImplementLeftForwardWorkLightCmd 5;
BA_ "SPN" SG_ 2365473278 ImplementLeftForwardWorkLightCmd 2399;
BA_ "SAEDocument" SG_ 2365473278 ImplementLeftForwardWorkLightCmd "J1939-71";
BA_ "SigType" SG_ 2365473278 ImplmentRightForwardWorkLightCmd 5;
BA_ "SPN" SG_ 2365473278 ImplmentRightForwardWorkLightCmd 2401;
BA_ "SAEDocument" SG_ 2365473278 ImplmentRightForwardWorkLightCmd "J1939-71";
BA_ "SigType" SG_ 2365473278 LightingDataRqCmd 5;
BA_ "SPN" SG_ 2365473278 LightingDataRqCmd 2393;
BA_ "SAEDocument" SG_ 2365473278 LightingDataRqCmd "J1939-71";
BA_ "SigType" SG_ 2365473278 ImplementLeftFacingWorkLightCmd 5;
BA_ "SPN" SG_ 2365473278 ImplementLeftFacingWorkLightCmd 2597;
BA_ "SAEDocument" SG_ 2365473278 ImplementLeftFacingWorkLightCmd "J1939-71";
BA_ "SigType" SG_ 2365473278 ImplementRightFacingWorkLightCmd 5;
BA_ "SPN" SG_ 2365473278 ImplementRightFacingWorkLightCmd 2406;
BA_ "SAEDocument" SG_ 2365473278 ImplementRightFacingWorkLightCmd "J1939-71";
BA_ "SigType" SG_ 2365473278 ImplementOEMOption1LightCmd 5;
BA_ "SPN" SG_ 2365473278 ImplementOEMOption1LightCmd 2395;
BA_ "SAEDocument" SG_ 2365473278 ImplementOEMOption1LightCmd "J1939-71";
BA_ "SigType" SG_ 2365473278 ImplementOEMOption2LightCmd 5;
BA_ "SPN" SG_ 2365473278 ImplementOEMOption2LightCmd 2397;
BA_ "SAEDocument" SG_ 2365473278 ImplementOEMOption2LightCmd "J1939-71";
BA_ "SigType" SG_ 2365473278 TrctrFrntHghMountedWorkLightsCmd 5;
BA_ "SPN" SG_ 2365473278 TrctrFrntHghMountedWorkLightsCmd 2355;
BA_ "SAEDocument" SG_ 2365473278 TrctrFrntHghMountedWorkLightsCmd "J1939-71";
BA_ "SigType" SG_ 2365473278 TrctrFrntLowMountedWorkLightsCmd 5;
BA_ "SPN" SG_ 2365473278 TrctrFrntLowMountedWorkLightsCmd 2353;
BA_ "SAEDocument" SG_ 2365473278 TrctrFrntLowMountedWorkLightsCmd "J1939-71";
BA_ "SigType" SG_ 2365473278 TrctrSdeHighMountedWorkLightsCmd 5;
BA_ "SPN" SG_ 2365473278 TrctrSdeHighMountedWorkLightsCmd 2365;
BA_ "SAEDocument" SG_ 2365473278 TrctrSdeHighMountedWorkLightsCmd "J1939-71";
BA_ "SigType" SG_ 2365473278 TrctrSideLowMountedWorkLightsCmd 5;
BA_ "SPN" SG_ 2365473278 TrctrSideLowMountedWorkLightsCmd 2363;
BA_ "SAEDocument" SG_ 2365473278 TrctrSideLowMountedWorkLightsCmd "J1939-71";
BA_ "SigType" SG_ 2365473278 TrctrRarHighMountedWorkLightsCmd 5;
BA_ "SPN" SG_ 2365473278 TrctrRarHighMountedWorkLightsCmd 2361;
BA_ "SAEDocument" SG_ 2365473278 TrctrRarHighMountedWorkLightsCmd "J1939-71";
BA_ "SigType" SG_ 2365473278 TrctrRearLowMountedWorkLightsCmd 5;
BA_ "SPN" SG_ 2365473278 TrctrRearLowMountedWorkLightsCmd 2359;
BA_ "SAEDocument" SG_ 2365473278 TrctrRearLowMountedWorkLightsCmd "J1939-71";
BA_ "SigType" SG_ 2365473278 TrctrUndrsdeMountedWorkLightsCmd 5;
BA_ "SPN" SG_ 2365473278 TrctrUndrsdeMountedWorkLightsCmd 2357;
BA_ "SAEDocument" SG_ 2365473278 TrctrUndrsdeMountedWorkLightsCmd "J1939-71";
BA_ "SigType" SG_ 2365473278 RearFogLightCmd 5;
BA_ "SPN" SG_ 2365473278 RearFogLightCmd 2389;
BA_ "SAEDocument" SG_ 2365473278 RearFogLightCmd "J1939-71";
BA_ "SigType" SG_ 2365473278 TractorMarkerLightCmd 5;
BA_ "SPN" SG_ 2365473278 TractorMarkerLightCmd 2377;
BA_ "SAEDocument" SG_ 2365473278 TractorMarkerLightCmd "J1939-71";
BA_ "SigType" SG_ 2365473278 ImplementMarkerLightCmd 5;
BA_ "SPN" SG_ 2365473278 ImplementMarkerLightCmd 2379;
BA_ "SAEDocument" SG_ 2365473278 ImplementMarkerLightCmd "J1939-71";
BA_ "SigType" SG_ 2365473278 TractorClearanceLightCmd 5;
BA_ "SPN" SG_ 2365473278 TractorClearanceLightCmd 2381;
BA_ "SAEDocument" SG_ 2365473278 TractorClearanceLightCmd "J1939-71";
BA_ "SigType" SG_ 2365473278 ImplementClearanceLightCmd 5;
BA_ "SPN" SG_ 2365473278 ImplementClearanceLightCmd 2383;
BA_ "SAEDocument" SG_ 2365473278 ImplementClearanceLightCmd "J1939-71";
BA_ "SigType" SG_ 2365473278 LeftStopLightCmd 5;
BA_ "SPN" SG_ 2365473278 LeftStopLightCmd 2371;
BA_ "SAEDocument" SG_ 2365473278 LeftStopLightCmd "J1939-71";
BA_ "SigType" SG_ 2365473278 RightStopLightCmd 5;
BA_ "SPN" SG_ 2365473278 RightStopLightCmd 2373;
BA_ "SAEDocument" SG_ 2365473278 RightStopLightCmd "J1939-71";
BA_ "SigType" SG_ 2365473278 CenterStopLightCmd 5;
BA_ "SPN" SG_ 2365473278 CenterStopLightCmd 2375;
BA_ "SAEDocument" SG_ 2365473278 CenterStopLightCmd "J1939-71";
BA_ "SigType" SG_ 2365473278 BackUpLightAndAlarmHornCmd 5;
BA_ "SPN" SG_ 2365473278 BackUpLightAndAlarmHornCmd 2391;
BA_ "SAEDocument" SG_ 2365473278 BackUpLightAndAlarmHornCmd "J1939-71";
BA_ "SigType" SG_ 2365473278 LeftTurnSignalLightsCmd 5;
BA_ "SPN" SG_ 2365473278 LeftTurnSignalLightsCmd 2367;
BA_ "SAEDocument" SG_ 2365473278 LeftTurnSignalLightsCmd "J1939-71";
BA_ "SigType" SG_ 2365473278 RightTurnSignalLightsCmd 5;
BA_ "SPN" SG_ 2365473278 RightTurnSignalLightsCmd 2369;
BA_ "SAEDocument" SG_ 2365473278 RightTurnSignalLightsCmd "J1939-71";
BA_ "SigType" SG_ 2365473278 RotatingBeaconLightCmd 5;
BA_ "SPN" SG_ 2365473278 RotatingBeaconLightCmd 2385;
BA_ "SAEDocument" SG_ 2365473278 RotatingBeaconLightCmd "J1939-71";
BA_ "SigType" SG_ 2365473278 TractorFrontFogLightsCmd 5;
BA_ "SPN" SG_ 2365473278 TractorFrontFogLightsCmd 2387;
BA_ "SAEDocument" SG_ 2365473278 TractorFrontFogLightsCmd "J1939-71";
BA_ "SigType" SG_ 2365473278 HighBeamHeadLightCmd 5;
BA_ "SPN" SG_ 2365473278 HighBeamHeadLightCmd 2347;
BA_ "SAEDocument" SG_ 2365473278 HighBeamHeadLightCmd "J1939-71";
BA_ "SigType" SG_ 2365473278 LowBeamHeadLightCmd 5;
BA_ "SPN" SG_ 2365473278 LowBeamHeadLightCmd 2349;
BA_ "SAEDocument" SG_ 2365473278 LowBeamHeadLightCmd "J1939-71";
BA_ "SigType" SG_ 2365473278 AltBeamHeadLightCmd 5;
BA_ "SPN" SG_ 2365473278 AltBeamHeadLightCmd 2351;
BA_ "SAEDocument" SG_ 2365473278 AltBeamHeadLightCmd "J1939-71";
BA_ "SigType" SG_ 2365473278 RunningLightCmd 5;
BA_ "SPN" SG_ 2365473278 RunningLightCmd 2403;
BA_ "SAEDocument" SG_ 2365473278 RunningLightCmd "J1939-71";
BA_ "SigType" SG_ 2365485822 LandLevelingSystemEnableStatus 5;
BA_ "SPN" SG_ 2365485822 LandLevelingSystemEnableStatus 5409;
BA_ "SAEDocument" SG_ 2365485822 LandLevelingSystemEnableStatus "J1939-71";
BA_ "SPN" SG_ 2365485822 BladeCtrlModeRight 5408;
BA_ "SAEDocument" SG_ 2365485822 BladeCtrlModeRight "J1939-71";
BA_ "SPN" SG_ 2365485822 BladeCtrlModeLeft 5407;
BA_ "SAEDocument" SG_ 2365485822 BladeCtrlModeLeft "J1939-71";
BA_ "SPN" SG_ 2365485822 BladeCtrlMode 1578;
BA_ "SAEDocument" SG_ 2365485822 BladeCtrlMode "J1939-71";
BA_ "SPN" SG_ 2365485822 BladeDurationAndDirection 1577;
BA_ "SAEDocument" SG_ 2365485822 BladeDurationAndDirection "J1939-71";
BA_ "SPN" SG_ 2633926654 EngActualIgntTiming 1436;
BA_ "SAEDocument" SG_ 2633926654 EngActualIgntTiming "J1939-71";
BA_ "SPN" SG_ 2633926654 EngDesiredIgntTiming3 1435;
BA_ "SAEDocument" SG_ 2633926654 EngDesiredIgntTiming3 "J1939-71";
BA_ "SPN" SG_ 2633926654 EngDesiredIgntTiming2 1434;
BA_ "SAEDocument" SG_ 2633926654 EngDesiredIgntTiming2 "J1939-71";
BA_ "SPN" SG_ 2633926654 EngDesiredIgntTiming1 1433;
BA_ "SAEDocument" SG_ 2633926654 EngDesiredIgntTiming1 "J1939-71";
BA_ "SPN" SG_ 2633926398 EngCyl20IgntTiming 1432;
BA_ "SAEDocument" SG_ 2633926398 EngCyl20IgntTiming "J1939-71";
BA_ "SPN" SG_ 2633926398 EngCyl19IgntTiming 1431;
BA_ "SAEDocument" SG_ 2633926398 EngCyl19IgntTiming "J1939-71";
BA_ "SPN" SG_ 2633926398 EngCyl18IgntTiming 1430;
BA_ "SAEDocument" SG_ 2633926398 EngCyl18IgntTiming "J1939-71";
BA_ "SPN" SG_ 2633926398 EngCyl17IgntTiming 1429;
BA_ "SAEDocument" SG_ 2633926398 EngCyl17IgntTiming "J1939-71";
BA_ "SPN" SG_ 2633926142 EngCyl16IgntTiming 1428;
BA_ "SAEDocument" SG_ 2633926142 EngCyl16IgntTiming "J1939-71";
BA_ "SPN" SG_ 2633926142 EngCyl15IgntTiming 1427;
BA_ "SAEDocument" SG_ 2633926142 EngCyl15IgntTiming "J1939-71";
BA_ "SPN" SG_ 2633926142 EngCyl14IgntTiming 1426;
BA_ "SAEDocument" SG_ 2633926142 EngCyl14IgntTiming "J1939-71";
BA_ "SPN" SG_ 2633926142 EngCyl13IgntTiming 1425;
BA_ "SAEDocument" SG_ 2633926142 EngCyl13IgntTiming "J1939-71";
BA_ "SPN" SG_ 2633925886 EngCyl12IgntTiming 1424;
BA_ "SAEDocument" SG_ 2633925886 EngCyl12IgntTiming "J1939-71";
BA_ "SPN" SG_ 2633925886 EngCyl11IgntTiming 1423;
BA_ "SAEDocument" SG_ 2633925886 EngCyl11IgntTiming "J1939-71";
BA_ "SPN" SG_ 2633925886 EngCyl10IgntTiming 1422;
BA_ "SAEDocument" SG_ 2633925886 EngCyl10IgntTiming "J1939-71";
BA_ "SPN" SG_ 2633925886 EngCyl9IgntTiming 1421;
BA_ "SAEDocument" SG_ 2633925886 EngCyl9IgntTiming "J1939-71";
BA_ "SPN" SG_ 2633925630 EngCyl8IgntTiming 1420;
BA_ "SAEDocument" SG_ 2633925630 EngCyl8IgntTiming "J1939-71";
BA_ "SPN" SG_ 2633925630 EngCyl7IgntTiming 1419;
BA_ "SAEDocument" SG_ 2633925630 EngCyl7IgntTiming "J1939-71";
BA_ "SPN" SG_ 2633925630 EngCyl6IgntTiming 1418;
BA_ "SAEDocument" SG_ 2633925630 EngCyl6IgntTiming "J1939-71";
BA_ "SPN" SG_ 2633925630 EngCyl5IgntTiming 1417;
BA_ "SAEDocument" SG_ 2633925630 EngCyl5IgntTiming "J1939-71";
BA_ "SPN" SG_ 2633925374 EngCyl4IgntTiming 1416;
BA_ "SAEDocument" SG_ 2633925374 EngCyl4IgntTiming "J1939-71";
BA_ "SPN" SG_ 2633925374 EngCyl3IgntTiming 1415;
BA_ "SAEDocument" SG_ 2633925374 EngCyl3IgntTiming "J1939-71";
BA_ "SPN" SG_ 2633925374 EngCyl2IgntTiming 1414;
BA_ "SAEDocument" SG_ 2633925374 EngCyl2IgntTiming "J1939-71";
BA_ "SPN" SG_ 2633925374 EngCyl1IgntTiming 1413;
BA_ "SAEDocument" SG_ 2633925374 EngCyl1IgntTiming "J1939-71";
BA_ "SigType" SG_ 2633927422 EngCyl20IgntTransSecondOutput 1;
BA_ "SPN" SG_ 2633927422 EngCyl20IgntTransSecondOutput 1412;
BA_ "SAEDocument" SG_ 2633927422 EngCyl20IgntTransSecondOutput "J1939-71";
BA_ "SigType" SG_ 2633927422 EngCyl19IgntTransSecondOutput 1;
BA_ "SPN" SG_ 2633927422 EngCyl19IgntTransSecondOutput 1411;
BA_ "SAEDocument" SG_ 2633927422 EngCyl19IgntTransSecondOutput "J1939-71";
BA_ "SigType" SG_ 2633927422 EngCyl18IgntTransSecondOutput 1;
BA_ "SPN" SG_ 2633927422 EngCyl18IgntTransSecondOutput 1410;
BA_ "SAEDocument" SG_ 2633927422 EngCyl18IgntTransSecondOutput "J1939-71";
BA_ "SigType" SG_ 2633927422 EngCyl17IgntTransSecondOutput 1;
BA_ "SPN" SG_ 2633927422 EngCyl17IgntTransSecondOutput 1409;
BA_ "SAEDocument" SG_ 2633927422 EngCyl17IgntTransSecondOutput "J1939-71";
BA_ "SigType" SG_ 2633927166 EngCyl16IgntTransSecondOutput 1;
BA_ "SPN" SG_ 2633927166 EngCyl16IgntTransSecondOutput 1408;
BA_ "SAEDocument" SG_ 2633927166 EngCyl16IgntTransSecondOutput "J1939-71";
BA_ "SigType" SG_ 2633927166 EngCyl15IgntTransSecondOutput 1;
BA_ "SPN" SG_ 2633927166 EngCyl15IgntTransSecondOutput 1407;
BA_ "SAEDocument" SG_ 2633927166 EngCyl15IgntTransSecondOutput "J1939-71";
BA_ "SigType" SG_ 2633927166 EngCyl14IgntTransSecondOutput 1;
BA_ "SPN" SG_ 2633927166 EngCyl14IgntTransSecondOutput 1406;
BA_ "SAEDocument" SG_ 2633927166 EngCyl14IgntTransSecondOutput "J1939-71";
BA_ "SigType" SG_ 2633927166 EngCyl13IgntTransSecondOutput 1;
BA_ "SPN" SG_ 2633927166 EngCyl13IgntTransSecondOutput 1405;
BA_ "SAEDocument" SG_ 2633927166 EngCyl13IgntTransSecondOutput "J1939-71";
BA_ "SigType" SG_ 2633927166 EngCyl12IgntTransSecondOutput 1;
BA_ "SPN" SG_ 2633927166 EngCyl12IgntTransSecondOutput 1404;
BA_ "SAEDocument" SG_ 2633927166 EngCyl12IgntTransSecondOutput "J1939-71";
BA_ "SigType" SG_ 2633927166 EngCyl11IgntTransSecondOutput 1;
BA_ "SPN" SG_ 2633927166 EngCyl11IgntTransSecondOutput 1403;
BA_ "SAEDocument" SG_ 2633927166 EngCyl11IgntTransSecondOutput "J1939-71";
BA_ "SigType" SG_ 2633927166 EngCyl10IgntTransSecondOutput 1;
BA_ "SPN" SG_ 2633927166 EngCyl10IgntTransSecondOutput 1402;
BA_ "SAEDocument" SG_ 2633927166 EngCyl10IgntTransSecondOutput "J1939-71";
BA_ "SigType" SG_ 2633927166 EngCyl9IgntTransSecondOutput 1;
BA_ "SPN" SG_ 2633927166 EngCyl9IgntTransSecondOutput 1401;
BA_ "SAEDocument" SG_ 2633927166 EngCyl9IgntTransSecondOutput "J1939-71";
BA_ "SigType" SG_ 2633926910 EngCyl8IgntTransSecondOutput 1;
BA_ "SPN" SG_ 2633926910 EngCyl8IgntTransSecondOutput 1400;
BA_ "SAEDocument" SG_ 2633926910 EngCyl8IgntTransSecondOutput "J1939-71";
BA_ "SigType" SG_ 2633926910 EngCyl7IgntTransSecondOutput 1;
BA_ "SPN" SG_ 2633926910 EngCyl7IgntTransSecondOutput 1399;
BA_ "SAEDocument" SG_ 2633926910 EngCyl7IgntTransSecondOutput "J1939-71";
BA_ "SigType" SG_ 2633926910 EngCyl6IgntTransSecondOutput 1;
BA_ "SPN" SG_ 2633926910 EngCyl6IgntTransSecondOutput 1398;
BA_ "SAEDocument" SG_ 2633926910 EngCyl6IgntTransSecondOutput "J1939-71";
BA_ "SigType" SG_ 2633926910 EngCyl5IgntTransSecondOutput 1;
BA_ "SPN" SG_ 2633926910 EngCyl5IgntTransSecondOutput 1397;
BA_ "SAEDocument" SG_ 2633926910 EngCyl5IgntTransSecondOutput "J1939-71";
BA_ "SigType" SG_ 2633926910 EngCyl4IgntTransSecondOutput 1;
BA_ "SPN" SG_ 2633926910 EngCyl4IgntTransSecondOutput 1396;
BA_ "SAEDocument" SG_ 2633926910 EngCyl4IgntTransSecondOutput "J1939-71";
BA_ "SigType" SG_ 2633926910 EngCyl3IgntTransSecondOutput 1;
BA_ "SPN" SG_ 2633926910 EngCyl3IgntTransSecondOutput 1395;
BA_ "SAEDocument" SG_ 2633926910 EngCyl3IgntTransSecondOutput "J1939-71";
BA_ "SigType" SG_ 2633926910 EngCyl2IgntTransSecondOutput 1;
BA_ "SPN" SG_ 2633926910 EngCyl2IgntTransSecondOutput 1394;
BA_ "SAEDocument" SG_ 2633926910 EngCyl2IgntTransSecondOutput "J1939-71";
BA_ "SigType" SG_ 2633926910 EngCyl1IgntTransSecondOutput 1;
BA_ "SPN" SG_ 2633926910 EngCyl1IgntTransSecondOutput 1393;
BA_ "SAEDocument" SG_ 2633926910 EngCyl1IgntTransSecondOutput "J1939-71";
BA_ "SPN" SG_ 2566768894 EngOprtrPrmryIntrmdtSpdSlctState 2892;
BA_ "SAEDocument" SG_ 2566768894 EngOprtrPrmryIntrmdtSpdSlctState "J1939-71";
BA_ "SPN" SG_ 2566769406 EngOprtrPrmryIntrmdteSpeedSelect 2880;
BA_ "SAEDocument" SG_ 2566769406 EngOprtrPrmryIntrmdteSpeedSelect "J1939-71";
BA_ "SigType" SG_ 2566839550 EngTotalIdleHours 1;
BA_ "SPN" SG_ 2566839550 EngTotalIdleHours 235;
BA_ "SAEDocument" SG_ 2566839550 EngTotalIdleHours "J1939-71";
BA_ "SigType" SG_ 2566839550 EngTotalIdleFuelUsed 1;
BA_ "SPN" SG_ 2566839550 EngTotalIdleFuelUsed 236;
BA_ "SAEDocument" SG_ 2566839550 EngTotalIdleFuelUsed "J1939-71";
BA_ "SigType" SG_ 2633934334 EngIntakeManifold6Temp 1;
BA_ "SPN" SG_ 2633934334 EngIntakeManifold6Temp 1803;
BA_ "SAEDocument" SG_ 2633934334 EngIntakeManifold6Temp "J1939-71";
BA_ "SigType" SG_ 2633934334 EngIntakeManifold5Temp 1;
BA_ "SPN" SG_ 2633934334 EngIntakeManifold5Temp 1802;
BA_ "SAEDocument" SG_ 2633934334 EngIntakeManifold5Temp "J1939-71";
BA_ "SigType" SG_ 2633934334 EngIntakeManifold4Temp 1;
BA_ "SPN" SG_ 2633934334 EngIntakeManifold4Temp 1133;
BA_ "SAEDocument" SG_ 2633934334 EngIntakeManifold4Temp "J1939-71";
BA_ "SigType" SG_ 2633934334 EngIntakeManifold3Temp 1;
BA_ "SPN" SG_ 2633934334 EngIntakeManifold3Temp 1132;
BA_ "SAEDocument" SG_ 2633934334 EngIntakeManifold3Temp "J1939-71";
BA_ "SigType" SG_ 2633934334 EngIntakeManifold2Temp 1;
BA_ "SPN" SG_ 2633934334 EngIntakeManifold2Temp 1131;
BA_ "SAEDocument" SG_ 2633934334 EngIntakeManifold2Temp "J1939-71";
BA_ "SigType" SG_ 2566825726 EngTurbo4BoostPress 1;
BA_ "SPN" SG_ 2566825726 EngTurbo4BoostPress 1130;
BA_ "SAEDocument" SG_ 2566825726 EngTurbo4BoostPress "J1939-71";
BA_ "SigType" SG_ 2566825726 EngTurbo3BoostPress 1;
BA_ "SPN" SG_ 2566825726 EngTurbo3BoostPress 1129;
BA_ "SAEDocument" SG_ 2566825726 EngTurbo3BoostPress "J1939-71";
BA_ "SigType" SG_ 2566825726 EngTurbo2BoostPress 1;
BA_ "SPN" SG_ 2566825726 EngTurbo2BoostPress 1128;
BA_ "SAEDocument" SG_ 2566825726 EngTurbo2BoostPress "J1939-71";
BA_ "SigType" SG_ 2566825726 EngTurbo1BoostPress 1;
BA_ "SPN" SG_ 2566825726 EngTurbo1BoostPress 1127;
BA_ "SAEDocument" SG_ 2566825726 EngTurbo1BoostPress "J1939-71";
BA_ "SigType" SG_ 2566770942 EngIntakeManifold2AbsPress 1;
BA_ "SPN" SG_ 2566770942 EngIntakeManifold2AbsPress 5422;
BA_ "SAEDocument" SG_ 2566770942 EngIntakeManifold2AbsPress "J1939-71";
BA_ "SigType" SG_ 2566770942 EngIntakeManifold1AbsPress_01 1;
BA_ "SPN" SG_ 2566770942 EngIntakeManifold1AbsPress_01 3563;
BA_ "SAEDocument" SG_ 2566770942 EngIntakeManifold1AbsPress_01 "J1939-71";
BA_ "SigType" SG_ 2566770942 EngIntakeManifold2Press 1;
BA_ "SPN" SG_ 2566770942 EngIntakeManifold2Press 3562;
BA_ "SAEDocument" SG_ 2566770942 EngIntakeManifold2Press "J1939-71";
BA_ "SigType" SG_ 2566770942 EngAirFilter4DiffPress 1;
BA_ "SPN" SG_ 2566770942 EngAirFilter4DiffPress 2811;
BA_ "SAEDocument" SG_ 2566770942 EngAirFilter4DiffPress "J1939-71";
BA_ "SigType" SG_ 2566770942 EngAirFilter3DiffPress 1;
BA_ "SPN" SG_ 2566770942 EngAirFilter3DiffPress 2810;
BA_ "SAEDocument" SG_ 2566770942 EngAirFilter3DiffPress "J1939-71";
BA_ "SigType" SG_ 2566770942 EngAirFilter2DiffPress 1;
BA_ "SPN" SG_ 2566770942 EngAirFilter2DiffPress 2809;
BA_ "SAEDocument" SG_ 2566770942 EngAirFilter2DiffPress "J1939-71";
BA_ "SigType" SG_ 2566846206 EngCoolantFilterDiffPress 1;
BA_ "SPN" SG_ 2566846206 EngCoolantFilterDiffPress 112;
BA_ "SAEDocument" SG_ 2566846206 EngCoolantFilterDiffPress "J1939-71";
BA_ "SigType" SG_ 2566846206 EngExhaustGasTemp 1;
BA_ "SPN" SG_ 2566846206 EngExhaustGasTemp 173;
BA_ "SAEDocument" SG_ 2566846206 EngExhaustGasTemp "J1939-71";
BA_ "SigType" SG_ 2566846206 EngAirFilter1DiffPress 1;
BA_ "SPN" SG_ 2566846206 EngAirFilter1DiffPress 107;
BA_ "SAEDocument" SG_ 2566846206 EngAirFilter1DiffPress "J1939-71";
BA_ "SigType" SG_ 2566846206 EngIntakeManifold1Temp 1;
BA_ "SPN" SG_ 2566846206 EngIntakeManifold1Temp 105;
BA_ "SAEDocument" SG_ 2566846206 EngIntakeManifold1Temp "J1939-71";
BA_ "SigType" SG_ 2566846206 EngIntakeManifold1Press 1;
BA_ "SPN" SG_ 2566846206 EngIntakeManifold1Press 102;
BA_ "SAEDocument" SG_ 2566846206 EngIntakeManifold1Press "J1939-71";
BA_ "SigType" SG_ 2566846206 EngDslPrtculateFilterIntakePress 1;
BA_ "SPN" SG_ 2566846206 EngDslPrtculateFilterIntakePress 81;
BA_ "SAEDocument" SG_ 2566846206 EngDslPrtculateFilterIntakePress "J1939-71";
BA_ "SigType" SG_ 2566846206 EngAirIntakePress 1;
BA_ "SPN" SG_ 2566846206 EngAirIntakePress 106;
BA_ "SAEDocument" SG_ 2566846206 EngAirIntakePress "J1939-71";
BA_ "SigType" SG_ 2566811134 CabHeatingZone 5;
BA_ "SPN" SG_ 2566811134 CabHeatingZone 1680;
BA_ "SAEDocument" SG_ 2566811134 CabHeatingZone "J1939-71";
BA_ "SigType" SG_ 2566811134 EngHeatingZone 5;
BA_ "SPN" SG_ 2566811134 EngHeatingZone 1679;
BA_ "SAEDocument" SG_ 2566811134 EngHeatingZone "J1939-71";
BA_ "SigType" SG_ 2566811134 CabVentilation 5;
BA_ "SPN" SG_ 2566811134 CabVentilation 1678;
BA_ "SAEDocument" SG_ 2566811134 CabVentilation "J1939-71";
BA_ "SigType" SG_ 2566811134 AuxHeaterWaterPumpStatus 5;
BA_ "SPN" SG_ 2566811134 AuxHeaterWaterPumpStatus 1676;
BA_ "SAEDocument" SG_ 2566811134 AuxHeaterWaterPumpStatus "J1939-71";
BA_ "SPN" SG_ 2566811134 AuxHeaterMode 1677;
BA_ "SAEDocument" SG_ 2566811134 AuxHeaterMode "J1939-71";
BA_ "SigType" SG_ 2566811134 AuxHeaterOutputPowerPercent 1;
BA_ "SPN" SG_ 2566811134 AuxHeaterOutputPowerPercent 1689;
BA_ "SAEDocument" SG_ 2566811134 AuxHeaterOutputPowerPercent "J1939-71";
BA_ "SigType" SG_ 2566811134 AuxHeaterInputAirTemp 1;
BA_ "SPN" SG_ 2566811134 AuxHeaterInputAirTemp 1688;
BA_ "SAEDocument" SG_ 2566811134 AuxHeaterInputAirTemp "J1939-71";
BA_ "SigType" SG_ 2566811134 AuxHeaterOutputCoolantTemp 1;
BA_ "SPN" SG_ 2566811134 AuxHeaterOutputCoolantTemp 1687;
BA_ "SAEDocument" SG_ 2566811134 AuxHeaterOutputCoolantTemp "J1939-71";
BA_ "SigType" SG_ 2298375934 RearAxleRightWheelSpeed 1;
BA_ "SPN" SG_ 2298375934 RearAxleRightWheelSpeed 1595;
BA_ "SAEDocument" SG_ 2298375934 RearAxleRightWheelSpeed "J1939-71";
BA_ "SigType" SG_ 2298375934 RearAxleLeftWheelSpeed 1;
BA_ "SPN" SG_ 2298375934 RearAxleLeftWheelSpeed 1594;
BA_ "SAEDocument" SG_ 2298375934 RearAxleLeftWheelSpeed "J1939-71";
BA_ "SigType" SG_ 2298375934 FrontAxleRightWheelSpeed 1;
BA_ "SPN" SG_ 2298375934 FrontAxleRightWheelSpeed 1593;
BA_ "SAEDocument" SG_ 2298375934 FrontAxleRightWheelSpeed "J1939-71";
BA_ "SigType" SG_ 2298375934 FrontAxleLeftWheelSpeed 1;
BA_ "SPN" SG_ 2298375934 FrontAxleLeftWheelSpeed 1592;
BA_ "SAEDocument" SG_ 2298375934 FrontAxleLeftWheelSpeed "J1939-71";
BA_ "SigType" SG_ 2565867774 FireApparatusPumpEngagement 4;
BA_ "SPN" SG_ 2565867774 FireApparatusPumpEngagement 2599;
BA_ "SAEDocument" SG_ 2565867774 FireApparatusPumpEngagement "J1939-71";
BA_ "SigType" SG_ 2565867774 EngHydPressGovernorSwitch 4;
BA_ "SPN" SG_ 2565867774 EngHydPressGovernorSwitch 1764;
BA_ "SAEDocument" SG_ 2565867774 EngHydPressGovernorSwitch "J1939-71";
BA_ "SigType" SG_ 2565867774 EngHydPressGovernorModeIndicator 5;
BA_ "SPN" SG_ 2565867774 EngHydPressGovernorModeIndicator 1763;
BA_ "SAEDocument" SG_ 2565867774 EngHydPressGovernorModeIndicator "J1939-71";
BA_ "SigType" SG_ 2565867774 HydPress 1;
BA_ "SPN" SG_ 2565867774 HydPress 1762;
BA_ "SAEDocument" SG_ 2565867774 HydPress "J1939-71";
BA_ "SigType" SG_ 2566841854 EngTotalRevolutions 1;
BA_ "SPN" SG_ 2566841854 EngTotalRevolutions 249;
BA_ "SAEDocument" SG_ 2566841854 EngTotalRevolutions "J1939-71";
BA_ "SigType" SG_ 2566841854 EngTotalHoursOfOperation 1;
BA_ "SPN" SG_ 2566841854 EngTotalHoursOfOperation 247;
BA_ "SAEDocument" SG_ 2566841854 EngTotalHoursOfOperation "J1939-71";
BA_ "SigType" SG_ 2365449982 HydBrakeFluidLevelSwitch 4;
BA_ "SPN" SG_ 2365449982 HydBrakeFluidLevelSwitch 2931;
BA_ "SAEDocument" SG_ 2365449982 HydBrakeFluidLevelSwitch "J1939-71";
BA_ "SigType" SG_ 2365449982 HydBrakeSystemAudibleWarningCmd 5;
BA_ "SPN" SG_ 2365449982 HydBrakeSystemAudibleWarningCmd 2930;
BA_ "SAEDocument" SG_ 2365449982 HydBrakeSystemAudibleWarningCmd "J1939-71";
BA_ "SigType" SG_ 2365449982 HydBrakePressSupplyStateCircuit2 4;
BA_ "SPN" SG_ 2365449982 HydBrakePressSupplyStateCircuit2 2583;
BA_ "SAEDocument" SG_ 2365449982 HydBrakePressSupplyStateCircuit2 "J1939-71";
BA_ "SigType" SG_ 2365449982 HydBrakePressSupplyStateCircuit1 4;
BA_ "SPN" SG_ 2365449982 HydBrakePressSupplyStateCircuit1 2582;
BA_ "SAEDocument" SG_ 2365449982 HydBrakePressSupplyStateCircuit1 "J1939-71";
BA_ "SigType" SG_ 2365449982 HydBrkePressWarningStateCircuit2 4;
BA_ "SPN" SG_ 2365449982 HydBrkePressWarningStateCircuit2 2585;
BA_ "SAEDocument" SG_ 2365449982 HydBrkePressWarningStateCircuit2 "J1939-71";
BA_ "SigType" SG_ 2365449982 HydBrkePressWarningStateCircuit1 4;
BA_ "SPN" SG_ 2365449982 HydBrkePressWarningStateCircuit1 2584;
BA_ "SAEDocument" SG_ 2365449982 HydBrkePressWarningStateCircuit1 "J1939-71";
BA_ "SigType" SG_ 2365449982 HydBrakePressCircuit2 1;
BA_ "SPN" SG_ 2365449982 HydBrakePressCircuit2 2581;
BA_ "SAEDocument" SG_ 2365449982 HydBrakePressCircuit2 "J1939-71";
BA_ "SigType" SG_ 2365449982 HydBrakePressCircuit1 1;
BA_ "SPN" SG_ 2365449982 HydBrakePressCircuit1 2580;
BA_ "SAEDocument" SG_ 2365449982 HydBrakePressCircuit1 "J1939-71";
VAL_ 2365403134 Jystick4GripXAxisDetentPosStatus 3 "Not Available" 2 "Error Indicator" 1 "In the Detent Position" 0 "Not in the Detent Position" ;
VAL_ 2365403134 Jystick4GripYAxisDetentPosStatus 3 "Not Available" 2 "Error Indicator" 1 "In the Detent Position" 0 "Not in the Detent Position" ;
VAL_ 2365403134 Jystick4ThetaAxisDetentPosStatus 3 "Not Available" 2 "Error Indicator" 1 "In the Detent Position" 0 "Not in the Detent Position" ;
VAL_ 2365403134 Jystck4ThtAxsClckwsPstvPosStatus 3 "Not Available" 2 "Error Indicator" 1 "On positive side of Neutral" 0 "Not on Positive side of Neutral" ;
VAL_ 2365403134 Jystck4ThtAxsCntrClckwsNgtvPsStt 3 "Not Available" 2 "Error Indicator" 1 "On negative side of Neutral" 0 "Not on negative side of Neutral" ;
VAL_ 2365403134 Jystck4ThetaAxisNeutralPosStatus 3 "Not Available" 2 "Error Indicator" 1 "In Neutral Position" 0 "Not in Neutral Position" ;
VAL_ 2365403134 Jystck4GrpYAxsLvrFrwrdPstvPsStts 3 "Not Available" 2 "Error Indicator" 1 "On positive side of Neutral" 0 "Not on Positive side of Neutral" ;
VAL_ 2365403134 Jystck4GrpYAxsLvrBckNgtvPsStatus 3 "Not Available" 2 "Error Indicator" 1 "On negative side of Neutral" 0 "Not on negative side of Neutral" ;
VAL_ 2365403134 Jystck4GripYAxisNeutralPosStatus 3 "Not Available" 2 "Error Indicator" 1 "In Neutral Position" 0 "Not in Neutral Position" ;
VAL_ 2365403134 Jystck4GrpXAxsLvrRghtPstvPsSttus 3 "Not Available" 2 "Error Indicator" 1 "On positive side of Neutral" 0 "Not on Positive side of Neutral" ;
VAL_ 2365403134 Jystck4GrpXAxsLvrLftNgtvPsStatus 3 "Not Available" 2 "Error Indicator" 1 "On negative side of Neutral" 0 "Not on negative side of Neutral" ;
VAL_ 2365403134 Jystck4GripXAxisNeutralPosStatus 3 "Not Available" 2 "Error Indicator" 1 "In Neutral Position" 0 "Not in Neutral Position" ;
VAL_ 2365400062 Jystck10GripXAxisDetentPosStatus 3 "Not Available" 2 "Error Indicator" 1 "In the Detent Position" 0 "Not in the Detent Position" ;
VAL_ 2365400062 Jystck10GripYAxisDetentPosStatus 3 "Not Available" 2 "Error Indicator" 1 "In the Detent Position" 0 "Not in the Detent Position" ;
VAL_ 2365400062 Jystck10ThetaAxisDetentPosStatus 3 "Not Available" 2 "Error Indicator" 1 "In the Detent Position" 0 "Not in the Detent Position" ;
VAL_ 2365400062 Jystck10ThtAxsClckwsPstvPsStatus 3 "Not Available" 2 "Error Indicator" 1 "On positive side of Neutral" 0 "Not on Positive side of Neutral" ;
VAL_ 2365400062 Jystck10ThtAxsCntrClckwsNgtvPsSt 3 "Not Available" 2 "Error Indicator" 1 "On negative side of Neutral" 0 "Not on negative side of Neutral" ;
VAL_ 2365400062 Jystck10ThtaAxisNeutralPosStatus 3 "Not Available" 2 "Error Indicator" 1 "In Neutral Position" 0 "Not in Neutral Position" ;
VAL_ 2365400062 Jystck10GrpYAxsLvrFrwrdPstvPsStt 3 "Not Available" 2 "Error Indicator" 1 "On positive side of Neutral" 0 "Not on Positive side of Neutral" ;
VAL_ 2365400062 Jystck10GrpYAxsLvrBckNgtvPsSttus 3 "Not Available" 2 "Error Indicator" 1 "On negative side of Neutral" 0 "Not on negative side of Neutral" ;
VAL_ 2365400062 Jystck10GrpYAxisNeutralPosStatus 3 "Not Available" 2 "Error Indicator" 1 "In Neutral Position" 0 "Not in Neutral Position" ;
VAL_ 2365400062 Jystck10GrpXAxsLvrRghtPstvPsStts 3 "Not Available" 2 "Error Indicator" 1 "On positive side of Neutral" 0 "Not on Positive side of Neutral" ;
VAL_ 2365400062 Jystck10GrpXAxsLvrLftNgtvPsSttus 3 "Not Available" 2 "Error Indicator" 1 "On negative side of Neutral" 0 "Not on negative side of Neutral" ;
VAL_ 2365400062 Jystck10GrpXAxisNeutralPosStatus 3 "Not Available" 2 "Error Indicator" 1 "In Neutral Position" 0 "Not in Neutral Position" ;
VAL_ 2566749438 DslPrtcltFltrActvRgnrtnFrcdSttus 5 "Reserved for SAE Assignment" 4 "Reserved for SAE Assignment" 7 "not available" 6 "Reserved for SAE Assignment" 2 "Active  Forced by Service Tool" 3 "Reserved for SAE Assignment" 1 "Active  Forced by Switch See SPN 3696" 0 "Not Active" ;
VAL_ 2566749438 ExhaustSystemHighTempLampCmd 7 "not available" 6 "reserved for SAE assignment" 1 "On  solid" 0 "Off" 5 "reserved for SAE assignment" 4 "reserved for SAE assignment" 3 "reserved for SAE assignment" 2 "reserved for SAE assignment" ;
VAL_ 2566749438 DslPrtcltFltrAtmtcActvRgnrtnIntt 3 "not available" 2 "reserved for SAE assignment" 1 "enabled" 0 "not enabled" ;
VAL_ 2566749438 DslPrtcltFltrActvRgnrtnInhbtdDTV 3 "notAvailable" 2 "reservedForSAEAssignment" 1 "inhibited" 0 "notInhibited" ;
VAL_ 2566749438 DslPrtcltFltrActvRgnrtnInhbtdDTE 3 "notAvailable" 2 "reservedForSAEAssignment" 1 "inhibited" 0 "notInhibited" ;
VAL_ 2566749438 DslPrtcltFltrActvRgnrtnInhb_0000 3 "notAvailable" 2 "reservedForSAEAssignment" 1 "inhibited" 0 "notInhibited" ;
VAL_ 2566749438 DslPrtcltFltrActvRgnrtnInhbtdDTT 3 "not available" 2 "reserved for SAE assignment" 1 "inhibited" 0 "not inhibited" ;
VAL_ 2566749438 DslPrtcltFltrActvRgnrtn_DTS_02 3 "not available" 2 "reserved for SAE assignment" 1 "inhibited" 0 "not inhibited" ;
VAL_ 2566749438 DslPrtcltFltrActvRgnrtnInhbtdDTL 3 "not available" 2 "reserved for SAE assignment" 1 "inhibited" 0 "not inhibited" ;
VAL_ 2566749438 DslPrtcltFltrActvRgnrtnInhb_0001 3 "notAvailable" 2 "reservedForSAEAssignment" 1 "inhibited" 0 "notInhibited" ;
VAL_ 2566749438 DslPrtcltFltrActvRgnrtnInhb_0002 3 "notAvailable" 2 "reservedForSAEAssignment" 1 "inhibited" 0 "notInhibited" ;
VAL_ 2566749438 DslPrtcltFltrActvRgnrtnInhbtdDTO 3 "notAvailable" 2 "reservedForSAEAssignment" 1 "inhibited" 0 "notInhibited" ;
VAL_ 2566749438 DslPrtcltFltrActvRgnrtnInhbtdDTA 3 "not available" 2 "reserved for SAE assignment" 1 "inhibited" 0 "not inhibited" ;
VAL_ 2566749438 DslPrtcltFltrActvRgnrtnInhbtdDTP 3 "not available" 2 "reserved for SAE assignment" 1 "inhibited" 0 "not inhibited" ;
VAL_ 2566749438 DslPrtcltFltrActvRgnrtnInhbtdDTC 3 "not available" 2 "reserved for SAE assignment" 1 "inhibited" 0 "not inhibited" ;
VAL_ 2566749438 DslPrtcltFltrActvRgnrtnInhbtdDTI 3 "not available" 2 "reserved for SAE assignment" 1 "inhibited" 0 "not inhibited" ;
VAL_ 2566749438 DslPrtcltFltrActvRgnrtnInhbtdStt 3 "not available" 2 "reserved for SAE assignment" 1 "inhibited" 0 "not inhibited" ;
VAL_ 2566749438 DieselParticulateFilterStatus 7 "not available" 6 "reserved for SAE assignment" 3 "Regeneration needed  highest level" 2 "Regeneration needed  moderate level" 1 "Regeneration needed  lowest level" 0 "Regeneration not needed" 5 "reserved for SAE assignment" 4 "reserved for SAE assignment" ;
VAL_ 2566749438 DslPrtcltFltrActvRgnrationStatus 3 "not available" 2 "regeneration needed  automatically initiated active regeneration imminent" 1 "active" 0 "not active" ;
VAL_ 2566749438 DslPrtcltFltrPssvRgnrationStatus 3 "not available" 2 "reserved for SAE assignment" 1 "active" 0 "not active" ;
VAL_ 2566749438 DieselParticulateFilterLampCmd 7 "not available" 4 "On  fast blink 1 HZ" 6 "reserved for SAE assignment" 1 "On  solid" 0 "Off" 5 "reserved for SAE assignment" 3 "reserved for SAE assignment" 2 "reserved for SAE assignment" ;
VAL_ 2566718718 VehicleBatteryChargingLampData 3 "Not available" 2 "Error" 1 "Lamp activated On" 0 "Lamp deactivated Off" ;
VAL_ 2566718718 VehicleHVACRecirculationLampData 3 "Not available" 2 "Error" 1 "Lamp activated On" 0 "Lamp deactivated Off" ;
VAL_ 2566718718 VehicleAirPressLowLampData 3 "Not available" 2 "Error" 1 "Lamp activated On" 0 "Lamp deactivated Off" ;
VAL_ 2566718718 VehicleFuelLevelLowLampData 3 "Not available" 2 "Error" 1 "Lamp activated On" 0 "Lamp deactivated Off" ;
VAL_ 2566718718 VehicleBatteryVoltageLowLampData 3 "Not available" 2 "Error" 1 "Lamp activated On" 0 "Lamp deactivated Off" ;
VAL_ 2566718974 EngWaitToStartLampData 3 "Not available" 2 "Error" 1 "Lamp active" 0 "Lamp deactive" ;
VAL_ 2566718974 EngFuelFilterRestrictedLampData 3 "Not available" 2 "Error" 1 "Lamp activated On" 0 "Lamp deactivated Off" ;
VAL_ 2566718974 EngAirFilterRestrictionLampData 3 "Not available" 2 "Error" 1 "Lamp activated On" 0 "Lamp deactivated Off" ;
VAL_ 2566718974 EngIdleManagementActiveLampData 3 "Not available" 2 "Error" 1 "Lamp activated On" 0 "Lamp deactivated Off" ;
VAL_ 2566718974 EngCoolantLevelLowLampData 3 "Not available" 2 "Error" 1 "Lamp activated On" 0 "Lamp deactivated Off" ;
VAL_ 2566718974 EngCoolantTempHighLampData 3 "Not available" 2 "Error" 1 "Lamp activated On" 0 "Lamp deactivated Off" ;
VAL_ 2566718974 EngOilPressLowLampData 3 "Not available" 2 "Error" 1 "Lamp activated On" 0 "Lamp deactivated Off" ;
VAL_ 2566718974 CmprssnBrkEnblSwtchIndctrLmpData 3 "Not available" 2 "Error" 1 "Lamp activated On" 0 "Lamp deactivated Off" ;
VAL_ 2566718974 EngBrakeActiveLampData 3 "Not available" 2 "Error" 1 "Lamp activated On" 0 "Lamp deactivated Off" ;
VAL_ 2566718974 OBDMalfunctionIndicatorLampData 3 "Not available" 2 "Error" 1 "Lamp activated On" 0 "Lamp deactivated Off" ;
VAL_ 2566718974 EngRedStopLampData 3 "Not available" 2 "Error" 1 "Lamp activated On" 0 "Lamp deactivated Off" ;
VAL_ 2566718974 EngAmberWarningLampData 3 "Not available" 2 "Error" 1 "Lamp activated On" 0 "Lamp deactivated Off" ;
VAL_ 2566718974 EngProtectLampData 3 "Not available" 2 "Error" 1 "Lamp activated On" 0 "Lamp deactivated Off" ;
VAL_ 2566719230 VehicleBatteryChargingLampCmd 3 "Not available" 2 "Reserved" 1 "Lamp On" 0 "Lamp Off" ;
VAL_ 2566719230 VehicleHVACRecirculationLampCmd 3 "Not available" 2 "Reserved" 1 "Lamp On" 0 "Lamp Off" ;
VAL_ 2566719230 VehicleAirPressLowLampCmd 3 "Not available" 2 "Reserved" 1 "Lamp On" 0 "Lamp Off" ;
VAL_ 2566719230 VehicleFuelLevelLowLampCmd 3 "Not available" 2 "Reserved" 1 "Lamp On" 0 "Lamp Off" ;
VAL_ 2566719230 VehicleBatteryVoltageLowLampCmd 3 "Not available" 2 "Reserved" 1 "Lamp On" 0 "Lamp Off" ;
VAL_ 2560818942 FailureModeIdentifier1 31 "Not available" 19 "Received network data in error" 18 "Below normal (moderately severe)" 17 "Below normal (least severe)" 16 "Above normal (moderately severe)" 15 "Above normal (least severe)" 14 "Special intstructions" 13 "Out of calibration" 12 "Bad intelligent device" 11 "Root cause not known" 10 "Abnormal rate of change" 9 "Abnormal update rate" 8 "Abnormal frequency" 7 "Mechanical system not responding" 6 "Current above normal" 5 "Current below normal" 4 "Voltage below normal" 3 "Voltage above normal" 2 "Data erratic" 1 "Below normal (most severe)" 0 "Above normal (most severe)" ;
VAL_ 2561212158 TextDisplayInstructions 6 "Blink substring" 15 "Not applicable" 1 "Hold display  The presently displayed information should be retained" 0 "Clear display  The displayed information should be deleted or not displayed any more" 5 "Highlight substring" 4 "Overwrite substring  A portion of the presently displayed information is to be overwritten with the transmitted" 3 "Overwrite display  The presently displayed information is to be overwritten with the transmitted information" 2 "Append at end of display  The transmitted information should be displayed at the end of the presently displayed" ;
VAL_ 2566746366 RetractStatusOfRamp5 2 "error" 1 "ramp extended" 0 "ramp retracted" 3 "not available" ;
VAL_ 2566746366 RetractStatusOfRamp4 3 "not available" 2 "error" 1 "ramp extended" 0 "ramp retracted" ;
VAL_ 2566746366 MovementStatusOfRamp5 3 "not available" 2 "error" 1 "ramp being moved" 0 "ramp not being moved" ;
VAL_ 2566746366 MovementStatusOfRamp4 3 "not available" 2 "error" 1 "ramp being moved" 0 "ramp not being moved" ;
VAL_ 2566746366 EnableStatusOfRamp5 3 "not available" 2 "error" 1 "ramp enabled" 0 "ramp disabled" ;
VAL_ 2566746366 EnableStatusOfRamp4 3 "not available" 2 "error" 1 "ramp enabled" 0 "ramp disabled" ;
VAL_ 2566746366 MovementStatusOfRamp3 3 "not available" 2 "error" 1 "ramp being moved" 0 "ramp not being moved" ;
VAL_ 2566746366 EnableStatusOfRamp3 3 "not available" 2 "error" 1 "ramp enabled" 0 "ramp disabled" ;
VAL_ 2566746366 RetractStatusOfRamp3 3 "not available" 2 "error" 1 "ramp extended" 0 "ramp retracted" ;
VAL_ 2566746366 MovementStatusOfRamp2 3 "not available" 2 "error" 1 "ramp being moved" 0 "ramp not being moved" ;
VAL_ 2566746366 EnableStatusOfRamp2 3 "not available" 2 "error" 1 "ramp enabled" 0 "ramp disabled" ;
VAL_ 2566746366 RetractStatusOfRamp2 3 "not available" 2 "error" 1 "ramp extended" 0 "ramp retracted" ;
VAL_ 2566746366 MovementStatusOfRamp1 3 "not available" 2 "error" 1 "ramp being moved" 0 "ramp not being moved" ;
VAL_ 2566746366 EnableStatusOfRamp1 3 "not available" 2 "error" 1 "ramp enabled" 0 "ramp disabled" ;
VAL_ 2566746366 RetractStatusOfRamp1 3 "not available" 2 "error" 1 "ramp extended" 0 "ramp retracted" ;
VAL_ 2561277694 LaneDepartureWarningEnableCmd 3 "Dont care" 2 "Reserved" 1 "Enable Lane Departure Warning" 0 "Disable Lane Departure Warning" ;
VAL_ 2565873150 SteerAngleSensorCalibrated 3 "Not available" 2 "Reserved" 1 "SAS calibrated" 0 "SAS not calibrated" ;
VAL_ 2565873150 SteerAngleSensorActiveMode 3 "Not available" 2 "Reserved" 1 "Normal mode active" 0 "Programming mode active" ;
VAL_ 2565873150 SteerWheelAngleRangeCounterType 3 "signal not available" 2 "not defined" 1 "absolute number of counts" 0 "relative number of counts" ;
VAL_ 2566751230 TransferCaseStatus 7 "not available" 3 "2 wheel low or Off Highway Range" 0 "2 wheel high normal or On Highway Range" 6 "error" 5 "Transfer Case Shift in Progress or gear not confirmed" 4 "4 wheel low or Off Highway Range" 2 "neutral" 1 "4 wheel high normal or On Highway Range" ;
VAL_ 2566755838 TransOverheatIndicator 3 "Not available" 2 "Transmission Overheat Indicator is flashing" 1 "Transmission Overheat Indicator is on continuously" 0 "Transmission Overheat Indicator is off" ;
VAL_ 2566755838 TransOilLevelSwitch 3 "Not available" 2 "Error" 1 "Full or not empty" 0 "Empty" ;
VAL_ 2566755838 TransOilFilterRestrictionSwitch 3 "Not available" 2 "Error" 1 "Restriction exists on oil filter" 0 "No restriction" ;
VAL_ 2566799614 ImplementRearWorkLight 3 "Not Available" 2 "Fault Detected" 1 "Activated" 0 "Deactivated" ;
VAL_ 2566799614 ImplementLeftForwardWorkLight 3 "Not Available" 2 "Fault Detected" 1 "Activated" 0 "Deactivated" ;
VAL_ 2566799614 ImplementRightForwardWorkLight 3 "Not Available" 2 "Fault Detected" 1 "Activated" 0 "Deactivated" ;
VAL_ 2566799614 ImplementLeftFacingWorkLight 3 "Not Available" 2 "Fault Detected" 1 "Activate" 0 "Deactivate" ;
VAL_ 2566799614 ImplementRightFacingWorkLight 3 "Not Available" 2 "Fault Detected" 1 "Activated" 0 "Deactivated" ;
VAL_ 2566799614 ImplementOEMOption1Light 3 "Not Available" 2 "Fault Detected" 1 "Activated" 0 "Deactivated" ;
VAL_ 2566799614 ImplementOEMOption2Light 3 "Not Available" 2 "Fault Detected" 1 "Activated" 0 "Deactivated" ;
VAL_ 2566799614 TrctorFrontHighMountedWorkLights 3 "Not Available" 2 "Fault Detected" 1 "Activated" 0 "Deactivated" ;
VAL_ 2566799614 TractorFrontLowMountedWorkLights 3 "Not Available" 2 "Fault Detected" 1 "Activated" 0 "Deactivated" ;
VAL_ 2566799614 TractorSideHighMountedWorkLights 3 "Not Available" 2 "Fault Detected" 1 "Activated" 0 "Deactivated" ;
VAL_ 2566799614 TractorSideLowMountedWorkLights 3 "Not Available" 2 "Fault Detected" 1 "Activated" 0 "Deactivated" ;
VAL_ 2566799614 TractorRearHighMountedWorkLights 3 "Not Available" 2 "Fault Detected" 1 "Activated" 0 "Deactivated" ;
VAL_ 2566799614 TractorRearLowMountedWorkLights 3 "Not Available" 2 "Fault Detected" 1 "Activated" 0 "Deactivated" ;
VAL_ 2566799614 TrctorUndersideMountedWorkLights 3 "Not Available" 2 "Fault Detected" 1 "Activated" 0 "Deactivated" ;
VAL_ 2566799614 RearFogLights 3 "Not Available" 2 "Fault Detected" 1 "Activated" 0 "Deactivated" ;
VAL_ 2566799614 TractorMarkerLight 3 "Not Available" 2 "Fault Detected" 1 "Activated" 0 "Deactivated" ;
VAL_ 2566799614 ImplementMarkerLight 3 "Not Available" 2 "Fault Detected" 1 "Activated" 0 "Deactivated" ;
VAL_ 2566799614 TractorClearanceLight 3 "Not Available" 2 "Fault Detected" 1 "Activated" 0 "Deactivated" ;
VAL_ 2566799614 ImplementClearanceLight 3 "Not Available" 2 "Fault Detected" 1 "Activated" 0 "Deactivated" ;
VAL_ 2566799614 LeftStopLight 3 "Not Available" 2 "Fault Detected" 1 "Activated" 0 "Deactivated" ;
VAL_ 2566799614 RightStopLight 3 "Not Available" 2 "Fault Detected" 1 "Activated" 0 "Deactivated" ;
VAL_ 2566799614 CenterStopLight 3 "Not Available" 2 "Fault Detected" 1 "Activated" 0 "Deactivated" ;
VAL_ 2566799614 BackUpLightAndAlarmHorn 3 "Not Available" 2 "Fault Detected" 1 "Activated" 0 "Deactivated" ;
VAL_ 2566799614 LeftTurnSignalLights 3 "Not Available" 2 "Fault Detected" 1 "Activated" 0 "Deactivated" ;
VAL_ 2566799614 RightTurnSignalLights 3 "Not Available" 2 "Fault Detected" 1 "Activated" 0 "Deactivated" ;
VAL_ 2566799614 RotatingBeaconLight 3 "Not Available" 2 "Fault Detected" 1 "Activated" 0 "Deactivated" ;
VAL_ 2566799614 TractorFrontFogLights 3 "Not Available" 2 "Fault Detected" 1 "Activated" 0 "Deactivated" ;
VAL_ 2566799614 HighBeamHeadLightData 3 "Not Available" 2 "Fault Detected" 1 "Activated" 0 "Deactivated" ;
VAL_ 2566799614 LowBeamHeadLightData 3 "Not Available" 2 "Fault Detected" 1 "Activated" 0 "Deactivated" ;
VAL_ 2566799614 AltBeamHeadLightData 3 "Not Available" 2 "Fault Detected" 1 "Activated" 0 "Deactivated" ;
VAL_ 2566799614 RunningLight 3 "Not Available" 2 "Fault Detected" 1 "Activated" 0 "Deactivated" ;
VAL_ 2365473278 ImplementRearWorkLightCmd 3 "Dont Care" 2 "Reserved" 1 "Activate" 0 "Deactivate" ;
VAL_ 2365473278 ImplementLeftForwardWorkLightCmd 3 "Dont Care" 2 "Reserved" 1 "Activate" 0 "Deactivate" ;
VAL_ 2365473278 ImplmentRightForwardWorkLightCmd 3 "Dont Care" 2 "Reserved" 1 "Activate" 0 "Deactivate" ;
VAL_ 2365473278 LightingDataRqCmd 3 "Dont Care" 2 "Reserved" 1 "Activate" 0 "Deactivate" ;
VAL_ 2365473278 ImplementLeftFacingWorkLightCmd 3 "Dont Care" 2 "Reserved" 1 "Activate" 0 "Deactivate" ;
VAL_ 2365473278 ImplementRightFacingWorkLightCmd 3 "Dont Care" 2 "Reserved" 1 "Activate" 0 "Deactivate" ;
VAL_ 2365473278 ImplementOEMOption1LightCmd 3 "Dont Care" 2 "Reserved" 1 "Activate" 0 "Deactivate" ;
VAL_ 2365473278 ImplementOEMOption2LightCmd 3 "Dont Care" 2 "Reserved" 1 "Activate" 0 "Deactivate" ;
VAL_ 2365473278 TrctrFrntHghMountedWorkLightsCmd 3 "Dont Care" 2 "Reserved" 1 "Activate" 0 "Deactivate" ;
VAL_ 2365473278 TrctrFrntLowMountedWorkLightsCmd 3 "Dont Care" 2 "Reserved" 1 "Activate" 0 "Deactivate" ;
VAL_ 2365473278 TrctrSdeHighMountedWorkLightsCmd 3 "Dont Care" 2 "Reserved" 1 "Activate" 0 "Deactivate" ;
VAL_ 2365473278 TrctrSideLowMountedWorkLightsCmd 3 "Dont Care" 2 "Reserved" 1 "Activate" 0 "Deactivate" ;
VAL_ 2365473278 TrctrRarHighMountedWorkLightsCmd 3 "Dont Care" 2 "Reserved" 1 "Activate" 0 "Deactivate" ;
VAL_ 2365473278 TrctrRearLowMountedWorkLightsCmd 3 "Dont Care" 2 "Reserved" 1 "Activate" 0 "Deactivate" ;
VAL_ 2365473278 TrctrUndrsdeMountedWorkLightsCmd 3 "Dont Care" 2 "Reserved" 1 "Activate" 0 "Deactivate" ;
VAL_ 2365473278 RearFogLightCmd 3 "Dont Care" 2 "Reserved" 1 "Activate" 0 "Deactivate" ;
VAL_ 2365473278 TractorMarkerLightCmd 3 "Dont Care" 2 "Reserved" 1 "Activate" 0 "Deactivate" ;
VAL_ 2365473278 ImplementMarkerLightCmd 3 "Dont Care" 2 "Reserved" 1 "Activate" 0 "Deactivate" ;
VAL_ 2365473278 TractorClearanceLightCmd 3 "Dont Care" 2 "Reserved" 1 "Activate" 0 "Deactivate" ;
VAL_ 2365473278 ImplementClearanceLightCmd 3 "Dont Care" 2 "Reserved" 1 "Activate" 0 "Deactivate" ;
VAL_ 2365473278 LeftStopLightCmd 3 "Dont Care" 2 "Reserved" 1 "Activate" 0 "Deactivate" ;
VAL_ 2365473278 RightStopLightCmd 3 "Dont Care" 2 "Reserved" 1 "Activate" 0 "Deactivate" ;
VAL_ 2365473278 CenterStopLightCmd 3 "Dont Care" 2 "Reserved" 1 "Activate" 0 "Deactivate" ;
VAL_ 2365473278 BackUpLightAndAlarmHornCmd 3 "Dont Care" 2 "Reserved" 1 "Activate" 0 "Deactivate" ;
VAL_ 2365473278 LeftTurnSignalLightsCmd 3 "Dont Care" 2 "Reserved" 1 "Activate" 0 "Deactivate" ;
VAL_ 2365473278 RightTurnSignalLightsCmd 3 "Dont Care" 2 "Reserved" 1 "Activate" 0 "Deactivate" ;
VAL_ 2365473278 RotatingBeaconLightCmd 3 "Dont Care" 2 "Reserved" 1 "Activate" 0 "Deactivate" ;
VAL_ 2365473278 TractorFrontFogLightsCmd 3 "Dont Care" 2 "Reserved" 1 "Activate" 0 "Deactivate" ;
VAL_ 2365473278 HighBeamHeadLightCmd 3 "Dont Care" 2 "Reserved" 1 "Activate" 0 "Deactivate" ;
VAL_ 2365473278 LowBeamHeadLightCmd 3 "Dont Care" 2 "Reserved" 1 "Activate" 0 "Deactivate" ;
VAL_ 2365473278 AltBeamHeadLightCmd 3 "Dont Care" 2 "Reserved" 1 "Activate" 0 "Deactivate" ;
VAL_ 2365473278 RunningLightCmd 3 "Dont Care" 2 "Reserved" 1 "Activate" 0 "Deactivate" ;
VAL_ 2365485822 LandLevelingSystemEnableStatus 3 "Not available / Not installed" 2 "Error" 0 "Disabled" ;
VAL_ 2365485822 BladeCtrlModeRight 15 "Not Available" 14 "Error" 2 "Inactive Auto" 1 "Auto" 0 "Manual" ;
VAL_ 2365485822 BladeCtrlModeLeft 15 "Not Available" 14 "Error" 2 "Inactive Auto" 1 "Auto" 0 "Manual" ;
VAL_ 2365485822 BladeCtrlMode 2 "Inactive automatic mode" 1 "Automatic mode" 0 "Manual mode" ;
VAL_ 2566768894 EngOprtrPrmryIntrmdtSpdSlctState 15 "not available" 14 "SAE reserved" 1 "thru 1101  Control state is ISC Setting 1 thru 13 in sequential order" 0 "Control state is ISC functionality is not requested engine operates normally" ;
VAL_ 2566769406 EngOprtrPrmryIntrmdteSpeedSelect 15 "not available" 14 "error condition" 1 "thru 1101  indicates that the ISC Setting 1 thru 13 in sequential order is selected" 0 "indicates that the ISC functionality is not requested engine operates normally" ;
VAL_ 2566811134 CabHeatingZone 3 "Not available" 2 "Reserved" 1 "Cab heating zone on" 0 "Cab heating zone off" ;
VAL_ 2566811134 EngHeatingZone 3 "Not available" 2 "Reserved" 1 "Engine heating zone on" 0 "Engine heating zone off" ;
VAL_ 2566811134 CabVentilation 3 "Not available" 2 "Reserved" 1 "Cab is ventilated" 0 "Cab not ventilated" ;
VAL_ 2566811134 AuxHeaterWaterPumpStatus 3 "Not available" 2 "Reserved" 1 "Water Pump is running" 0 "Water Pump is not running" ;
VAL_ 2566811134 AuxHeaterMode 15 "Not available" 14 "Error" 3 "Normal mode" 2 "Economy mode" 1 "Off due to ADR per European Regulations for Transport of hazardous materials" 0 "Heater not active" ;
VAL_ 2565867774 FireApparatusPumpEngagement 3 "Not available or not installed" 2 "Error" 1 "Pump engaged" 0 "Pump not engaged" ;
VAL_ 2565867774 EngHydPressGovernorSwitch 3 "Not Available" 2 "Error Indicator" 1 "Pressure Mode Active" 0 "Pressure Mode Inactive" ;
VAL_ 2565867774 EngHydPressGovernorModeIndicator 3 "Not Available" 2 "Error Indicator" 1 "Enabled" 0 "Disabled" ;
VAL_ 2365449982 HydBrakeFluidLevelSwitch 3 "Not available" 2 "Error indicator" 1 "Fluid level is sufficient" 0 "Fluid level is not sufficient" ;
VAL_ 2365449982 HydBrakeSystemAudibleWarningCmd 3 "Dont care" 2 "Reserved" 1 "Audible warning on" 0 "Audible warning off" ;
VAL_ 2365449982 HydBrakePressSupplyStateCircuit2 3 "Not available" 2 "Error indicator" 1 "Supply is reliable" 0 "Supply is not reliable" ;
VAL_ 2365449982 HydBrakePressSupplyStateCircuit1 3 "Not available" 2 "Error indicator" 1 "Supply is reliable" 0 "Supply is not reliable" ;
VAL_ 2365449982 HydBrkePressWarningStateCircuit2 3 "Not available" 2 "Error indicator" 1 "Pressure level below warning level" 0 "Pressure level sufficient" ;
VAL_ 2365449982 HydBrkePressWarningStateCircuit1 3 "Not available" 2 "Error indicator" 1 "Pressure level below warning level" 0 "Pressure level sufficient" ;
